VERSION ""

NS_ :

BS_:

BU_: APIM_CISM APIM ESPM DSP FCIMB RACM_RCIM HUD_ADV WCM TRM_ITRM ACM GWM _delete IPC GENERIC TSTR

BO_ 412 LBClient2_Request_Signals: 8 APIM
 SG_ LBC2_StartItemInd : 55|16@0+ (1,0) [0|65535] "unitless"  ACM
 SG_ LBC2_SetListServ : 47|8@0+ (1,0) [0|255] "unitless"  ACM
 SG_ LBC2_Opcode : 39|2@0+ (1,0) [0|3] "SED"  ACM
 SG_ LBC2_NbrOfItems : 37|6@0+ (1,0) [0|63] "unitless"  ACM
 SG_ LBC2_ItemIndex : 23|16@0+ (1,0) [0|65535] "unitless"  ACM
 SG_ LBC2_ActiveListID : 7|16@0+ (1,0) [0|65535] "unitless"  ACM

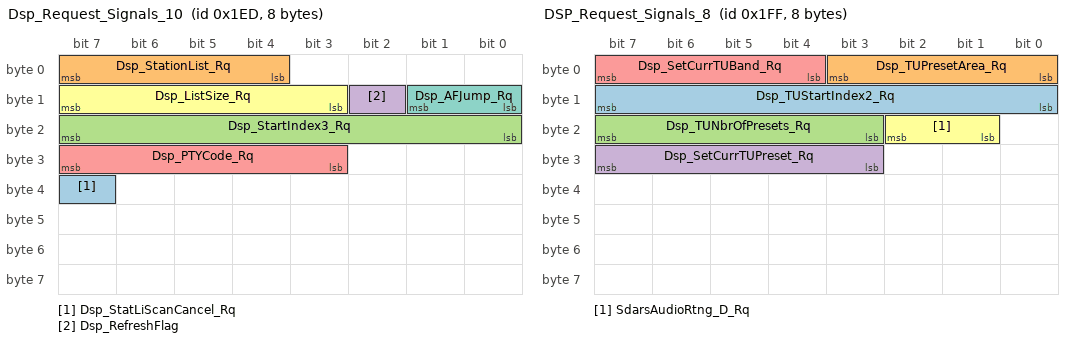
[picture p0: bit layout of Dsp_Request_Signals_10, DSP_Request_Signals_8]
BO_ 493 Dsp_Request_Signals_10: 8 APIM
 SG_ Dsp_StatLiScanCancel_Rq : 39|1@0+ (1,0) [0|1] "SED"  ACM
 SG_ Dsp_StationList_Rq : 7|4@0+ (1,0) [0|15] "SED"  ACM
 SG_ Dsp_StartIndex3_Rq : 23|8@0+ (1,0) [0|255] "unitless"  ACM
 SG_ Dsp_RefreshFlag : 10|1@0+ (1,0) [0|1] "SED"  ACM
 SG_ Dsp_PTYCode_Rq : 31|5@0+ (1,0) [0|31] "SED"  ACM
 SG_ Dsp_ListSize_Rq : 15|5@0+ (1,0) [0|31] "SED"  ACM
 SG_ Dsp_AFJump_Rq : 9|2@0+ (1,0) [0|3] "SED"  ACM

BO_ 511 DSP_Request_Signals_8: 8 APIM
 SG_ Dsp_TUStartIndex2_Rq : 15|8@0+ (1,0) [0|255] "unitless"  ACM
 SG_ Dsp_TUPresetArea_Rq : 3|4@0+ (1,0) [0|15] "SED"  ACM
 SG_ Dsp_TUNbrOfPresets_Rq : 23|5@0+ (1,0) [0|30] "SED"  ACM
 SG_ Dsp_SetCurrTUPreset_Rq : 31|5@0+ (1,0) [0|31] "SED"  APIM,ACM
 SG_ Dsp_SetCurrTUBand_Rq : 7|4@0+ (1,0) [0|15] "SED"  ACM
 SG_ SdarsAudioRtng_D_Rq : 18|2@0+ (1,0) [0|3] "SED"  ACM

BO_ 257 MFD_Request_Signals1: 8 APIM
 SG_ MFD_SetTagMode : 39|2@0+ (1,0) [0|3] "SED"  ACM
 SG_ MFD_SetRBDSMode : 47|2@0+ (1,0) [0|3] "SED"  ACM
 SG_ MFD_SetHDModeRq : 31|2@0+ (1,0) [0|3] "SED"  ACM
 SG_ MFD_GetTagInfo : 7|4@0+ (1,0) [0|15] "day"  ACM

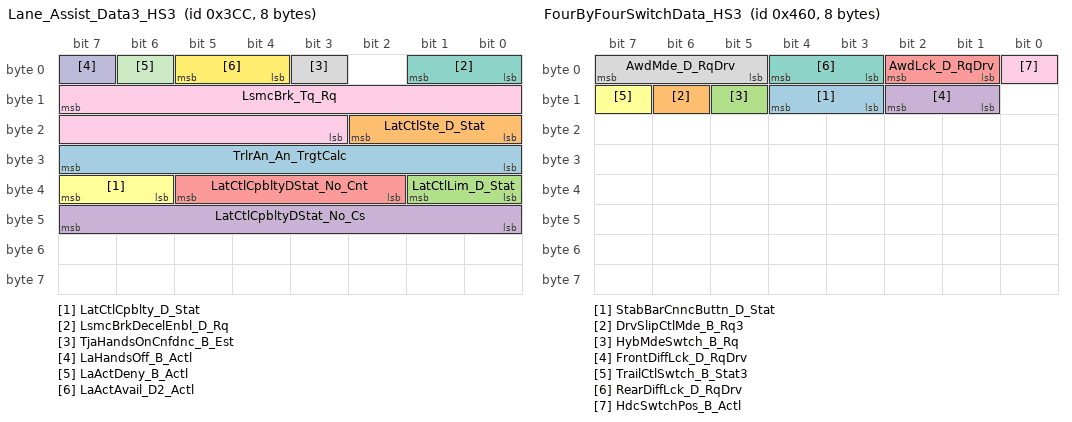
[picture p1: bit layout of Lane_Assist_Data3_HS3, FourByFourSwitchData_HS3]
BO_ 972 Lane_Assist_Data3_HS3: 8 GWM
 SG_ TrlrAn_An_TrgtCalc : 31|8@0+ (1,-128) [-128|127] "degrees" Vector__XXX
 SG_ LatCtlSte_D_Stat : 18|3@0+ (1,0) [0|7] "SED" Vector__XXX
 SG_ LatCtlLim_D_Stat : 33|2@0+ (1,0) [0|3] "SED" Vector__XXX
 SG_ LatCtlCpbltyDStat_No_Cs : 47|8@0+ (1,0) [0|255] "unitless" Vector__XXX
 SG_ LatCtlCpbltyDStat_No_Cnt : 37|4@0+ (1,0) [0|15] "unitless" Vector__XXX
 SG_ LatCtlCpblty_D_Stat : 39|2@0+ (1,0) [0|3] "SED" Vector__XXX
 SG_ LsmcBrkDecelEnbl_D_Rq : 1|2@0+ (1,0) [0|3] "SED" Vector__XXX
 SG_ TjaHandsOnCnfdnc_B_Est : 3|1@0+ (1,0) [0|1] "SED" Vector__XXX
 SG_ LsmcBrk_Tq_Rq : 15|13@0+ (4,0) [0|32764] "Nm" Vector__XXX
 SG_ LaHandsOff_B_Actl : 7|1@0+ (1,0) [0|1] "SED"  IPC
 SG_ LaActDeny_B_Actl : 6|1@0+ (1,0) [0|1] "SED"  IPC
 SG_ LaActAvail_D2_Actl : 5|2@0+ (1,0) [0|3] "SED" Vector__XXX

BO_ 1120 FourByFourSwitchData_HS3: 8 GWM
 SG_ StabBarCnncButtn_D_Stat : 12|2@0+ (1,0) [0|3] "SED" Vector__XXX
 SG_ DrvSlipCtlMde_B_Rq3 : 14|1@0+ (1,0) [0|1] "SED" Vector__XXX
 SG_ HybMdeSwtch_B_Rq : 13|1@0+ (1,0) [0|1] "SED" Vector__XXX
 SG_ FrontDiffLck_D_RqDrv : 10|2@0+ (1,0) [0|3] "SED" Vector__XXX
 SG_ AwdLck_D_RqDrv : 2|2@0+ (1,0) [0|3] "SED" Vector__XXX
 SG_ TrailCtlSwtch_B_Stat3 : 15|1@0+ (1,0) [0|1] "SED" Vector__XXX
 SG_ RearDiffLck_D_RqDrv : 4|2@0+ (1,0) [0|3] "SED"  IPC
 SG_ AwdMde_D_RqDrv : 7|3@0+ (1,0) [0|7] "SED"  IPC
 SG_ HdcSwtchPos_B_Actl : 0|1@0+ (1,0) [0|1] "SED" Vector__XXX

BO_ 1087 Powertrain_Data_5_HS3: 8 GWM
 SG_ DcacFaltMsgTxt_D2_Rq : 39|6@0+ (1,0) [0|63] "SED"  APIM,IPC,APIM_CISM
 SG_ StopStrtCstm_D_Stat : 26|2@0+ (1,0) [0|3] "SED" Vector__XXX
 SG_ SelDrvMdeCstmPt_D_Stat : 31|5@0+ (1,0) [0|31] "SED" Vector__XXX
 SG_ RepaLcGrdInhbt_B_Stat : 17|1@0+ (1,0) [0|1] "SED" Vector__XXX
 SG_ ClimtCool_D_RqPt : 19|2@0+ (1,0) [0|3] "SED" Vector__XXX
 SG_ StrtInGearMsgTxt_D_Rq : 23|4@0+ (1,0) [0|15] "SED"  IPC
 SG_ IgnOffInhbt_B_Stat : 9|1@0+ (1,0) [0|1] "SED" Vector__XXX
 SG_ BtsiShifInhbt_B_RqPt : 8|1@0+ (1,0) [0|1] "SED" Vector__XXX
 SG_ FapLcInhbt_B_Rq : 1|1@0+ (1,0) [0|1] "SED" Vector__XXX
 SG_ FapLcStopHold_B_Rq : 2|1@0+ (1,0) [0|1] "SED" Vector__XXX
 SG_ FapLcPrchgBrk_B_Rq : 3|1@0+ (1,0) [0|1] "SED" Vector__XXX
 SG_ FapLcObstcl_B_Stat : 4|1@0+ (1,0) [0|1] "SED" Vector__XXX
 SG_ FapLcMaxGrdInhbt_B_Stat : 5|1@0+ (1,0) [0|1] "SED" Vector__XXX
 SG_ FapLcMaxGrdAbrt_B_Stat : 6|1@0+ (1,0) [0|1] "SED" Vector__XXX
 SG_ FapLcActv_B_Stat : 7|1@0+ (1,0) [0|1] "SED" Vector__XXX
 SG_ BattRgenLoDChrg_D_RqEng : 13|2@0+ (1,0) [0|3] "SED" Vector__XXX
 SG_ BattRgenLoChrg_D_RqEng : 15|2@0+ (1,0) [0|3] "SED" Vector__XXX
 SG_ AdasLcObtclAbrt_B_Stat : 0|1@0+ (1,0) [0|1] "SED" Vector__XXX
 SG_ AirDamPos_D_Stat : 11|2@0+ (1,0) [0|3] "SED" Vector__XXX

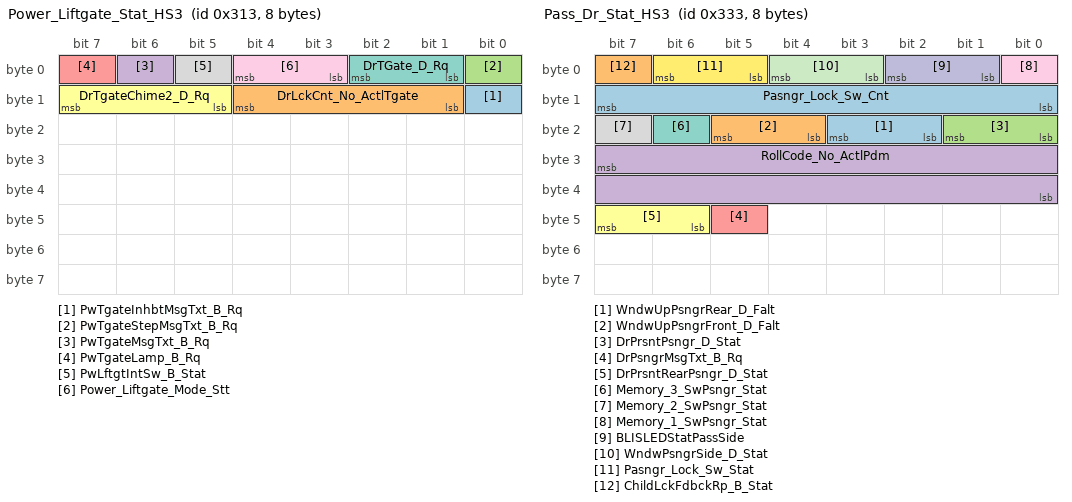
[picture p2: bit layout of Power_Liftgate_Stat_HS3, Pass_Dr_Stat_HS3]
BO_ 787 Power_Liftgate_Stat_HS3: 8 GWM
 SG_ PwTgateInhbtMsgTxt_B_Rq : 8|1@0+ (1,0) [0|1] "SED"  IPC
 SG_ DrLckCnt_No_ActlTgate : 12|4@0+ (1,0) [0|15] "unitless" Vector__XXX
 SG_ PwTgateStepMsgTxt_B_Rq : 0|1@0+ (1,0) [0|1] "SED"  APIM,APIM_CISM,IPC
 SG_ PwTgateMsgTxt_B_Rq : 6|1@0+ (1,0) [0|1] "SED"  APIM,APIM_CISM,IPC
 SG_ PwTgateLamp_B_Rq : 7|1@0+ (1,0) [0|1] "SED"  APIM,APIM_CISM,IPC
 SG_ DrTgateChime2_D_Rq : 15|3@0+ (1,0) [0|7] "SED"  APIM,APIM_CISM,IPC
 SG_ DrTGate_D_Rq : 2|2@0+ (1,0) [0|3] "SED" Vector__XXX
 SG_ PwLftgtIntSw_B_Stat : 5|1@0+ (1,0) [0|1] "SED"  APIM,APIM_CISM
 SG_ Power_Liftgate_Mode_Stt : 4|2@0+ (1,0) [0|3] "SED"  APIM,APIM_CISM,IPC

BO_ 819 Pass_Dr_Stat_HS3: 8 GWM
 SG_ WndwUpPsngrRear_D_Falt : 19|2@0+ (1,0) [0|3] "SED" Vector__XXX
 SG_ WndwUpPsngrFront_D_Falt : 21|2@0+ (1,0) [0|3] "SED" Vector__XXX
 SG_ DrPrsntPsngr_D_Stat : 17|2@0+ (1,0) [0|3] "SED"  APIM,APIM_CISM,IPC
 SG_ RollCode_No_ActlPdm : 31|16@0+ (1,0) [0|65535] "unitless" Vector__XXX
 SG_ DrPsngrMsgTxt_B_Rq : 45|1@0+ (1,0) [0|1] "SED"  IPC
 SG_ DrPrsntRearPsngr_D_Stat : 47|2@0+ (1,0) [0|3] "SED"  APIM,APIM_CISM,IPC
 SG_ Memory_3_SwPsngr_Stat : 22|1@0+ (1,0) [0|1] "SED" Vector__XXX
 SG_ Memory_2_SwPsngr_Stat : 23|1@0+ (1,0) [0|1] "SED" Vector__XXX
 SG_ Memory_1_SwPsngr_Stat : 0|1@0+ (1,0) [0|1] "SED" Vector__XXX
 SG_ BLISLEDStatPassSide : 2|2@0+ (1,0) [0|3] "SED" Vector__XXX
 SG_ WndwPsngrSide_D_Stat : 4|2@0+ (1,0) [0|3] "SED" Vector__XXX
 SG_ Pasngr_Lock_Sw_Stat : 6|2@0+ (1,0) [0|3] "SED" Vector__XXX
 SG_ Pasngr_Lock_Sw_Cnt : 15|8@0+ (1,0) [0|255] "Cnt" Vector__XXX
 SG_ ChildLckFdbckRp_B_Stat : 7|1@0+ (1,0) [0|1] "SED" Vector__XXX

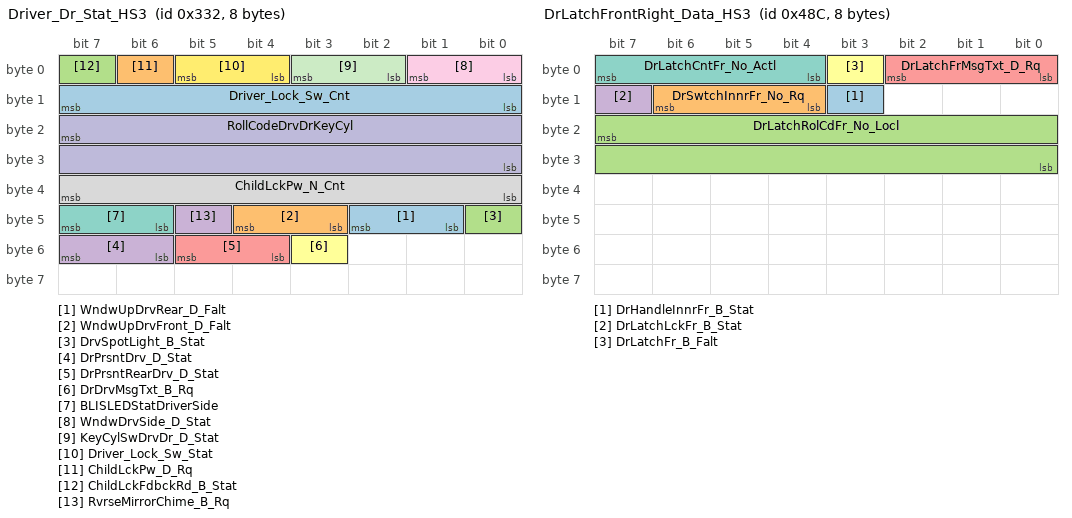
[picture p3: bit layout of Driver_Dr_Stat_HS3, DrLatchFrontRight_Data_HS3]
BO_ 818 Driver_Dr_Stat_HS3: 8 GWM
 SG_ WndwUpDrvRear_D_Falt : 42|2@0+ (1,0) [0|3] "SED" Vector__XXX
 SG_ WndwUpDrvFront_D_Falt : 44|2@0+ (1,0) [0|3] "SED" Vector__XXX
 SG_ DrvSpotLight_B_Stat : 40|1@0+ (1,0) [0|1] "SED" Vector__XXX
 SG_ DrPrsntDrv_D_Stat : 55|2@0+ (1,0) [0|3] "SED"  APIM,APIM_CISM,IPC
 SG_ DrPrsntRearDrv_D_Stat : 53|2@0+ (1,0) [0|3] "SED"  APIM,APIM_CISM,IPC
 SG_ DrDrvMsgTxt_B_Rq : 51|1@0+ (1,0) [0|1] "SED"  IPC
 SG_ BLISLEDStatDriverSide : 47|2@0+ (1,0) [0|3] "SED" Vector__XXX
 SG_ ChildLckPw_N_Cnt : 39|8@0+ (1,0) [0|255] "unitless" Vector__XXX
 SG_ WndwDrvSide_D_Stat : 1|2@0+ (1,0) [0|3] "SED" Vector__XXX
 SG_ RollCodeDrvDrKeyCyl : 23|16@0+ (1,0) [0|65535] "unitless" Vector__XXX
 SG_ KeyCylSwDrvDr_D_Stat : 3|2@0+ (1,0) [0|3] "SED" Vector__XXX
 SG_ Driver_Lock_Sw_Stat : 5|2@0+ (1,0) [0|3] "SED" Vector__XXX
 SG_ Driver_Lock_Sw_Cnt : 15|8@0+ (1,0) [0|255] "Cnt" Vector__XXX
 SG_ ChildLckPw_D_Rq : 6|1@0+ (1,0) [0|1] "SED" Vector__XXX
 SG_ ChildLckFdbckRd_B_Stat : 7|1@0+ (1,0) [0|1] "SED" Vector__XXX
 SG_ RvrseMirrorChime_B_Rq : 45|1@0+ (1,0) [0|1] "SED"  IPC

BO_ 1164 DrLatchFrontRight_Data_HS3: 8 GWM
 SG_ DrHandleInnrFr_B_Stat : 11|1@0+ (1,0) [0|1] "SED" Vector__XXX
 SG_ DrSwtchInnrFr_No_Rq : 14|3@0+ (1,0) [0|7] "unitless" Vector__XXX
 SG_ DrLatchRolCdFr_No_Locl : 23|16@0+ (1,0) [0|65535] "unitless" Vector__XXX
 SG_ DrLatchLckFr_B_Stat : 15|1@0+ (1,0) [0|1] "SED"  APIM,APIM_CISM
 SG_ DrLatchFrMsgTxt_D_Rq : 2|3@0+ (1,0) [0|7] "SED"  IPC
 SG_ DrLatchFr_B_Falt : 3|1@0+ (1,0) [0|1] "SED" Vector__XXX
 SG_ DrLatchCntFr_No_Actl : 7|4@0+ (1,0) [0|15] "unitless" Vector__XXX

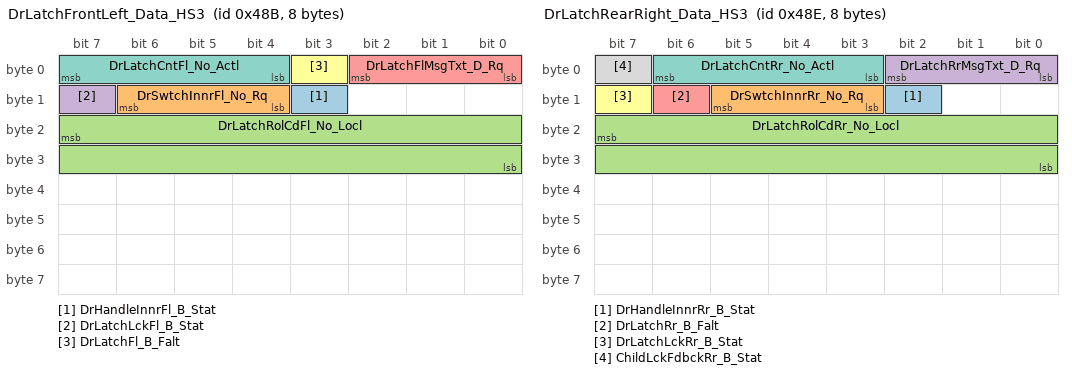
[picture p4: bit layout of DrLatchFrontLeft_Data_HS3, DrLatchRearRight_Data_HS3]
BO_ 1163 DrLatchFrontLeft_Data_HS3: 8 GWM
 SG_ DrHandleInnrFl_B_Stat : 11|1@0+ (1,0) [0|1] "SED" Vector__XXX
 SG_ DrSwtchInnrFl_No_Rq : 14|3@0+ (1,0) [0|7] "unitless" Vector__XXX
 SG_ DrLatchRolCdFl_No_Locl : 23|16@0+ (1,0) [0|65535] "unitless" Vector__XXX
 SG_ DrLatchLckFl_B_Stat : 15|1@0+ (1,0) [0|1] "SED"  APIM,APIM_CISM
 SG_ DrLatchFlMsgTxt_D_Rq : 2|3@0+ (1,0) [0|7] "SED"  IPC
 SG_ DrLatchFl_B_Falt : 3|1@0+ (1,0) [0|1] "SED" Vector__XXX
 SG_ DrLatchCntFl_No_Actl : 7|4@0+ (1,0) [0|15] "unitless" Vector__XXX

BO_ 1166 DrLatchRearRight_Data_HS3: 8 GWM
 SG_ DrHandleInnrRr_B_Stat : 10|1@0+ (1,0) [0|1] "SED" Vector__XXX
 SG_ DrSwtchInnrRr_No_Rq : 13|3@0+ (1,0) [0|7] "unitless" Vector__XXX
 SG_ DrLatchRolCdRr_No_Locl : 23|16@0+ (1,0) [0|65535] "unitless" Vector__XXX
 SG_ DrLatchRrMsgTxt_D_Rq : 2|3@0+ (1,0) [0|7] "SED"  IPC
 SG_ DrLatchRr_B_Falt : 14|1@0+ (1,0) [0|1] "SED" Vector__XXX
 SG_ DrLatchLckRr_B_Stat : 15|1@0+ (1,0) [0|1] "SED"  APIM,APIM_CISM
 SG_ DrLatchCntRr_No_Actl : 6|4@0+ (1,0) [0|15] "unitless" Vector__XXX
 SG_ ChildLckFdbckRr_B_Stat : 7|1@0+ (1,0) [0|1] "SED" Vector__XXX

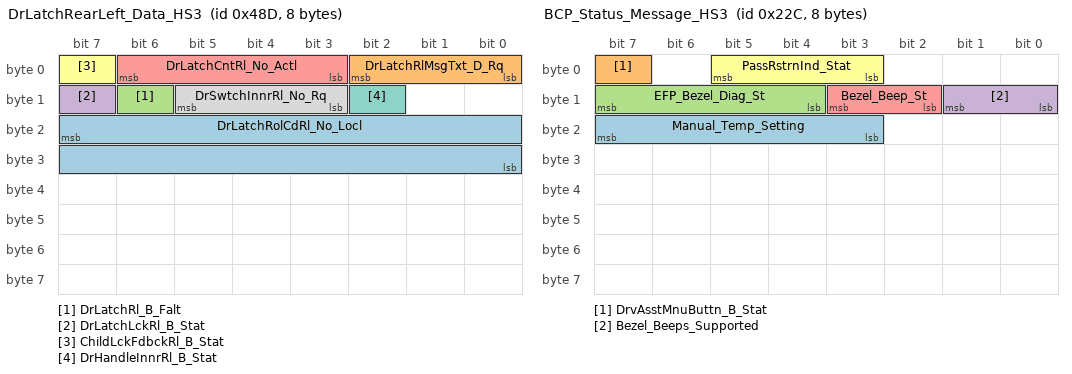
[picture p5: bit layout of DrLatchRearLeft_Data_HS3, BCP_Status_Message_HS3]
BO_ 1165 DrLatchRearLeft_Data_HS3: 8 GWM
 SG_ DrLatchRolCdRl_No_Locl : 23|16@0+ (1,0) [0|65535] "unitless" Vector__XXX
 SG_ DrLatchRlMsgTxt_D_Rq : 2|3@0+ (1,0) [0|7] "SED"  IPC
 SG_ DrLatchRl_B_Falt : 14|1@0+ (1,0) [0|1] "SED" Vector__XXX
 SG_ DrLatchLckRl_B_Stat : 15|1@0+ (1,0) [0|1] "SED"  APIM,APIM_CISM
 SG_ DrLatchCntRl_No_Actl : 6|4@0+ (1,0) [0|15] "unitless" Vector__XXX
 SG_ ChildLckFdbckRl_B_Stat : 7|1@0+ (1,0) [0|1] "SED" Vector__XXX
 SG_ DrHandleInnrRl_B_Stat : 10|1@0+ (1,0) [0|1] "SED" Vector__XXX
 SG_ DrSwtchInnrRl_No_Rq : 13|3@0+ (1,0) [0|7] "unitless" Vector__XXX

BO_ 556 BCP_Status_Message_HS3: 8 GWM
 SG_ Manual_Temp_Setting : 23|5@0+ (1,0) [0|31] "SED"  APIM,ACM,APIM_CISM
 SG_ DrvAsstMnuButtn_B_Stat : 7|1@0+ (1,0) [0|1] "SED"  APIM,APIM_CISM
 SG_ EFP_Bezel_Diag_St : 15|4@0+ (1,0) [0|15] "SED"  APIM,APIM_CISM
 SG_ Bezel_Beeps_Supported : 9|2@0+ (1,0) [0|3] "SED"  APIM,APIM_CISM
 SG_ Bezel_Beep_St : 11|2@0+ (1,0) [0|3] "SED"  APIM,APIM_CISM
 SG_ PassRstrnInd_Stat : 5|3@0+ (1,0) [0|7] "SED"  GENERIC

BO_ 1101 LockControlData_HS3: 8 GWM
 SG_ AwdLckLamp_D_Rq : 13|2@0+ (1,0) [0|3] "SED"  IPC
 SG_ Ptu_Te_Actl : 7|8@0+ (1,-50) [-50|204] "degC" Vector__XXX
 SG_ PtLatchActv_B_RqAwd : 14|1@0+ (1,0) [0|1] "SED" Vector__XXX
 SG_ PtuFanOn_B_Rq : 15|1@0+ (1,0) [0|1] "SED" Vector__XXX
 SG_ RearDiffLckLamp_D_Rq3 : 11|2@0+ (1,0) [0|3] "SED"  IPC

BO_ 130 EPAS_INFO_HS3: 8 GWM
 SG_ TrlrHitchLamp_D_Rqst : 24|1@0+ (1,0) [0|1] "SED" Vector__XXX
 SG_ VehVTrlrAid_B_Rq : 25|1@0+ (1,0) [0|1] "SED" Vector__XXX
 SG_ SteEffort_D_Stat : 52|3@0+ (1,0) [0|7] "SED"  IPC
 SG_ Veh_V_RqMxTrlrAid : 63|8@0+ (0.1,0) [0|25.5] "km/h" Vector__XXX
 SG_ DrvSteActv_B_Stat : 10|1@0+ (1,0) [0|1] "SED" Vector__XXX
 SG_ DrvSte_Tq_Actl : 47|8@0+ (0.0625,-8) [-8|7.8125] "Nm" Vector__XXX
 SG_ SteMdule_D_Stat : 55|3@0+ (1,0) [0|7] "SED" Vector__XXX
 SG_ SteMdule_U_Meas : 39|8@0+ (0.05,6) [6|18.7] "Volts" Vector__XXX
 SG_ SteMdule_I_Est : 21|12@0+ (0.05,-64) [-64|140.7] "Amps" Vector__XXX
 SG_ EPAS_Failure : 9|2@0+ (1,0) [0|3] "SED"  IPC
 SG_ SteeringColumnTorque : 7|8@0+ (0.0625,-8) [-8|7.8125] "Nm" Vector__XXX
 SG_ SAPPAngleControlStat6 : 15|1@0+ (1,0) [0|1] "SED" Vector__XXX
 SG_ SAPPAngleControlStat5 : 14|1@0+ (1,0) [0|1] "SED" Vector__XXX
 SG_ SAPPAngleControlStat4 : 13|1@0+ (1,0) [0|1] "SED" Vector__XXX
 SG_ SAPPAngleControlStat3 : 12|1@0+ (1,0) [0|1] "SED" Vector__XXX
 SG_ SAPPAngleControlStat2 : 11|1@0+ (1,0) [0|1] "SED" Vector__XXX
 SG_ SAPPAngleControlStat1 : 23|2@0+ (1,0) [0|3] "SED" Vector__XXX

BO_ 713 SDARS_RDISP_WORD_Rx: 8 APIM
 SG_ SDARS_RDISP_WORD_Rx : 7|64@0+ (1,0) [0|1.84467440737096E+019] "unitless"  ACM

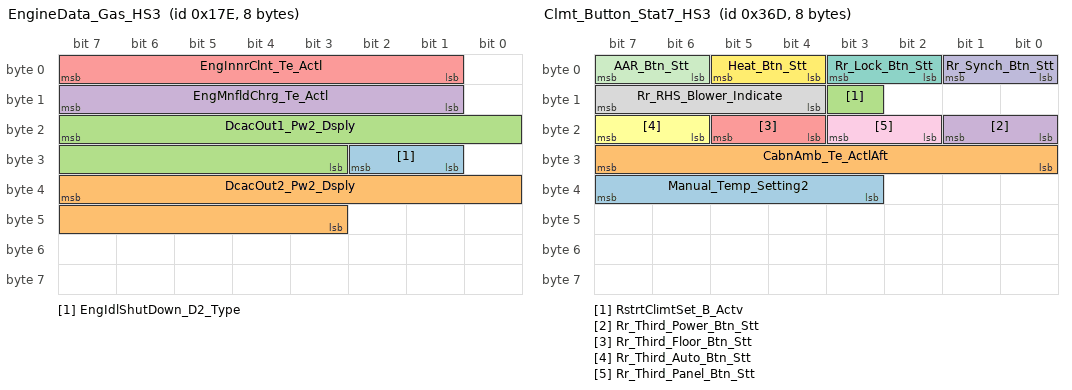
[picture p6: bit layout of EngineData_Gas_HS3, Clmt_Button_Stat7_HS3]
BO_ 382 EngineData_Gas_HS3: 8 GWM
 SG_ EngIdlShutDown_D2_Type : 26|2@0+ (1,0) [0|3] "SED"  APIM,APIM_CISM,IPC
 SG_ DcacOut2_Pw2_Dsply : 39|13@0+ (1,0) [0|8189] "watts"  APIM,APIM_CISM
 SG_ DcacOut1_Pw2_Dsply : 23|13@0+ (1,0) [0|8189] "watts"  APIM,APIM_CISM
 SG_ EngMnfldChrg_Te_Actl : 15|7@0+ (1,-20) [-20|105] "degC"  IPC
 SG_ EngInnrClnt_Te_Actl : 7|7@0+ (1,50) [50|175] "degC"  IPC

BO_ 877 Clmt_Button_Stat7_HS3: 8 GWM
 SG_ Manual_Temp_Setting2 : 39|5@0+ (1,0) [0|31] "SED"  APIM,APIM_CISM
 SG_ CabnAmb_Te_ActlAft : 31|8@0+ (0.5,-57) [-57|70] "degC" Vector__XXX
 SG_ RstrtClimtSet_B_Actv : 11|1@0+ (1,0) [0|1] "SED" Vector__XXX
 SG_ Rr_Third_Power_Btn_Stt : 17|2@0+ (1,0) [0|3] "SED"  APIM,APIM_CISM,RACM_RCIM
 SG_ Rr_Third_Floor_Btn_Stt : 21|2@0+ (1,0) [0|3] "SED"  APIM,APIM_CISM,RACM_RCIM
 SG_ Rr_Third_Auto_Btn_Stt : 23|2@0+ (1,0) [0|3] "SED"  APIM,APIM_CISM,RACM_RCIM
 SG_ Rr_Lock_Btn_Stt : 3|2@0+ (1,0) [0|3] "SED"  APIM,APIM_CISM,RACM_RCIM
 SG_ Rr_RHS_Blower_Indicate : 15|4@0+ (1,0) [0|15] "SED"  APIM,APIM_CISM,RACM_RCIM
 SG_ Rr_Third_Panel_Btn_Stt : 19|2@0+ (1,0) [0|3] "SED"  APIM,APIM_CISM,RACM_RCIM
 SG_ Rr_Synch_Btn_Stt : 1|2@0+ (1,0) [0|3] "SED"  APIM,APIM_CISM
 SG_ AAR_Btn_Stt : 7|2@0+ (1,0) [0|3] "SED"  APIM,APIM_CISM,FCIMB
 SG_ Heat_Btn_Stt : 5|2@0+ (1,0) [0|3] "SED"  APIM,APIM_CISM,FCIMB

BO_ 600 APIM_RFA_BLEM_Tx: 8 APIM
 SG_ APIM_RFA_BLEM_Tx : 7|64@0+ (1,0) [0|1.84467440737096E+019] "unitless"  GWM

BO_ 708 TMCSrvr_TMCClnt_WORD_Tx: 8 ACM
 SG_ TMCSrvr_TMCClnt_WORD_Tx : 7|64@0+ (1,0) [0|1.84467440737096E+019] "unitless"  APIM

BO_ 414 LBS2_Indication_Signals: 8 ACM
 SG_ LBS2_ListStatus : 57|2@0+ (1,0) [0|3] "SED"  APIM,RACM_RCIM,IPC
 SG_ LBS2_ParentID : 31|16@0+ (1,0) [0|65535] "unitless"  APIM,RACM_RCIM,IPC
 SG_ LBS2_ListServer : 7|8@0+ (1,0) [0|255] "unitless"  APIM,RACM_RCIM,IPC
 SG_ LBS2_ListID : 15|16@0+ (1,0) [0|65535] "unitless"  APIM,RACM_RCIM,IPC
 SG_ LBS2_EntryIndex : 47|16@0+ (1,0) [0|65535] "unitless"  APIM,RACM_RCIM,IPC

BO_ 619 PaakCtlData2_HS3: 8 GWM
 SG_ KeyPadCodeProg_D_Rq : 50|3@0+ (1,0) [0|7] "SED" Vector__XXX
 SG_ PaakCnnct_D_Stat : 52|2@0+ (1,0) [0|3] "SED"  APIM,APIM_CISM
 SG_ PaakCtlActv_No_Actl : 42|6@0+ (1,0) [0|63] "unitless" Vector__XXX
 SG_ PaakCtlActv_D_Rq : 47|5@0+ (1,0) [0|31] "SED" Vector__XXX
 SG_ PaakCtlActvData_No_Actl : 7|40@0+ (1,0) [0|1099511627775] "unitless" Vector__XXX

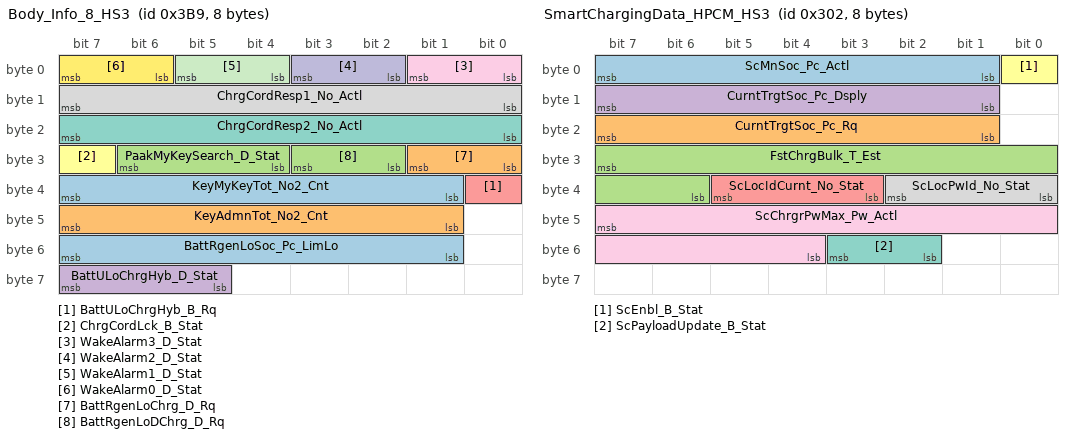
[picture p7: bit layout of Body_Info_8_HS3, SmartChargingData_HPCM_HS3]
BO_ 953 Body_Info_8_HS3: 8 GWM
 SG_ KeyMyKeyTot_No2_Cnt : 39|7@0+ (1,0) [0|127] "unitless"  APIM,APIM_CISM
 SG_ KeyAdmnTot_No2_Cnt : 47|7@0+ (1,0) [0|127] "unitless"  APIM,APIM_CISM
 SG_ PaakMyKeySearch_D_Stat : 30|3@0+ (1,0) [0|7] "SED"  APIM,APIM_CISM
 SG_ BattULoChrgHyb_D_Stat : 63|3@0+ (1,0) [0|7] "SED" Vector__XXX
 SG_ BattULoChrgHyb_B_Rq : 32|1@0+ (1,0) [0|1] "SED" Vector__XXX
 SG_ ChrgCordLck_B_Stat : 31|1@0+ (1,0) [0|1] "SED" Vector__XXX
 SG_ ChrgCordResp2_No_Actl : 23|8@0+ (1,0) [0|255] "unitless" Vector__XXX
 SG_ ChrgCordResp1_No_Actl : 15|8@0+ (1,0) [0|255] "unitless" Vector__XXX
 SG_ WakeAlarm3_D_Stat : 1|2@0+ (1,0) [0|3] "SED" Vector__XXX
 SG_ WakeAlarm2_D_Stat : 3|2@0+ (1,0) [0|3] "SED"  TRM_ITRM
 SG_ WakeAlarm1_D_Stat : 5|2@0+ (1,0) [0|3] "SED" Vector__XXX
 SG_ WakeAlarm0_D_Stat : 7|2@0+ (1,0) [0|3] "SED" Vector__XXX
 SG_ BattRgenLoSoc_Pc_LimLo : 55|7@0+ (1,0) [0|100] "percent" Vector__XXX
 SG_ BattRgenLoChrg_D_Rq : 25|2@0+ (1,0) [0|3] "SED" Vector__XXX
 SG_ BattRgenLoDChrg_D_Rq : 27|2@0+ (1,0) [0|3] "SED" Vector__XXX

BO_ 985 IPMA_Data2_HS3: 8 GWM
 SG_ LongCtrlEnblDRq_No_Cs : 63|8@0+ (1,0) [0|255] "Unitless" Vector__XXX
 SG_ LongCtrlEnblDRq_No_Cnt : 29|4@0+ (1,0) [0|15] "Unitless" Vector__XXX
 SG_ ClrExitAsst_D_Stat : 39|2@0+ (1,0) [0|3] "SED"  APIM,APIM_CISM,IPC
 SG_ ClrExitAsstMsgTxt_D_Rq : 52|4@0+ (1,0) [0|15] "SED"  IPC
 SG_ ClrExitAsstChime_D_Rq : 55|3@0+ (1,0) [0|7] "SED"  IPC
 SG_ AdbDrvSide_B_Stat : 35|1@0+ (1,0) [0|1] "SED" Vector__XXX
 SG_ LcwaMsgTxt_D_Stat : 37|2@0+ (1,0) [0|3] "SED"  IPC
 SG_ AdbDividedRoad_B_Stat : 30|1@0+ (1,0) [0|1] "SED" Vector__XXX
 SG_ IsaVLimUnit_D_Rq : 15|2@0+ (1,0) [0|3] "SED" Vector__XXX
 SG_ SblmYieldScnr_B_Stat : 31|1@0+ (1,0) [0|1] "SED" Vector__XXX
 SG_ SblmStopScnr_B_Stat : 8|1@0+ (1,0) [0|1] "SED" Vector__XXX
 SG_ IsaVLim_D_Rq : 7|8@0+ (1,0) [0|255] "SED" Vector__XXX
 SG_ IaccVLimUnit_D_Rq : 11|2@0+ (1,0) [0|3] "SED" Vector__XXX
 SG_ IaccVLim_D_Rq : 23|8@0+ (1,0) [0|255] "SED" Vector__XXX
 SG_ DasAlrtInfo_D_Dsply : 13|2@0+ (1,0) [0|3] "SED"  APIM,APIM_CISM
 SG_ SblmRndAbtScnr_B_Stat : 9|1@0+ (1,0) [0|1] "SED" Vector__XXX
 SG_ LongCtrlEnbl_D_Rq : 42|3@0+ (1,0) [0|7] "SED" Vector__XXX
 SG_ SblmPedCrossScnr_B_Stat : 33|1@0+ (1,0) [0|1] "SED" Vector__XXX
 SG_ TsrRegionTxt_D_Stat : 47|5@0+ (1,0) [0|31] "SED"  HUD_ADV,IPC
 SG_ LdwChime_B_Rq : 34|1@0+ (1,0) [0|1] "SED"  IPC
 SG_ PwSustnAdas_B_Rq : 48|1@0+ (1,0) [0|1] "SED" Vector__XXX
 SG_ LongCtrlBrk_D_Rq : 25|2@0+ (1,0) [0|3] "SED" Vector__XXX

BO_ 770 SmartChargingData_HPCM_HS3: 8 GWM
 SG_ ScMnSoc_Pc_Actl : 7|7@0+ (1,0) [0|127] "percent"  APIM,APIM_CISM
 SG_ CurntTrgtSoc_Pc_Rq : 23|7@0+ (1,0) [0|127] "percent"  GENERIC
 SG_ FstChrgBulk_T_Est : 31|10@0+ (1,0) [0|1023] "minute"  APIM,APIM_CISM,IPC
 SG_ CurntTrgtSoc_Pc_Dsply : 15|7@0+ (1,0) [0|127] "percent"  APIM,APIM_CISM,IPC
 SG_ ScLocIdCurnt_No_Stat : 37|3@0+ (1,0) [0|7] "unitless"  APIM,APIM_CISM
 SG_ ScEnbl_B_Stat : 0|1@0+ (1,0) [0|1] "SED"  APIM,APIM_CISM
 SG_ ScPayloadUpdate_B_Stat : 51|2@0+ (1,0) [0|3] "SED"  GENERIC
 SG_ ScLocPwId_No_Stat : 34|3@0+ (1,0) [0|7] "unitless"  GENERIC
 SG_ ScChrgrPwMax_Pw_Actl : 47|12@0+ (50,0) [0|204700] "watts"  GENERIC

BO_ 716 TMCSrvr_TMCClient_WORD_Rx: 8 APIM
 SG_ TMCSrvr_TMCClnt_WORD_Rx : 7|64@0+ (1,0) [0|1.84467440737096E+019] "unitless"  ACM

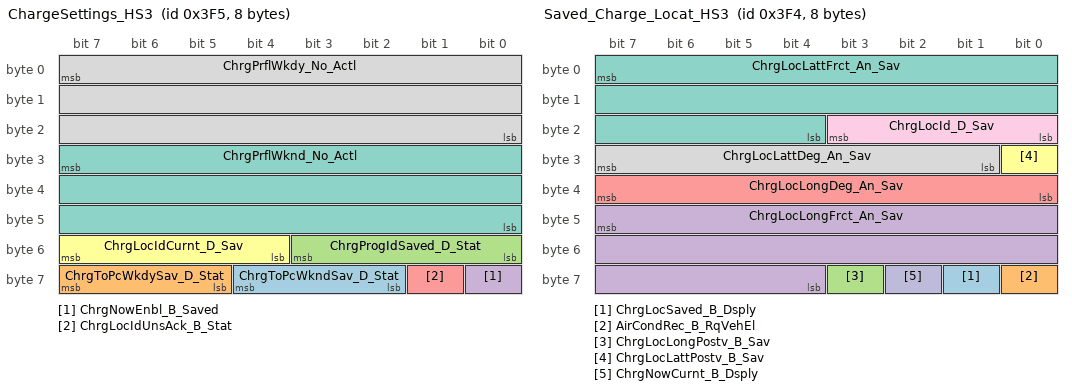
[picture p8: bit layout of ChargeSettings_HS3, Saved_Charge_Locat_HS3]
BO_ 1013 ChargeSettings_HS3: 8 GWM
 SG_ ChrgToPcWkndSav_D_Stat : 60|3@0+ (1,0) [0|7] "SED"  APIM,APIM_CISM
 SG_ ChrgToPcWkdySav_D_Stat : 63|3@0+ (1,0) [0|7] "SED"  APIM,APIM_CISM
 SG_ ChrgProgIdSaved_D_Stat : 51|4@0+ (1,0) [0|15] "unitless"  APIM,APIM_CISM
 SG_ ChrgNowEnbl_B_Saved : 56|1@0+ (1,0) [0|1] "SED"  APIM,APIM_CISM
 SG_ ChrgLocIdUnsAck_B_Stat : 57|1@0+ (1,0) [0|1] "SED"  APIM,APIM_CISM
 SG_ ChrgLocIdCurnt_D_Sav : 55|4@0+ (1,0) [0|15] "unitless"  APIM,APIM_CISM,IPC
 SG_ ChrgPrflWknd_No_Actl : 31|24@0+ (1,0) [0|16777215] "unitless"  APIM,APIM_CISM
 SG_ ChrgPrflWkdy_No_Actl : 7|24@0+ (1,0) [0|16777215] "unitless"  APIM,APIM_CISM

BO_ 1012 Saved_Charge_Locat_HS3: 8 GWM
 SG_ ChrgLocSaved_B_Dsply : 57|1@0+ (1,0) [0|1] "SED"  APIM,APIM_CISM
 SG_ AirCondRec_B_RqVehEl : 56|1@0+ (1,0) [0|1] "SED" Vector__XXX
 SG_ ChrgLocLongPostv_B_Sav : 59|1@0+ (1,0) [0|1] "SED"  APIM,APIM_CISM
 SG_ ChrgLocLongFrct_An_Sav : 47|20@0+ (1E-006,0) [0|1.048575] "degrees"  APIM,APIM_CISM
 SG_ ChrgLocLongDeg_An_Sav : 39|8@0+ (1,0) [0|255] "degrees"  APIM,APIM_CISM
 SG_ ChrgLocLattPostv_B_Sav : 24|1@0+ (1,0) [0|1] "SED"  APIM,APIM_CISM
 SG_ ChrgLocLattFrct_An_Sav : 7|20@0+ (1E-006,0) [0|1.048575] "degrees"  APIM,APIM_CISM
 SG_ ChrgLocLattDeg_An_Sav : 31|7@0+ (1,0) [0|127] "unitless"  APIM,APIM_CISM
 SG_ ChrgLocId_D_Sav : 19|4@0+ (1,0) [0|15] "unitless"  APIM,APIM_CISM
 SG_ ChrgNowCurnt_B_Dsply : 58|1@0+ (1,0) [0|1] "SED"  APIM,APIM_CISM,IPC

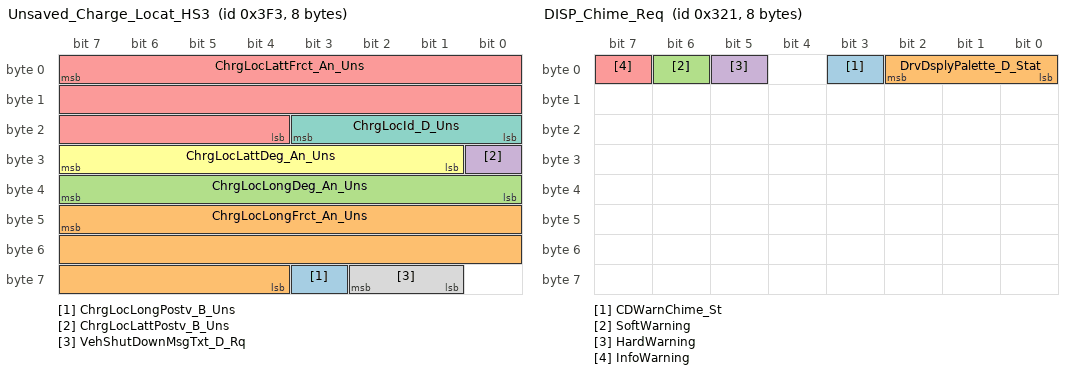
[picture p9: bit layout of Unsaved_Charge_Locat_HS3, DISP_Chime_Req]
BO_ 1011 Unsaved_Charge_Locat_HS3: 8 GWM
 SG_ ChrgLocLongPostv_B_Uns : 59|1@0+ (1,0) [0|1] "SED"  APIM,APIM_CISM
 SG_ ChrgLocLongFrct_An_Uns : 47|20@0+ (1E-006,0) [0|1.048575] "degrees"  APIM,APIM_CISM
 SG_ ChrgLocLongDeg_An_Uns : 39|8@0+ (1,0) [0|255] "degrees"  APIM,APIM_CISM
 SG_ ChrgLocLattPostv_B_Uns : 24|1@0+ (1,0) [0|1] "SED"  APIM,APIM_CISM
 SG_ ChrgLocLattFrct_An_Uns : 7|20@0+ (1E-006,0) [0|1.048575] "degrees"  APIM,APIM_CISM
 SG_ ChrgLocLattDeg_An_Uns : 31|7@0+ (1,0) [0|127] "unitless"  APIM,APIM_CISM
 SG_ ChrgLocId_D_Uns : 19|4@0+ (1,0) [0|15] "unitless"  APIM,APIM_CISM
 SG_ VehShutDownMsgTxt_D_Rq : 58|2@0+ (1,0) [0|3] "SED"  IPC

BO_ 533 APIM_Send_Signals_2: 8 APIM
 SG_ ClrExitAsstEnbl_D_RqMnu : 60|2@0+ (1,0) [0|3] "SED"  GWM
 SG_ AutoEpbZoomView_B_Stat : 32|1@0+ (1,0) [0|1] "SED"  GWM
 SG_ PaakMyKey_D_Rq : 7|2@0+ (1,0) [0|3] "SED"  GWM
 SG_ DcacPw_D_Rq : 62|2@0+ (1,0) [0|3] "SED"  GWM
 SG_ DcacPwReset_B_Rq : 63|1@0+ (1,0) [0|1] "SED"  GWM
 SG_ AutoEpbButtn_B_Stat : 19|1@0+ (1,0) [0|1] "SED"  GWM
 SG_ TrlrAidMde_D_Rq : 5|2@0+ (1,0) [0|3] "SED"  GWM
 SG_ TCU_Init_Actvtn_St : 1|2@0+ (1,0) [0|3] "SED"  GWM
 SG_ TCU_Final_Actvtn_St : 3|2@0+ (1,0) [0|3] "SED"  GWM
 SG_ LghtAmbDrvMde_D_Rq : 49|2@0+ (1,0) [0|3] "SED"  GWM
 SG_ OtaTrg_D_Stat : 41|2@0+ (1,0) [0|3] "SED"  GWM
 SG_ DcacPwLoButtn_B_Stat : 13|1@0+ (1,0) [0|1] "SED"  GWM
 SG_ DcacPwOffButtn_B_Stat : 12|1@0+ (1,0) [0|1] "SED"  GWM
 SG_ DcacPwHiButtn_B_Stat : 14|1@0+ (1,0) [0|1] "SED"  GWM
 SG_ DcacPwResetButtn_B_Stat : 11|1@0+ (1,0) [0|1] "SED"  GWM
 SG_ DcacPwButtn_B_Falt : 15|1@0+ (1,0) [0|1] "SED"  GWM
 SG_ DcacMdeButtn_B_Stat : 8|1@0+ (1,0) [0|1] "SED"  GWM
 SG_ OnbChrgGoTTouch_D_Rq : 43|2@0+ (1,0) [0|3] "SED"  GWM
 SG_ OnbChrgGoTPrcond_D_Rq : 34|2@0+ (1,0) [0|3] "SED"  GWM
 SG_ OnbChrgGoTOn_D_Rq : 25|2@0+ (1,0) [0|3] "SED"  GWM
 SG_ OnbChrgGoTMnte_D_Rq : 47|4@0+ (1,0) [0|15] "minute"  GWM
 SG_ OnbChrgGoTHr_T_Rq : 39|5@0+ (1,0) [0|29] "hour"  GWM
 SG_ OnbChrgGoTExtHtr_D_Rq : 27|2@0+ (1,0) [0|3] "SED"  GWM
 SG_ OnbChrgGoTElement_D_Rq : 31|4@0+ (1,0) [0|15] "unitless"  GWM
 SG_ OnbChrgGoTDelete_B_Rq : 17|1@0+ (1,0) [0|1] "SED"  GWM
 SG_ OnbChrgClearAll_B_Rq : 18|1@0+ (1,0) [0|1] "SED"  GWM
 SG_ DcacGfciTestBttn_B_Stat : 9|1@0+ (1,0) [0|1] "SED"  GWM
 SG_ OnbChrgGoTUpdate_B_Rq : 16|1@0+ (1,0) [0|1] "SED"  GWM
 SG_ TrlrAlarmButtn_B_Stat : 50|1@0+ (1,0) [0|1] "SED"  TRM_ITRM,GWM
 SG_ DcacPwButtn_B_Stat : 10|1@0+ (1,0) [0|1] "SED"  GWM
 SG_ TrlrBrkGain_No_Rq : 55|5@0+ (0.5,0) [0|15.5] "unitless"  TRM_ITRM,GWM
 SG_ TrlrHitch_D_RqMnu : 23|4@0+ (1,0) [0|15] "SED"  GWM

BO_ 1184 APIM_TCU_Word_Rx_HS3: 8 GWM
 SG_ APIM_TCU_Word_Rx : 7|64@0+ (1,0) [0|1.84467440737096E+019] "unitless"  APIM,APIM_CISM

BO_ 801 DISP_Chime_Req: 8 ACM
 SG_ CDWarnChime_St : 3|1@0+ (1,0) [0|1] "SED"  GWM,IPC
 SG_ DrvDsplyPalette_D_Stat : 2|3@0+ (1,0) [0|7] "SED"  IPC
 SG_ SoftWarning : 6|1@0+ (1,0) [0|1] "SED"  GWM,IPC
 SG_ HardWarning : 5|1@0+ (1,0) [0|1] "SED"  GWM,IPC
 SG_ InfoWarning : 7|1@0+ (1,0) [0|1] "SED"  GWM,IPC

BO_ 878 Rear_Climate_Data2: 8 RACM_RCIM
 SG_ ClimtSyncRear2_B_Stat : 58|1@0+ (1,0) [0|1] "SED"  GWM
 SG_ ClimtStHeatRr2_B_Stat : 54|1@0+ (1,0) [0|1] "SED"  GWM
 SG_ ClimtStHeatRl2_B_Stat : 55|1@0+ (1,0) [0|1] "SED"  GWM
 SG_ ClimtStCoolRr2_B_Stat : 52|1@0+ (1,0) [0|1] "SED"  GWM
 SG_ ClimtStCoolRl2_B_Stat : 53|1@0+ (1,0) [0|1] "SED"  GWM
 SG_ ClimtSeatRr2_D_Rq : 39|8@0+ (1,0) [0|64] "SED"  GWM
 SG_ ClimtSeatRl2_D_Rq : 47|8@0+ (1,0) [0|64] "SED"  GWM
 SG_ ClimtRrTe3rd2_D_Stat : 51|2@0+ (1,0) [0|3] "SED"  GWM
 SG_ ClimtRrPw3rd2_B_Stat : 59|1@0+ (1,0) [0|1] "SED"  GWM
 SG_ ClimtRrPnl3rd2_B_Stat : 62|1@0+ (1,0) [0|1] "SED"  GWM
 SG_ ClimtRrPf3rd2_B_Stat : 63|1@0+ (1,0) [0|1] "SED"  GWM
 SG_ ClimtRrFlr3rd2_B_Stat : 61|1@0+ (1,0) [0|1] "SED"  GWM
 SG_ ClimtRrBlwr3rd2_D_Stat : 49|2@0+ (1,0) [0|3] "SED"  GWM
 SG_ ClimtRrAuto3rd2_B_Stat : 60|1@0+ (1,0) [0|1] "SED"  GWM
 SG_ ClimtRearView2_D_Stat : 57|2@0+ (1,0) [0|3] "SED"  GWM
 SG_ ClimtRearTe2_D_Stat : 11|2@0+ (1,0) [0|3] "SED"  GWM
 SG_ ClimtRearTe2_An_Actl : 7|9@0+ (1,0) [0|510] "degrees"  GWM
 SG_ ClimtRearPw2_B_Stat : 29|1@0+ (1,0) [0|1] "SED"  GWM
 SG_ ClimtRearPnlFlr2_B_Stat : 13|1@0+ (1,0) [0|1] "SED"  GWM
 SG_ ClimtRearPnl2_B_Stat : 14|1@0+ (1,0) [0|1] "SED"  GWM
 SG_ ClimtRearFlr2_B_Stat : 12|1@0+ (1,0) [0|1] "SED"  GWM
 SG_ ClimtRearBlwr2_D_Stat : 9|2@0+ (1,0) [0|3] "SED"  GWM
 SG_ ClimtRearBlwr2_An_Actl : 23|9@0+ (1,0) [0|510] "degrees"  GWM
 SG_ ClimtRearAuto2_B_Stat : 30|1@0+ (1,0) [0|1] "SED"  GWM

BO_ 1192 APIM_TCU_Word_Tx: 8 APIM
 SG_ APIM_TCU_Word_Tx : 7|64@0+ (1,0) [0|1.84467440737096E+019] "unitless"  GWM

BO_ 259 MFD_Request_Signals2: 8 APIM
 SG_ SDARS_CurrCATlstSize_Rq : 15|8@0+ (1,0) [0|255] "unitless"  ACM
 SG_ SDARS_CurrCATlistInd_Rq : 7|8@0+ (1,0) [0|255] "unitless"  ACM
 SG_ SDARS_ChipControl_Rq : 21|3@0+ (1,0) [0|7] "SED"  ACM
 SG_ SDARS_AlertStatus_Rq : 23|2@0+ (1,0) [0|3] "SED"  ACM

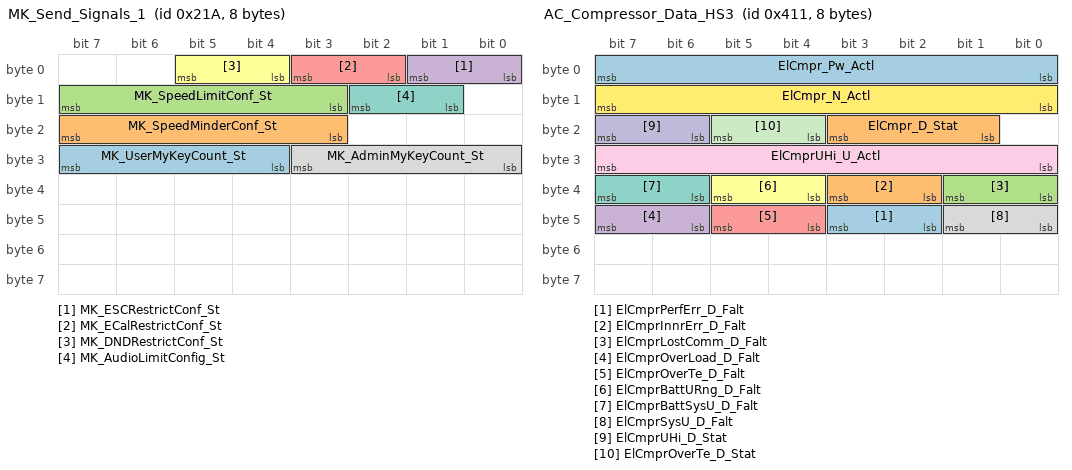
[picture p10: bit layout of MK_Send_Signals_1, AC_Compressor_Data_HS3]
BO_ 538 MK_Send_Signals_1: 8 IPC
 SG_ MK_UserMyKeyCount_St : 31|4@0+ (1,0) [0|13] "SED"  APIM,APIM_CISM,GWM
 SG_ MK_SpeedMinderConf_St : 23|5@0+ (1,0) [0|31] "SED"  APIM,APIM_CISM,GWM
 SG_ MK_SpeedLimitConf_St : 15|5@0+ (1,0) [0|31] "SED"  APIM,APIM_CISM,GWM
 SG_ MK_ESCRestrictConf_St : 1|2@0+ (1,0) [0|3] "SED"  APIM,APIM_CISM,GWM
 SG_ MK_ECalRestrictConf_St : 3|2@0+ (1,0) [0|3] "SED"  APIM,APIM_CISM,GWM
 SG_ MK_DNDRestrictConf_St : 5|2@0+ (1,0) [0|3] "SED"  APIM,APIM_CISM,GWM
 SG_ MK_AudioLimitConfig_St : 10|2@0+ (1,0) [0|3] "SED"  APIM,APIM_CISM,GWM
 SG_ MK_AdminMyKeyCount_St : 27|4@0+ (1,0) [0|13] "SED"  APIM,APIM_CISM,GWM

BO_ 422 MK_Response_Signals_1: 8 IPC
 SG_ MK_UserMyKeyCount_Rsp : 4|4@0+ (1,0) [0|15] "SED"  APIM,APIM_CISM,GWM
 SG_ MK_MyKeyDrivenKm_Rsp : 43|20@0+ (1,0) [0|1048575] "km"  APIM,APIM_CISM,GWM
 SG_ MK_CreateMyKey_Rsp : 7|3@0+ (1,0) [0|7] "SED"  APIM,APIM_CISM,GWM
 SG_ MK_AdminMyKeyCount_Rsp : 15|4@0+ (1,0) [0|15] "SED"  APIM,APIM_CISM,GWM

BO_ 1041 AC_Compressor_Data_HS3: 8 GWM
 SG_ ElCmprPerfErr_D_Falt : 43|2@0+ (1,0) [0|3] "SED" Vector__XXX
 SG_ ElCmprInnrErr_D_Falt : 35|2@0+ (1,0) [0|3] "SED" Vector__XXX
 SG_ ElCmprLostComm_D_Falt : 33|2@0+ (1,0) [0|3] "SED" Vector__XXX
 SG_ ElCmprOverLoad_D_Falt : 47|2@0+ (1,0) [0|3] "SED" Vector__XXX
 SG_ ElCmprOverTe_D_Falt : 45|2@0+ (1,0) [0|3] "SED" Vector__XXX
 SG_ ElCmprBattURng_D_Falt : 37|2@0+ (1,0) [0|3] "SED" Vector__XXX
 SG_ ElCmprBattSysU_D_Falt : 39|2@0+ (1,0) [0|3] "SED" Vector__XXX
 SG_ ElCmprSysU_D_Falt : 41|2@0+ (1,0) [0|3] "SED" Vector__XXX
 SG_ ElCmprUHi_U_Actl : 31|8@0+ (2,0) [0|510] "volt" Vector__XXX
 SG_ ElCmprUHi_D_Stat : 23|2@0+ (1,0) [0|3] "SED" Vector__XXX
 SG_ ElCmprOverTe_D_Stat : 21|2@0+ (1,0) [0|3] "SED" Vector__XXX
 SG_ ElCmpr_N_Actl : 15|8@0+ (50,0) [0|12700] "RPM"  WCM
 SG_ ElCmpr_Pw_Actl : 7|8@0+ (40,0) [0|10160] "watts" Vector__XXX
 SG_ ElCmpr_D_Stat : 19|3@0+ (1,0) [0|7] "SED" Vector__XXX

BO_ 890 Active_Noise: 8 ACM
 SG_ ActvNseMute_D_Rq : 4|2@0+ (1,0) [0|3] "SED"  DSP
 SG_ ActvNseAudio_D_Stat : 7|2@0+ (1,0) [0|3] "SED"  DSP
 SG_ ActvNse_B_Actv : 5|1@0+ (1,0) [0|1] "SED"  DSP

BO_ 2008 TesterPhysicalResAPIM: 8 APIM
 SG_ TesterPhysicalResAPIM : 7|64@0+ (1,0) [0|1.84467E+019] "unitless"  TSTR

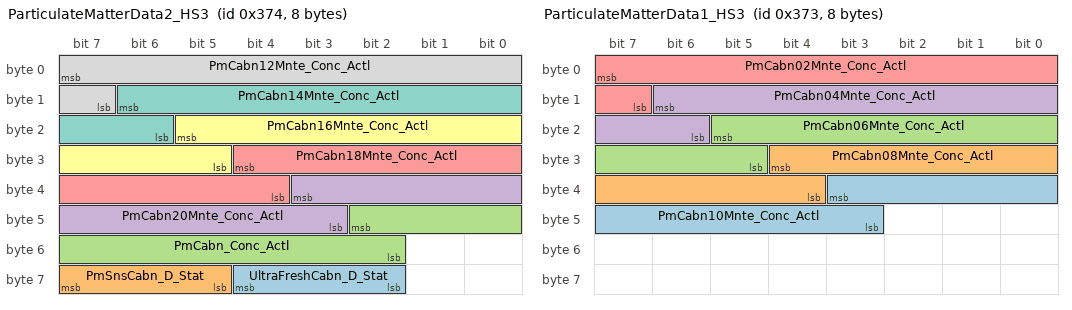
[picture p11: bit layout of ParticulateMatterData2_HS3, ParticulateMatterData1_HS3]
BO_ 884 ParticulateMatterData2_HS3: 8 GWM
 SG_ UltraFreshCabn_D_Stat : 60|3@0+ (1,0) [0|7] "SED"  APIM_CISM
 SG_ PmSnsCabn_D_Stat : 63|3@0+ (1,0) [0|7] "SED"  APIM,APIM_CISM
 SG_ PmCabn_Conc_Actl : 42|9@0+ (1,0) [0|509] "parts/million"  APIM,APIM_CISM
 SG_ PmCabn20Mnte_Conc_Actl : 35|9@0+ (1,0) [0|509] "parts/million"  APIM,APIM_CISM,RACM_RCIM
 SG_ PmCabn18Mnte_Conc_Actl : 28|9@0+ (1,0) [0|509] "parts/million"  APIM,APIM_CISM,RACM_RCIM
 SG_ PmCabn16Mnte_Conc_Actl : 21|9@0+ (1,0) [0|509] "parts/million"  APIM,APIM_CISM,RACM_RCIM
 SG_ PmCabn14Mnte_Conc_Actl : 14|9@0+ (1,0) [0|509] "parts/million"  APIM,APIM_CISM,RACM_RCIM
 SG_ PmCabn12Mnte_Conc_Actl : 7|9@0+ (1,0) [0|509] "parts/million"  APIM,APIM_CISM,RACM_RCIM

BO_ 883 ParticulateMatterData1_HS3: 8 GWM
 SG_ PmCabn10Mnte_Conc_Actl : 35|9@0+ (1,0) [0|509] "parts/million"  APIM,APIM_CISM,RACM_RCIM
 SG_ PmCabn08Mnte_Conc_Actl : 28|9@0+ (1,0) [0|509] "parts/million"  APIM,APIM_CISM,RACM_RCIM
 SG_ PmCabn06Mnte_Conc_Actl : 21|9@0+ (1,0) [0|509] "parts/million"  APIM,APIM_CISM,RACM_RCIM
 SG_ PmCabn04Mnte_Conc_Actl : 14|9@0+ (1,0) [0|509] "parts/million"  APIM,APIM_CISM,RACM_RCIM
 SG_ PmCabn02Mnte_Conc_Actl : 7|9@0+ (1,0) [0|509] "parts/million"  APIM,APIM_CISM,RACM_RCIM

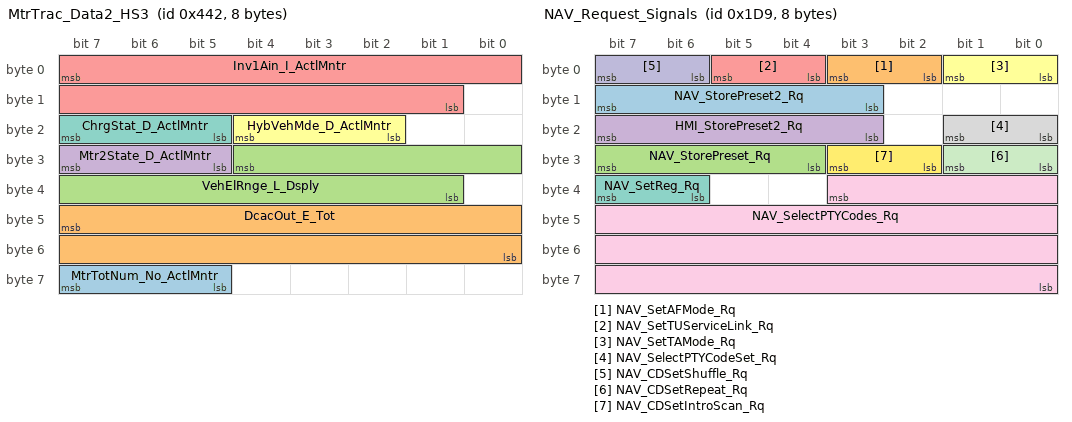
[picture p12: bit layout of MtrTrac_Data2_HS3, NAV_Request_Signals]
BO_ 1090 MtrTrac_Data2_HS3: 8 GWM
 SG_ MtrTotNum_No_ActlMntr : 63|3@0+ (1,0) [0|7] "unitless" Vector__XXX
 SG_ DcacOut_E_Tot : 47|16@0+ (20,0) [0|1310700] "watt*hour"  APIM,APIM_CISM
 SG_ VehElRnge_L_Dsply : 28|12@0+ (0.1,0) [0|409.3] "kilometer"  APIM,APIM_CISM,HUD_ADV,IPC
 SG_ Mtr2State_D_ActlMntr : 31|3@0+ (1,0) [0|7] "SED" Vector__XXX
 SG_ Inv1Ain_I_ActlMntr : 7|15@0+ (0.1,-1000) [-1000|2276.5] "ampere" Vector__XXX
 SG_ HybVehMde_D_ActlMntr : 20|3@0+ (1,0) [0|7] "SED" Vector__XXX
 SG_ ChrgStat_D_ActlMntr : 23|3@0+ (1,0) [0|7] "SED" Vector__XXX

BO_ 592 RFA_BLEM_APIM_Tx_HS3: 8 GWM
 SG_ RFA_BLEM_APIM_Tx : 7|64@0+ (1,0) [0|1.84467440737096E+019] "unitless"  APIM,APIM_CISM

BO_ 715 SSPClnt_SSPSrv_WORD_Rx: 8 APIM
 SG_ RDISP_SSP_WORD_Rx : 7|64@0+ (1,0) [0|1.84467440737096E+019] "unitless"  ACM

BO_ 473 NAV_Request_Signals: 8 APIM
 SG_ NAV_StorePreset2_Rq : 15|5@0+ (1,0) [0|31] "SED"  ACM
 SG_ NAV_SetAFMode_Rq : 3|2@0+ (1,0) [0|3] "SED"  ACM,GENERIC
 SG_ NAV_StorePreset_Rq : 31|4@0+ (1,0) [0|15] "SED"  ACM,GENERIC
 SG_ HMI_StorePreset2_Rq : 23|5@0+ (1,0) [0|31] "SED"  ACM
 SG_ NAV_SetTUServiceLink_Rq : 5|2@0+ (1,0) [0|3] "SED"  ACM
 SG_ NAV_SetTAMode_Rq : 1|2@0+ (1,0) [0|3] "SED"  ACM
 SG_ NAV_SetReg_Rq : 39|2@0+ (1,0) [0|3] "SED"  ACM
 SG_ NAV_SelectPTYCodeSet_Rq : 17|2@0+ (1,0) [0|3] "SED"  ACM
 SG_ NAV_SelectPTYCodes_Rq : 35|28@0+ (1,0) [0|268435455] "unitless"  ACM
 SG_ NAV_CDSetShuffle_Rq : 7|2@0+ (1,0) [0|3] "SED"  ACM
 SG_ NAV_CDSetRepeat_Rq : 25|2@0+ (1,0) [0|3] "SED"  ACM
 SG_ NAV_CDSetIntroScan_Rq : 27|2@0+ (1,0) [0|3] "SED"  ACM

BO_ 2000 TesterPhysicalReqAPIM: 8 TSTR
 SG_ TesterPhysicalReqAPIM : 7|64@0+ (1,0) [0|1.84467E+019] "unitless"  APIM,APIM_CISM

BO_ 90 Gear_Shift_by_Wire_HS3: 8 GWM
 SG_ TrnGsmNtmState_D_Actl : 55|2@0+ (1,0) [0|3] "SED" Vector__XXX
 SG_ DrQltyDrv_D_StatGsm : 42|3@0+ (1,0) [0|7] "SED" Vector__XXX
 SG_ TrnBtsiOvrrd_B_Stat : 43|1@0+ (1,0) [0|1] "SED" Vector__XXX
 SG_ GsmGearMsgTxt_D_Rq : 63|2@0+ (1,0) [0|3] "SED"  IPC
 SG_ TrnRng_D_RqGsm : 51|4@0+ (1,0) [0|15] "SED" Vector__XXX
 SG_ PrkBrkActv_D_RqGsmGear : 53|2@0+ (1,0) [0|3] "SED" Vector__XXX
 SG_ TrnValidGearRq_D_Stat : 25|2@0+ (1,0) [0|3] "SED" Vector__XXX
 SG_ TrnGearRqCnt_B_Actl : 26|1@0+ (1,0) [0|1] "unitless" Vector__XXX
 SG_ TrnGearButtn_U_Actl : 23|8@0+ (0.05,0) [0|12.7] "VOLT" Vector__XXX
 SG_ TrnGearButtn_B_ActlR2 : 8|1@0+ (1,0) [0|1] "SED" Vector__XXX
 SG_ TrnGearButtn_B_ActlR1 : 9|1@0+ (1,0) [0|1] "SED" Vector__XXX
 SG_ TrnGearButtn_B_ActlR0 : 10|1@0+ (1,0) [0|1] "SED" Vector__XXX
 SG_ TrnGearButtn_B_ActlP2 : 11|1@0+ (1,0) [0|1] "SED" Vector__XXX
 SG_ TrnGearButtn_B_ActlP1 : 12|1@0+ (1,0) [0|1] "SED" Vector__XXX
 SG_ TrnGearButtn_B_ActlP0 : 13|1@0+ (1,0) [0|1] "SED" Vector__XXX
 SG_ TrnGearButtn_B_ActlN2 : 14|1@0+ (1,0) [0|1] "SED" Vector__XXX
 SG_ TrnGearButtn_B_ActlN1 : 15|1@0+ (1,0) [0|1] "SED" Vector__XXX
 SG_ TrnGearButtn_B_ActlN0 : 0|1@0+ (1,0) [0|1] "SED" Vector__XXX
 SG_ TrnGearButtn_B_ActlM2 : 1|1@0+ (1,0) [0|1] "SED" Vector__XXX
 SG_ TrnGearButtn_B_ActlM1 : 2|1@0+ (1,0) [0|1] "SED" Vector__XXX
 SG_ TrnGearButtn_B_ActlM0 : 3|1@0+ (1,0) [0|1] "SED" Vector__XXX
 SG_ TrnGearButtn_B_ActlD2 : 4|1@0+ (1,0) [0|1] "SED" Vector__XXX
 SG_ TrnGearButtn_B_ActlD1 : 5|1@0+ (1,0) [0|1] "SED" Vector__XXX
 SG_ TrnGearButtn_B_ActlD0 : 6|1@0+ (1,0) [0|1] "SED" Vector__XXX
 SG_ TrnGear_No_Cs : 39|8@0+ (1,0) [0|255] "unitless" Vector__XXX
 SG_ TrnGear_No_Cnt : 47|4@0+ (1,0) [0|15] "unitless" Vector__XXX
 SG_ TrnGear_D_RqDrv : 31|5@0+ (1,0) [0|31] "SED" Vector__XXX
 SG_ BrkSwtchPos_B_ActlGsm : 7|1@0+ (1,0) [0|1] "SED" Vector__XXX

BO_ 1021 TTPMS_InnerRghtTrlTire_HS3: 8 GWM
 SG_ TrlrTireSensIRR_D_Stat : 63|4@0+ (1,0) [0|15] "SED"  APIM,APIM_CISM,IPC
 SG_ TrlrTireSensIRM_D_Stat : 51|4@0+ (1,0) [0|15] "SED"  APIM,APIM_CISM,IPC
 SG_ TrlrTireSensIRF_D_Stat : 55|4@0+ (1,0) [0|15] "SED"  APIM,APIM_CISM
 SG_ TrlrTireIRR_P_Actl : 39|16@0+ (1,0) [0|65533] "kilopascal"  APIM,APIM_CISM,IPC
 SG_ TrlrTireIRM_P_Actl : 23|16@0+ (1,0) [0|65533] "kilopascal"  APIM,APIM_CISM,IPC
 SG_ TrlrTireIRF_P_Actl : 7|16@0+ (1,0) [0|65533] "kilopascal"  APIM,APIM_CISM,IPC

BO_ 2611166424 PARSEDPhysGWM_ECGtoESPM: 8 GWM
 SG_ PARSEDPhysGWM_ECGtoESPM : 7|29@0+ (1,0) [0|536870911] "unitless"  ESPM

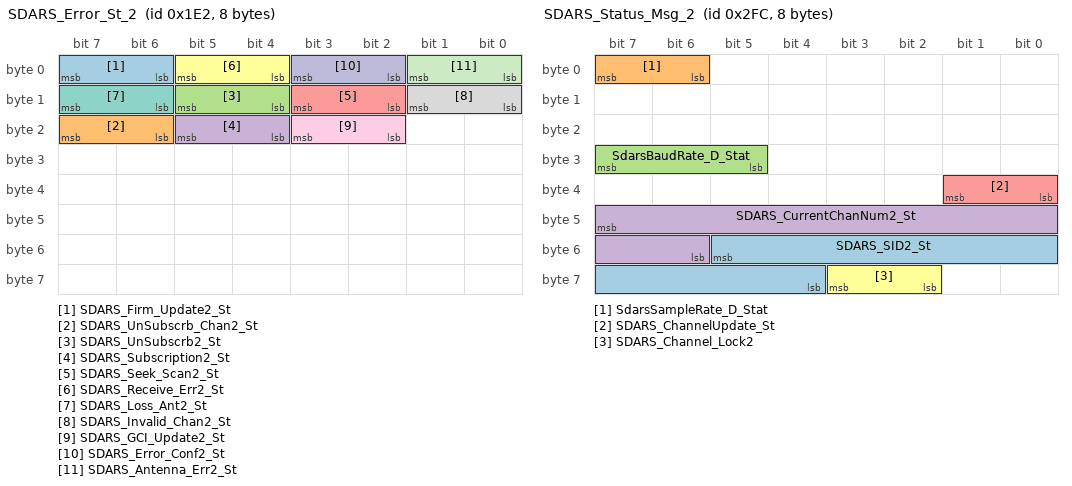
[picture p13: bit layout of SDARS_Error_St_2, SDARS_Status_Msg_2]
BO_ 482 SDARS_Error_St_2: 8 APIM
 SG_ SDARS_Firm_Update2_St : 7|2@0+ (1,0) [0|3] "SED"  RACM_RCIM,IPC
 SG_ SDARS_UnSubscrb_Chan2_St : 23|2@0+ (1,0) [0|3] "SED"  RACM_RCIM,IPC
 SG_ SDARS_UnSubscrb2_St : 13|2@0+ (1,0) [0|3] "SED"  RACM_RCIM,IPC
 SG_ SDARS_Subscription2_St : 21|2@0+ (1,0) [0|3] "SED"  RACM_RCIM,IPC
 SG_ SDARS_Seek_Scan2_St : 11|2@0+ (1,0) [0|3] "SED"  RACM_RCIM,IPC
 SG_ SDARS_Receive_Err2_St : 5|2@0+ (1,0) [0|3] "SED"  RACM_RCIM,IPC
 SG_ SDARS_Loss_Ant2_St : 15|2@0+ (1,0) [0|3] "SED"  RACM_RCIM,IPC
 SG_ SDARS_Invalid_Chan2_St : 9|2@0+ (1,0) [0|3] "SED"  RACM_RCIM,IPC
 SG_ SDARS_GCI_Update2_St : 19|2@0+ (1,0) [0|3] "SED"  RACM_RCIM,IPC
 SG_ SDARS_Error_Conf2_St : 3|2@0+ (1,0) [0|3] "SED"  RACM_RCIM,IPC
 SG_ SDARS_Antenna_Err2_St : 1|2@0+ (1,0) [0|3] "SED"  RACM_RCIM,IPC

BO_ 764 SDARS_Status_Msg_2: 8 APIM
 SG_ SDARS_SID2_St : 53|10@0+ (1,0) [0|1023] "unitless"  ACM
 SG_ SdarsSampleRate_D_Stat : 7|2@0+ (1,0) [0|3] "SED"  ACM
 SG_ SdarsBaudRate_D_Stat : 31|3@0+ (1,0) [0|7] "SED"  ACM
 SG_ SDARS_CurrentChanNum2_St : 47|10@0+ (1,0) [0|1023] "unitless"  ACM,IPC
 SG_ SDARS_ChannelUpdate_St : 33|2@0+ (1,0) [0|3] "SED"  ACM
 SG_ SDARS_Channel_Lock2 : 59|2@0+ (1,0) [0|3] "SED"  IPC,ACM

BO_ 1188 OPTIN_MC_WORD_Rx: 8 IPC
 SG_ OPTIN_MC_WORD_Rx : 7|64@0+ (1,0) [0|1.84467440737096E+019] "unitless"  GWM

BO_ 139 CruiseCtrl_Strg_Data_HS3: 8 GWM
 SG_ AccButtnGpTogglePress2 : 25|1@0+ (1,0) [0|1] "SED" Vector__XXX
 SG_ TjaButtnOnOffPress2 : 26|1@0+ (1,0) [0|1] "SED" Vector__XXX
 SG_ ActvFrontSteMsgTxt_D_Rq : 31|3@0+ (1,0) [0|7] "SED"  IPC
 SG_ ActvFrontSteLck_D_Stat : 17|2@0+ (1,0) [0|3] "SED" Vector__XXX
 SG_ SelDrvMdeAdptSte_D_Stat : 28|2@0+ (1,0) [0|3] "SED" Vector__XXX
 SG_ AslButtnOnOffPress2 : 4|1@0+ (1,0) [0|1] "SED" Vector__XXX
 SG_ AslButtnOnOffCnclPres2 : 5|1@0+ (1,0) [0|1] "SED" Vector__XXX
 SG_ CcButtnOnPress2 : 18|1@0+ (1,0) [0|1] "SED" Vector__XXX
 SG_ CcButtnOnOffPress2 : 19|1@0+ (1,0) [0|1] "SED" Vector__XXX
 SG_ CcButtnOnOffCnclPress2 : 20|1@0+ (1,0) [0|1] "SED" Vector__XXX
 SG_ CcButtnOffPress2 : 21|1@0+ (1,0) [0|1] "SED" Vector__XXX
 SG_ CcAsllButtnResPress2 : 22|1@0+ (1,0) [0|1] "SED" Vector__XXX
 SG_ CcAslButtnSetPress2 : 23|1@0+ (1,0) [0|1] "SED" Vector__XXX
 SG_ CcAslButtnSetIncPress2 : 8|1@0+ (1,0) [0|1] "SED" Vector__XXX
 SG_ CcAslButtnSetDecPress2 : 9|1@0+ (1,0) [0|1] "SED" Vector__XXX
 SG_ CcAslButtnResIncPress2 : 10|1@0+ (1,0) [0|1] "SED" Vector__XXX
 SG_ CcAslButtnResDecPress2 : 11|1@0+ (1,0) [0|1] "SED" Vector__XXX
 SG_ CcAslButtnOnPress2 : 12|1@0+ (1,0) [0|1] "SED" Vector__XXX
 SG_ CcAslButtnOnOffCncl2 : 13|1@0+ (1,0) [0|1] "SED" Vector__XXX
 SG_ CcAslButtnOffCnclPres2 : 14|1@0+ (1,0) [0|1] "SED" Vector__XXX
 SG_ CcAslButtnIndxIncPres2 : 15|1@0+ (1,0) [0|1] "SED" Vector__XXX
 SG_ CcAslButtnIndxDecPres2 : 0|1@0+ (1,0) [0|1] "SED" Vector__XXX
 SG_ CcAslButtnDeny_B_Actl2 : 1|1@0+ (1,0) [0|1] "SED" Vector__XXX
 SG_ CcAslButtnCnclResPres2 : 2|1@0+ (1,0) [0|1] "SED" Vector__XXX
 SG_ CcAslButtnCnclPress2 : 3|1@0+ (1,0) [0|1] "SED" Vector__XXX
 SG_ AccButtnGapIncPress2 : 6|1@0+ (1,0) [0|1] "SED" Vector__XXX
 SG_ AccButtnGapDecPress2 : 7|1@0+ (1,0) [0|1] "SED" Vector__XXX
 SG_ AfsPw_B_Rq : 24|1@0+ (1,0) [0|1] "SED" Vector__XXX

BO_ 837 VeyDynamics_Data_HS3: 8 GWM
 SG_ VehCurb_M_Actl : 43|10@0+ (5,0) [0|5105] "kilogram"  APIM,APIM_CISM
 SG_ VehGvwr_M_Actl : 49|10@0+ (10,0) [0|10210] "kilogram"  APIM,APIM_CISM
 SG_ SuspVLimBRq_No_Cnt : 47|4@0+ (1,0) [0|15] "Unitless" Vector__XXX
 SG_ SuspVLimBRq_No_Cs : 39|8@0+ (1,0) [0|255] "Unitless" Vector__XXX
 SG_ VdmSustnActv_B_Rq : 12|1@0+ (1,0) [0|1] "SED" Vector__XXX
 SG_ Ccd_B_Falt : 24|1@0+ (1,0) [0|1] "SED"  IPC
 SG_ SuspVLim_B_Rq : 18|1@0+ (1,0) [0|1] "SED" Vector__XXX
 SG_ SelDrvMdeSusp_D_Stat : 20|2@0+ (1,0) [0|3] "SED" Vector__XXX
 SG_ AdptDrvMdePt_D_Rq : 23|3@0+ (1,0) [0|7] "SED" Vector__XXX
 SG_ AdptDrvMdeChassis_D_Rq : 10|3@0+ (1,0) [0|7] "SED" Vector__XXX
 SG_ AirSprngRateRr_D_Rq : 27|2@0+ (1,0) [0|3] "SED" Vector__XXX
 SG_ AirSprngRateRl_D_Rq : 29|2@0+ (1,0) [0|3] "SED" Vector__XXX
 SG_ SuspType_B_Stat : 25|1@0+ (1,0) [0|1] "SED" Vector__XXX
 SG_ AirSprngRateFr_D_Rq : 31|2@0+ (1,0) [0|3] "SED" Vector__XXX
 SG_ AirSprngRateFl_D_Rq : 17|2@0+ (1,0) [0|3] "SED" Vector__XXX
 SG_ AirSusp_D_Stat : 1|2@0+ (1,0) [0|3] "SED"  IPC
 SG_ AirSuspMsgTxt_D_Rq : 3|2@0+ (1,0) [0|3] "SED"  IPC
 SG_ SuspDrvMde_D_Stat : 15|3@0+ (1,0) [0|7] "SED"  IPC
 SG_ CcdMsgTxt_D_RqDsply : 7|4@0+ (1,0) [0|15] "SED"  APIM_CISM,IPC,ACM

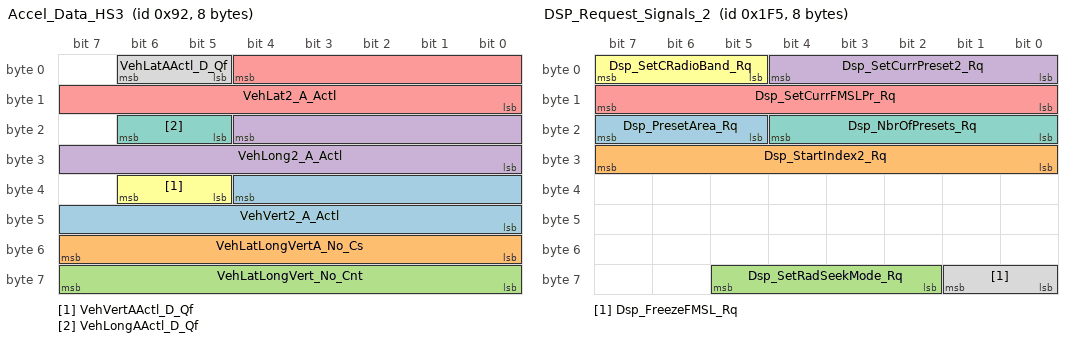
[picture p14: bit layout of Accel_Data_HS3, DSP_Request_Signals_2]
BO_ 146 Accel_Data_HS3: 8 GWM
 SG_ VehVert2_A_Actl : 36|13@0+ (0.01,-40) [-40|41.89] "m/s^2" Vector__XXX
 SG_ VehLatLongVertA_No_Cs : 55|8@0+ (1,0) [0|255] "unitless" Vector__XXX
 SG_ VehLatLongVert_No_Cnt : 63|8@0+ (1,0) [0|255] "unitless" Vector__XXX
 SG_ VehLong2_A_Actl : 20|13@0+ (0.01,-40) [-40|41.89] "m/s^2"  APIM_CISM,ACM
 SG_ VehLat2_A_Actl : 4|13@0+ (0.01,-40) [-40|41.89] "m/s^2" Vector__XXX
 SG_ VehVertAActl_D_Qf : 38|2@0+ (1,0) [0|3] "SED" Vector__XXX
 SG_ VehLongAActl_D_Qf : 22|2@0+ (1,0) [0|3] "SED" Vector__XXX
 SG_ VehLatAActl_D_Qf : 6|2@0+ (1,0) [0|3] "SED" Vector__XXX

BO_ 925 TripInfoData3_HS3: 8 GWM
 SG_ VehElEffTrip_No_Dsply : 47|7@0+ (10,-100) [-100|1150] "wattHr/km"  APIM,APIM_CISM,IPC
 SG_ TripSumDrvE_Pc_Dsply : 25|10@0+ (0.1,0) [0|102.1] "percent"  APIM,APIM_CISM,IPC
 SG_ TripExtFctrE_Pc_Dsply : 19|10@0+ (0.1,0) [0|102.1] "percent"  APIM,APIM_CISM,IPC
 SG_ TripClimE_Pc_Dsply : 13|10@0+ (0.1,0) [0|102.1] "percent"  APIM,APIM_CISM,IPC
 SG_ TripBattULoE_Pc_Dsply : 7|10@0+ (0.1,0) [0|102.1] "percent"  APIM,APIM_CISM,IPC

BO_ 581 TRAFFIC_RDISP_WORD_Tx_HS3: 8 GWM
 SG_ TRAFFIC_RDISP_WORD_Tx : 7|64@0+ (1,0) [0|1.84467440737096E+019] "unitless"  APIM,APIM_CISM

BO_ 501 DSP_Request_Signals_2: 8 APIM
 SG_ Dsp_PresetArea_Rq : 23|3@0+ (1,0) [0|7] "SED"  ACM
 SG_ Dsp_StartIndex2_Rq : 31|8@0+ (1,0) [0|255] "unitless"  ACM
 SG_ Dsp_SetRadSeekMode_Rq : 61|4@0+ (1,0) [0|15] "SED"  ACM
 SG_ Dsp_SetCurrPreset2_Rq : 4|5@0+ (1,0) [0|30] "SED"  ACM
 SG_ Dsp_SetCurrFMSLPr_Rq : 15|8@0+ (1,0) [0|254] "unitless"  ACM
 SG_ Dsp_SetCRadioBand_Rq : 7|3@0+ (1,0) [0|7] "SED"  ACM
 SG_ Dsp_NbrOfPresets_Rq : 20|5@0+ (1,0) [0|30] "unitless"  ACM
 SG_ Dsp_FreezeFMSL_Rq : 57|2@0+ (1,0) [0|3] "SED"  ACM

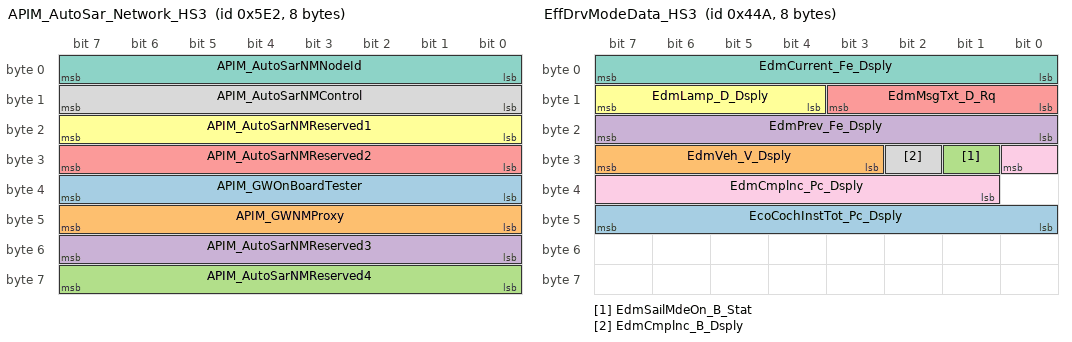
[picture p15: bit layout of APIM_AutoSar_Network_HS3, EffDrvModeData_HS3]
BO_ 1506 APIM_AutoSar_Network_HS3: 8 APIM
 SG_ APIM_GWOnBoardTester : 39|8@0+ (1,0) [0|255] "unitless"  IPC,ACM,HUD_ADV,GENERIC
 SG_ APIM_GWNMProxy : 47|8@0+ (1,0) [0|255] "unitless"  IPC,ACM,HUD_ADV,GENERIC
 SG_ APIM_AutoSarNMReserved4 : 63|8@0+ (1,0) [0|255] "unitless"  IPC,ACM,HUD_ADV,GENERIC
 SG_ APIM_AutoSarNMReserved3 : 55|8@0+ (1,0) [0|255] "unitless"  IPC,ACM,HUD_ADV,GENERIC
 SG_ APIM_AutoSarNMReserved2 : 31|8@0+ (1,0) [0|255] "unitless"  IPC,ACM,HUD_ADV,GENERIC
 SG_ APIM_AutoSarNMReserved1 : 23|8@0+ (1,0) [0|255] "unitless"  IPC,ACM,HUD_ADV,GENERIC
 SG_ APIM_AutoSarNMNodeId : 7|8@0+ (1,0) [0|255] "unitless"  IPC,ACM,HUD_ADV,GENERIC
 SG_ APIM_AutoSarNMControl : 15|8@0+ (1,0) [0|255] "unitless"  IPC,ACM,HUD_ADV,GENERIC

BO_ 651 TCU_Send_Signals_HS3: 8 GWM
 SG_ TelematicsSrvc_D_St : 47|3@0+ (1,0) [0|7] "SED"  APIM,APIM_CISM,ACM
 SG_ EmgcyCallMute_D_Stat : 39|3@0+ (1,0) [0|7] "SED"  APIM,APIM_CISM,DSP,ACM

BO_ 1098 EffDrvModeData_HS3: 8 GWM
 SG_ EcoCochInstTot_Pc_Dsply : 47|8@0+ (0.392157,0) [0|100.000035] "percent"  IPC
 SG_ EdmVeh_V_Dsply : 31|5@0+ (5,0) [0|155] "km/h"  IPC
 SG_ EdmSailMdeOn_B_Stat : 25|1@0+ (1,0) [0|1] "SED"  IPC
 SG_ EdmPrev_Fe_Dsply : 23|8@0+ (0.1,0) [0|25.5] "litre/100km"  IPC
 SG_ EdmMsgTxt_D_Rq : 11|4@0+ (1,0) [0|15] "SED"  IPC
 SG_ EdmLamp_D_Dsply : 15|4@0+ (1,0) [0|15] "SED"  HUD_ADV,IPC
 SG_ EdmCurrent_Fe_Dsply : 7|8@0+ (0.1,0) [0|25.5] "litre/100km"  IPC
 SG_ EdmCmplnc_B_Dsply : 26|1@0+ (1,0) [0|1] "SED"  HUD_ADV,IPC
 SG_ EdmCmplnc_Pc_Dsply : 24|8@0+ (0.392157,0) [0|100.000035] "percent"  IPC

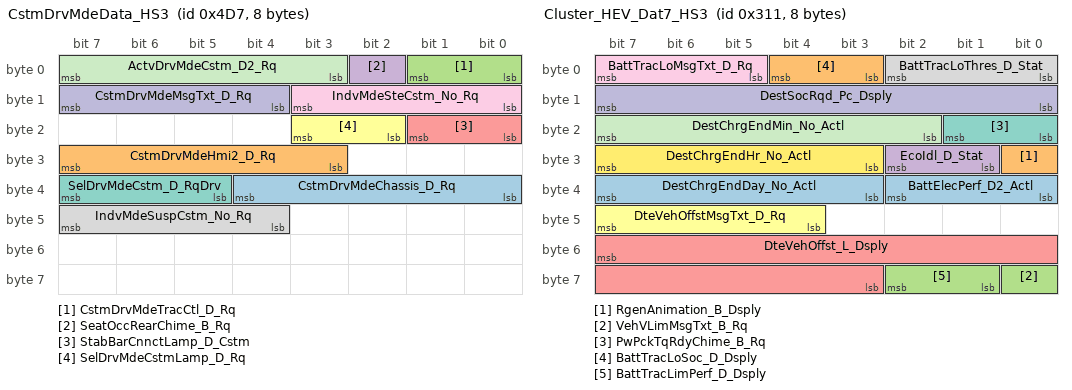
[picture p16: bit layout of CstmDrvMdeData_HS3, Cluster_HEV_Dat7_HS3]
BO_ 1239 CstmDrvMdeData_HS3: 8 GWM
 SG_ CstmDrvMdeChassis_D_Rq : 36|5@0+ (1,0) [0|31] "SED" Vector__XXX
 SG_ CstmDrvMdeHmi2_D_Rq : 31|5@0+ (1,0) [0|31] "SED" Vector__XXX
 SG_ CstmDrvMdeTracCtl_D_Rq : 1|2@0+ (1,0) [0|3] "SED" Vector__XXX
 SG_ SeatOccRearChime_B_Rq : 2|1@0+ (1,0) [0|1] "SED"  IPC
 SG_ StabBarCnnctLamp_D_Cstm : 17|2@0+ (1,0) [0|3] "SED"  IPC
 SG_ SelDrvMdeCstmLamp_D_Rq : 19|2@0+ (1,0) [0|3] "SED"  IPC
 SG_ SelDrvMdeCstm_D_RqDrv : 39|3@0+ (1,0) [0|7] "SED"  IPC
 SG_ IndvMdeSuspCstm_No_Rq : 47|4@0+ (1,0) [0|15] "unitless"  IPC
 SG_ IndvMdeSteCstm_No_Rq : 11|4@0+ (1,0) [0|15] "unitless"  IPC
 SG_ CstmDrvMdeMsgTxt_D_Rq : 15|4@0+ (1,0) [0|15] "SED"  IPC
 SG_ ActvDrvMdeCstm_D2_Rq : 7|5@0+ (1,0) [0|31] "SED"  IPC

BO_ 785 Cluster_HEV_Dat7_HS3: 8 GWM
 SG_ BattElecPerf_D2_Actl : 34|3@0+ (1,0) [0|7] "SED"  IPC
 SG_ RgenAnimation_B_Dsply : 24|1@0+ (1,0) [0|1] "SED"  IPC
 SG_ VehVLimMsgTxt_B_Rq : 56|1@0+ (1,0) [0|1] "SED"  IPC
 SG_ EcoIdl_D_Stat : 26|2@0+ (1,0) [0|3] "SED"  APIM,APIM_CISM
 SG_ DteVehOffst_L_Dsply : 55|13@0+ (0.1,-400) [-400|418.9] "kilometer"  APIM,APIM_CISM,IPC
 SG_ DteVehOffstMsgTxt_D_Rq : 47|4@0+ (1,0) [0|15] "SED"  APIM,APIM_CISM,IPC
 SG_ PwPckTqRdyChime_B_Rq : 17|2@0+ (1,0) [0|3] "SED"  APIM_CISM,IPC
 SG_ BattTracLoThres_D_Stat : 2|3@0+ (1,0) [0|7] "SED"  APIM,APIM_CISM,IPC
 SG_ BattTracLoMsgTxt_D_Rq : 7|3@0+ (1,0) [0|7] "SED"  APIM_CISM,IPC
 SG_ DestSocRqd_Pc_Dsply : 15|8@0+ (0.5,0) [0|127.5] "percent"  APIM,APIM_CISM,IPC
 SG_ DestChrgEndMin_No_Actl : 23|6@0+ (1,0) [0|63] "minute"  APIM,APIM_CISM,IPC
 SG_ DestChrgEndHr_No_Actl : 31|5@0+ (1,0) [0|31] "Hours"  APIM,APIM_CISM,IPC
 SG_ DestChrgEndDay_No_Actl : 39|5@0+ (1,0) [1|31] "day"  APIM,APIM_CISM,IPC
 SG_ BattTracLoSoc_D_Dsply : 4|2@0+ (1,0) [0|3] "SED"  APIM,APIM_CISM,IPC
 SG_ BattTracLimPerf_D_Dsply : 58|2@0+ (1,0) [0|3] "SED"  IPC

BO_ 1210 SDARS_VR_WORD_Tx: 8 ACM
 SG_ SDARS_VR_WORD_Tx : 7|64@0+ (1,0) [0|1.84467440737096E+019] "unitless"  APIM

BO_ 1202 SDARS_VR_WORD_Rx: 8 APIM
 SG_ SDARS_VR_WORD_Rx : 7|64@0+ (1,0) [0|1.84467440737096E+019] "unitless"  ACM

BO_ 415 LBClient3_Request_Signals: 8 RACM_RCIM
 SG_ LBC3_StartItemInd : 55|16@0+ (1,0) [0|65535] "unitless"  APIM,APIM_CISM,ACM
 SG_ LBC3_SetListServ : 47|8@0+ (1,0) [0|255] "unitless"  APIM,APIM_CISM,ACM
 SG_ LBC3_Opcode : 39|2@0+ (1,0) [0|3] "SED"  APIM,APIM_CISM,ACM
 SG_ LBC3_NbrOfItems : 37|6@0+ (1,0) [0|63] "unitless"  APIM,APIM_CISM,ACM
 SG_ LBC3_ItemIndex : 23|16@0+ (1,0) [0|65535] "unitless"  APIM,APIM_CISM,ACM
 SG_ LBC3_ActiveListID : 7|16@0+ (1,0) [0|65535] "unitless"  APIM,APIM_CISM,ACM

BO_ 695 CONMP_MC_WORD_Tx: 8 APIM
 SG_ CONMP_MC_WORD_Tx : 7|64@0+ (1,0) [0|1.84467440737096E+019] "unitless"  IPC

BO_ 703 CONMP_MC_WORD_Rx: 8 IPC
 SG_ CONMP_MC_WORD_Rx : 7|64@0+ (1,0) [0|1.84467440737096E+019] "unitless"  APIM,APIM_CISM

BO_ 1829 TesterPhysicalReqWCM: 8 TSTR
 SG_ TesterPhysicalReqWCM : 7|64@0+ (1,0) [0|1.84467E+019] "unitless"  WCM

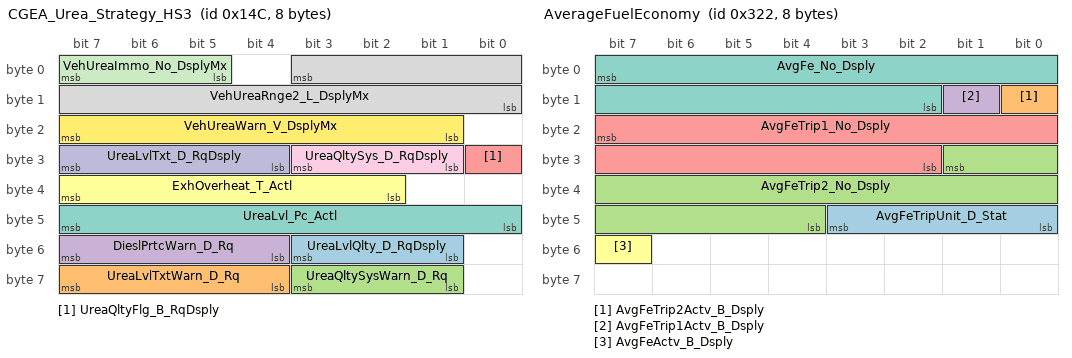
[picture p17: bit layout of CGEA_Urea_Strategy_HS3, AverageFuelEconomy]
BO_ 332 CGEA_Urea_Strategy_HS3: 8 GWM
 SG_ UreaLvlQlty_D_RqDsply : 51|3@0+ (1,0) [0|7] "SED"  APIM_CISM,IPC
 SG_ UreaLvlTxtWarn_D_Rq : 63|4@0+ (1,0) [0|15] "SED"  APIM_CISM,IPC
 SG_ UreaQltySysWarn_D_Rq : 59|3@0+ (1,0) [0|7] "SED"  APIM_CISM,IPC
 SG_ DieslPrtcWarn_D_Rq : 55|4@0+ (1,0) [0|15] "SED"  IPC
 SG_ UreaQltyFlg_B_RqDsply : 24|1@0+ (1,0) [0|1] "SED"  APIM_CISM,IPC
 SG_ ExhOverheat_T_Actl : 39|6@0+ (1,0) [0|63] "minute"  IPC
 SG_ UreaLvl_Pc_Actl : 47|8@0+ (0.4,0) [0|102] "percent"  APIM_CISM,IPC
 SG_ VehUreaRnge2_L_DsplyMx : 3|12@0+ (1,0) [0|4095] "kilometer"  APIM_CISM,IPC
 SG_ UreaQltySys_D_RqDsply : 27|3@0+ (1,0) [0|7] "SED"  APIM_CISM,IPC
 SG_ UreaLvlTxt_D_RqDsply : 31|4@0+ (1,0) [0|15] "SED"  APIM_CISM,IPC
 SG_ VehUreaImmo_No_DsplyMx : 7|3@0+ (1,0) [0|7] "Counts"  IPC
 SG_ VehUreaWarn_V_DsplyMx : 23|7@0+ (1,0) [0|127] "km/h"  APIM_CISM,IPC

BO_ 2612224096 PARSEDPushIPCtoGWM_ECG: 8 IPC
 SG_ PARSEDPushIPCtoGWM_ECG : 7|29@0+ (1,0) [0|536870911] "unitless"  GWM

BO_ 2612101336 PARSEDPushFcGWM_ECGtoIPC: 8 GWM
 SG_ PARSEDPushFcGWM_ECGtoIPC : 7|29@0+ (1,0) [0|536870911] "unitless"  IPC

BO_ 636 TCU_Send_Signals_3_HS3: 8 GWM
 SG_ WifiHtsptFqBand_D_Stat : 60|2@0+ (1,0) [0|3] "SED"  APIM,APIM_CISM,ACM
 SG_ WifiHtspt_D_Falt : 51|4@0+ (1,0) [0|15] "SED"  APIM,APIM_CISM,ACM
 SG_ WifiNoDevcCnnct_No_Actl : 47|8@0+ (1,0) [0|255] "unitless"  APIM,APIM_CISM
 SG_ WifiHtsptCnnct_D_Stat : 26|2@0+ (1,0) [0|3] "SED"  APIM,APIM_CISM
 SG_ Telematics_D_Falt : 39|3@0+ (1,0) [0|7] "SED"  APIM,APIM_CISM
 SG_ WifiEnbl_D_Stat : 4|2@0+ (1,0) [0|3] "SED"  APIM,APIM_CISM
 SG_ WifiHtsptVisbl_D_Stat : 13|2@0+ (1,0) [0|3] "SED"  APIM,APIM_CISM
 SG_ WifiHtsptScrty_D_Stat : 15|2@0+ (1,0) [0|3] "SED"  APIM,APIM_CISM
 SG_ WifiHtsptEnbl_D_Stat : 2|2@0+ (1,0) [0|3] "SED"  APIM,APIM_CISM
 SG_ WifiDevcListNew_B_Stat : 5|1@0+ (1,0) [0|1] "SED"  APIM,APIM_CISM
 SG_ WifiDataUsage_Pc_Actl : 20|4@0+ (5,50) [50|125] "percent"  APIM,APIM_CISM
 SG_ WifiDataUsage_D_Stat : 7|2@0+ (1,0) [0|3] "SED"  APIM,APIM_CISM
 SG_ ModemSigStren_D_Stat : 11|3@0+ (1,0) [0|7] "SED"  APIM,APIM_CISM,ACM
 SG_ ModemTechnology_D2_Stat : 31|3@0+ (1,0) [0|7] "SED"  APIM,APIM_CISM,HUD_ADV
 SG_ WifiHtsptCrdntl_B_Stat : 0|1@0+ (1,0) [0|1] "SED"  APIM,APIM_CISM
 SG_ WifiHtsptFq_D_Avail : 63|3@0+ (1,0) [0|7] "SED"  APIM,APIM_CISM,ACM
 SG_ WifiDataUsageOn_D_Stat : 28|2@0+ (1,0) [0|3] "SED"  APIM,APIM_CISM

BO_ 805 InstFuelEconomy_2: 8 IPC
 SG_ FuelRange_L2_Dsply : 31|15@0+ (0.1,0) [0|3276.7] "kilometer"  APIM,GWM,APIM_CISM
 SG_ InstFeTripUnit_D_Stat : 23|4@0+ (1,0) [0|15] "SED"  APIM,APIM_CISM
 SG_ InstFe_No_Dsply : 7|14@0+ (0.1,0) [0|1638.3] "unitless"  APIM,APIM_CISM

BO_ 804 InstFuelEconomy_1: 8 IPC
 SG_ InstFeMax_No_Dsply : 7|8@0+ (1,0) [0|255] "unitless"  APIM,APIM_CISM
 SG_ ConsInstActv_B_Dsply : 51|1@0+ (1,0) [0|1] "SED"  APIM,APIM_CISM
 SG_ ConsInst_No_Dsply : 15|10@0+ (0.1,0) [0|102.3] "percent"  APIM,APIM_CISM
 SG_ ConsInstUnit_D_Stat : 21|2@0+ (1,0) [0|3] "SED"  APIM,APIM_CISM

BO_ 803 DistantTripDisplay: 8 IPC
 SG_ DistTripUnit_D_Stat : 37|2@0+ (1,0) [0|3] "SED"  APIM,APIM_CISM
 SG_ DistTrip2_No_Dsply : 22|17@0+ (0.1,0) [0|13107.1] "unitless"  APIM,APIM_CISM
 SG_ DistTrip1_No_Dsply : 7|17@0+ (0.1,0) [0|13107.1] "unitless"  APIM,APIM_CISM

BO_ 802 AverageFuelEconomy: 8 IPC
 SG_ AvgFeTripUnit_D_Stat : 43|4@0+ (1,0) [0|15] "SED"  APIM,APIM_CISM
 SG_ AvgFeTrip2Actv_B_Dsply : 8|1@0+ (1,0) [0|1] "SED"  APIM,APIM_CISM
 SG_ AvgFeTrip2_No_Dsply : 25|14@0+ (0.1,0) [0|1638.3] "unitless"  APIM,APIM_CISM
 SG_ AvgFeTrip1Actv_B_Dsply : 9|1@0+ (1,0) [0|1] "SED"  APIM,APIM_CISM
 SG_ AvgFeTrip1_No_Dsply : 23|14@0+ (0.1,0) [0|1638.3] "unitless"  APIM,APIM_CISM
 SG_ AvgFeActv_B_Dsply : 55|1@0+ (1,0) [0|1] "SED"  APIM,APIM_CISM
 SG_ AvgFe_No_Dsply : 7|14@0+ (0.1,0) [0|1638.3] "unitless"  APIM,APIM_CISM

BO_ 812 TimerDisplay_Data: 8 IPC
 SG_ TimerTrip2_T_Dsply : 29|26@0+ (1,0) [0|67108863] "second"  APIM,APIM_CISM
 SG_ TimerTrip1_T_Dsply : 7|26@0+ (1,0) [0|67108863] "second"  APIM,APIM_CISM

BO_ 885 ECG_Data3_HS3: 8 GWM
 SG_ VehStrtInhbt_T_Dsply : 39|16@0+ (1,0) [0|65535] "second"  IPC
 SG_ VehStrtInhbt_D_Dsply : 27|4@0+ (1,0) [0|15] "SED"  IPC
 SG_ OtaActv_D_Stat : 31|4@0+ (1,0) [0|15] "SED"  IPC

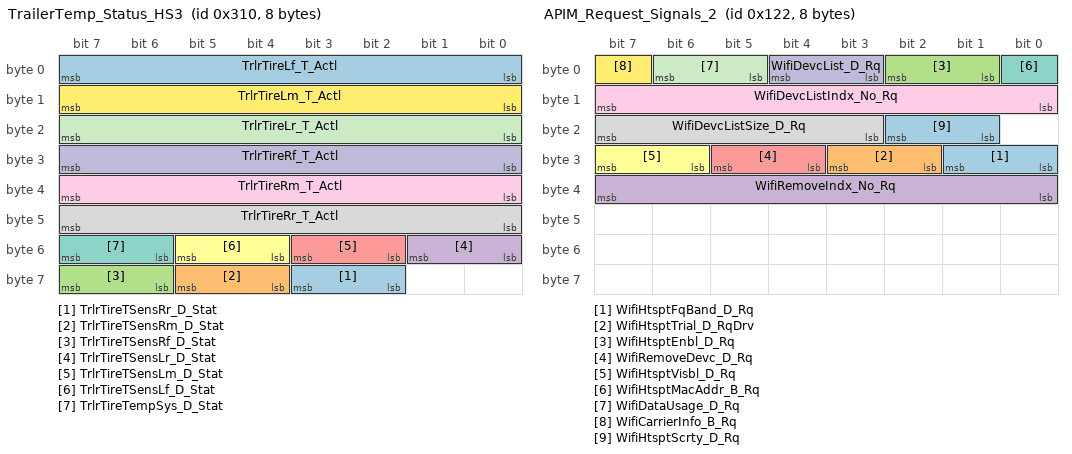
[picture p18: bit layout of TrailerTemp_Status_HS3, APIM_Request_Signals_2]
BO_ 784 TrailerTemp_Status_HS3: 8 GWM
 SG_ TrlrTireTSensRr_D_Stat : 59|2@0+ (1,0) [0|3] "SED"  IPC
 SG_ TrlrTireTSensRm_D_Stat : 61|2@0+ (1,0) [0|3] "SED"  IPC
 SG_ TrlrTireTSensRf_D_Stat : 63|2@0+ (1,0) [0|3] "SED"  IPC
 SG_ TrlrTireTSensLr_D_Stat : 49|2@0+ (1,0) [0|3] "SED"  IPC
 SG_ TrlrTireTSensLm_D_Stat : 51|2@0+ (1,0) [0|3] "SED"  IPC
 SG_ TrlrTireTSensLf_D_Stat : 53|2@0+ (1,0) [0|3] "SED"  IPC
 SG_ TrlrTireTempSys_D_Stat : 55|2@0+ (1,0) [0|3] "SED"  IPC
 SG_ TrlrTireRr_T_Actl : 47|8@0+ (1,-60) [-60|193] "degC"  IPC
 SG_ TrlrTireRm_T_Actl : 39|8@0+ (1,-60) [-60|193] "degC"  IPC
 SG_ TrlrTireRf_T_Actl : 31|8@0+ (1,-60) [-60|193] "degC"  IPC
 SG_ TrlrTireLr_T_Actl : 23|8@0+ (1,-60) [-60|193] "degC"  IPC
 SG_ TrlrTireLm_T_Actl : 15|8@0+ (1,-60) [-60|193] "degC"  IPC
 SG_ TrlrTireLf_T_Actl : 7|8@0+ (1,-60) [-60|193] "degC"  IPC

BO_ 1119 LocationServices_Data2: 8 APIM
 SG_ LocationServices_2 : 7|64@0+ (1,0) [0|1.84467440737096E+019] "unitless"  GWM,IPC

BO_ 1118 LocationServices_Data1: 8 APIM
 SG_ LocationServices_1 : 7|64@0+ (1,0) [0|1.84467440737096E+019] "unitless"  IPC,GWM

BO_ 290 APIM_Request_Signals_2: 8 APIM
 SG_ WifiHtsptFqBand_D_Rq : 25|2@0+ (1,0) [0|3] "SED"  GWM
 SG_ WifiHtsptTrial_D_RqDrv : 27|2@0+ (1,0) [0|3] "SED"  GWM
 SG_ WifiHtsptEnbl_D_Rq : 2|2@0+ (1,0) [0|3] "SED"  GWM
 SG_ WifiRemoveIndx_No_Rq : 39|8@0+ (1,0) [0|255] "unitless"  GWM
 SG_ WifiRemoveDevc_D_Rq : 29|2@0+ (1,0) [0|3] "SED"  GWM
 SG_ WifiHtsptVisbl_D_Rq : 31|2@0+ (1,0) [0|3] "SED"  GWM
 SG_ WifiHtsptMacAddr_B_Rq : 0|1@0+ (1,0) [0|1] "SED"  GWM
 SG_ WifiDevcListSize_D_Rq : 23|5@0+ (1,0) [0|31] "unitless"  GWM
 SG_ WifiDevcListIndx_No_Rq : 15|8@0+ (1,0) [0|255] "unitless"  GWM
 SG_ WifiDevcList_D_Rq : 4|2@0+ (1,0) [0|3] "SED"  GWM
 SG_ WifiDataUsage_D_Rq : 6|2@0+ (1,0) [0|3] "SED"  GWM
 SG_ WifiCarrierInfo_B_Rq : 7|1@0+ (1,0) [0|1] "SED"  GWM
 SG_ WifiHtsptScrty_D_Rq : 18|2@0+ (1,0) [0|3] "SED"  GWM

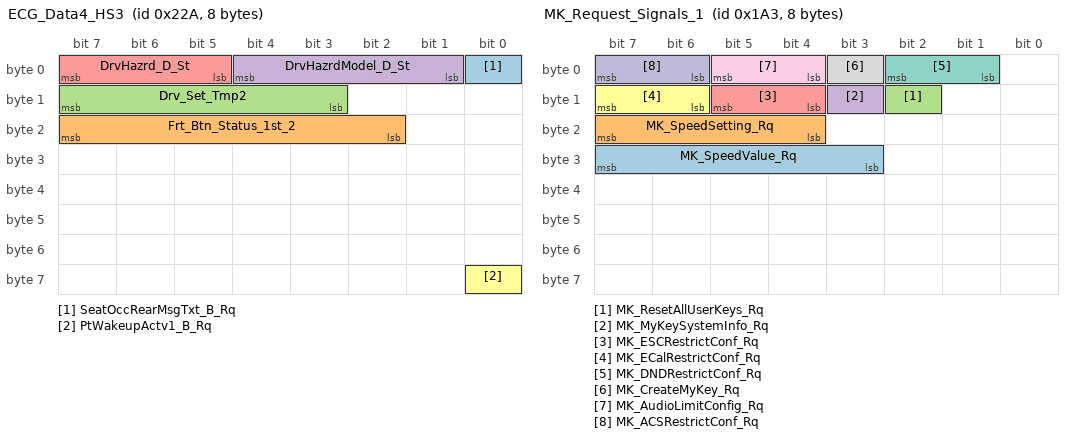
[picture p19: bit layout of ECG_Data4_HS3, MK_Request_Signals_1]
BO_ 554 ECG_Data4_HS3: 8 GWM
 SG_ SeatOccRearMsgTxt_B_Rq : 0|1@0+ (1,0) [0|1] "SED"  APIM,APIM_CISM
 SG_ Frt_Btn_Status_1st_2 : 23|6@0+ (1,0) [0|63] "SED"  RACM_RCIM
 SG_ Drv_Set_Tmp2 : 15|5@0+ (1,0) [0|31] "SED"  RACM_RCIM
 SG_ DrvHazrdModel_D_St : 4|4@0+ (1,0) [0|15] "SED"  APIM,APIM_CISM,IPC
 SG_ DrvHazrd_D_St : 7|3@0+ (1,0) [0|7] "SED"  APIM,APIM_CISM,IPC
 SG_ PtWakeupActv1_B_Rq : 56|1@0+ (1,0) [0|1] "SED"  APIM,APIM_CISM

BO_ 419 MK_Request_Signals_1: 8 APIM
 SG_ MK_SpeedValue_Rq : 31|5@0+ (1,0) [0|31] "SED"  IPC
 SG_ MK_SpeedSetting_Rq : 23|4@0+ (1,0) [0|15] "SED"  IPC
 SG_ MK_ResetAllUserKeys_Rq : 10|1@0+ (1,0) [0|1] "SED"  IPC
 SG_ MK_MyKeySystemInfo_Rq : 11|1@0+ (1,0) [0|1] "SED"  IPC
 SG_ MK_ESCRestrictConf_Rq : 13|2@0+ (1,0) [0|3] "SED"  IPC
 SG_ MK_ECalRestrictConf_Rq : 15|2@0+ (1,0) [0|3] "SED"  IPC
 SG_ MK_DNDRestrictConf_Rq : 2|2@0+ (1,0) [0|3] "SED"  IPC
 SG_ MK_CreateMyKey_Rq : 3|1@0+ (1,0) [0|1] "SED"  IPC
 SG_ MK_AudioLimitConfig_Rq : 5|2@0+ (1,0) [0|3] "SED"  IPC
 SG_ MK_ACSRestrictConf_Rq : 7|2@0+ (1,0) [0|3] "SED"  IPC

BO_ 542 LocationServices_3_HS3: 8 GWM
 SG_ LocationServices_3 : 7|64@0+ (1,0) [0|1.84467440737096E+019] "unitless"  APIM,APIM_CISM,IPC,ACM

BO_TX_BU_ 257 : APIM_CISM,APIM;
BO_TX_BU_ 556 : FCIMB,GWM;
BO_TX_BU_ 600 : APIM_CISM,APIM;
BO_TX_BU_ 414 : APIM,APIM_CISM,ACM;
BO_TX_BU_ 533 : APIM_CISM,APIM;
BO_TX_BU_ 801 : APIM_CISM,APIM,ACM;
BO_TX_BU_ 1192 : APIM_CISM,APIM;
BO_TX_BU_ 259 : APIM_CISM,APIM;
BO_TX_BU_ 890 : APIM_CISM,APIM,ACM;
BO_TX_BU_ 2008 : APIM_CISM,APIM;
BO_TX_BU_ 473 : APIM_CISM,APIM;
BO_TX_BU_ 482 : APIM_CISM,APIM;
BO_TX_BU_ 764 : APIM_CISM,APIM;
BO_TX_BU_ 1506 : APIM_CISM,APIM;
BO_TX_BU_ 1202 : APIM_CISM,APIM;
BO_TX_BU_ 695 : APIM_CISM,APIM;
BO_TX_BU_ 1119 : APIM_CISM,APIM;
BO_TX_BU_ 1118 : APIM_CISM,APIM;
BO_TX_BU_ 290 : APIM_CISM,APIM;
BO_TX_BU_ 419 : APIM_CISM,APIM;
CM_ SG_ 412 LBC2_StartItemInd "Object. ListBrowser.ItemInf.Rq.StartItemInd
0x0000:Inactive
0x0001:1
0xFFFE:65634
0xFFFF:Reserved";
CM_ SG_ 412 LBC2_SetListServ "Object. ListBrowser.ItemInf.Rq.SetListServ
0x00:Inactive
0x01:ServerID_1
0xFF:ALL";
CM_ SG_ 412 LBC2_Opcode "Object. ListBrowser.ItemInf.Rq.Opcode";
CM_ SG_ 412 LBC2_NbrOfItems "Object. ListBrowser.ItemInf.Rq.NbrOfItems
0x00:Inactive
0x01:1Item
0x3F:63Items";
CM_ SG_ 412 LBC2_ItemIndex "Object. ListBrowser.ItemInf.Rq.ItemIndex
0x0000:BrowseActiveListID
0x0001:EntryIndex_1
0xFFFF:ParentOfActiveListID";
CM_ SG_ 412 LBC2_ActiveListID "Object. ListBrowser.ItemInf.Rq.ActiveListID
0x0000:Root
0xFFFF:Reserved";
CM_ SG_ 493 Dsp_StatLiScanCancel_Rq "Object Tuner.StationListScan";
CM_ SG_ 493 Dsp_StationList_Rq "Object Tuner.GetStationList(StationList)
(Parameter1)";
CM_ SG_ 493 Dsp_StartIndex3_Rq "Object TunerGetStationList(StartingIndex)
(Parameter3)";
CM_ SG_ 493 Dsp_RefreshFlag "Object Tuner.GetStationList(StationList)
(Parameter5)";
CM_ SG_ 493 Dsp_PTYCode_Rq "Object Tuner.GetStationList(PTYCode)
(Parramater4)

$0: Invalid
$1: PTY 1 (News)
..
$1F: PTY 31 (Alarm)";
CM_ SG_ 493 Dsp_ListSize_Rq "Object Tuner.GetStationList(ListSize)
(Parameter2)";
CM_ SG_ 493 Dsp_AFJump_Rq "Object Tuner.AFJump.Rq";
CM_ SG_ 511 Dsp_TUStartIndex2_Rq "Object Tuner.GetTUPresetInfo.StartIndex2
Object DAB.GetTUPresetInfo.StartIndex2
Object SDARS.GetTUPresetInfo.StartIndex2

$1-$FF: Preset 1 to 255";
CM_ SG_ 511 Dsp_TUPresetArea_Rq "Object Tuner.GetTUPresetInfo.PresetArea
Object DAB.GetTUPresetInfo.PresetArea
Object SDARS.GetTUPresetInfo.PresetArea";
CM_ SG_ 511 Dsp_TUNbrOfPresets_Rq "Object Tuner.GetTUPresetInfo.NumberOfPresets
Object DAB.GetTUPresetInfo.NumberOfPresets
Object SDARS.GetTUPresetInfo.NumberOfPresets

$1-$1E: Preset 1 to 30";
CM_ SG_ 511 Dsp_SetCurrTUPreset_Rq "Object Tuner.GetTUPresetInfo.SetCurrentTUPreset
Object DAB.GetTUPresetInfo.SetCurrentTUPreset
Object SDARS.GetTUPresetInfo.SetCurrentTUPreset

$1-$1E: Preset 1 to 30";
CM_ SG_ 511 Dsp_SetCurrTUBand_Rq "Object Tuner.SetCurrTUBand
Object DAB.SetCurrTUBand
Object SDARS.SetCurrTUBand
";
CM_ SG_ 257 MFD_SetTagMode "Used by MFD to distribute actual Master Clock data to the Slave";
CM_ SG_ 257 MFD_SetRBDSMode "Used by MFD to distribute actual Master Clock data to the Slave";
CM_ SG_ 257 MFD_SetHDModeRq "Used by MFD to distribute actual Master Clock data to the Slave";
CM_ SG_ 257 MFD_GetTagInfo "Used by MFD to distribute actual Master Clock data to the Slave";
CM_ SG_ 1164 DrLatchCntFr_No_Actl "Rolling counts indicate fresh data (DrLatchCntxx) are updated each time new data is sent from a latch to BCM thru the GW. UBs not required.";
CM_ SG_ 1163 DrLatchCntFl_No_Actl "Rolling counts indicate fresh data (DrLatchCntxx) are updated each time new data is sent from a latch to BCM thru the GW. UBs not required.";
CM_ SG_ 1166 DrLatchCntRr_No_Actl "Rolling counts indicate fresh data (DrLatchCntxx) are updated each time new data is sent from a latch to BCM thru the GW. UBs not required.";
CM_ SG_ 1165 DrLatchCntRl_No_Actl "Rolling counts indicate fresh data (DrLatchCntxx) are updated each time new data is sent from a latch to BCM thru the GW. UBs not required.";
CM_ SG_ 556 EFP_Bezel_Diag_St "Object:BezelDiagnostics.EFP_Bezel_Diag.St";
CM_ SG_ 556 Bezel_Beeps_Supported "Object: Vehicle Settings. Bezel_Beeps_Supported.St";
CM_ SG_ 556 Bezel_Beep_St "Object:VehicleSettings.Bezel_Beeps.St.Status";
CM_ BO_ 130 "drecker 10/23/09 Need SAPP in sync w/Strg Torque for proper PAM interpretation, else fault msg's displayed FP@20ms IPC needs EPAS_Failure for msg to driver.  Not map w/Lane Assist FP@30s FP), save bandwidth if feature not on vehicle ";
CM_ SG_ 130 VehVTrlrAid_B_Rq "VR session start- req. limit blower speed no more than X volts.  CC restriction on time msg. will be honored.Double Event msg1st event to request limit, 2nd event to release limit, No msg. CC Grammar v7.xls";
CM_ SG_ 130 SteMdule_U_Meas "DCR 1745  to update Tx from GWM to EP100ms. SteMdule_I_Est & SteMdule_U_Meas are used by BMS system & filtered. The filter uses standard periodic rate & changing to EP would adversely affect the filter.(jweinfur)";
CM_ SG_ 130 SteMdule_I_Est "DCR 1745  to update Tx from GWM to EP100ms. SteMdule_I_Est & SteMdule_U_Meas are used by BMS system & filtered. The filter uses standard periodic rate & changing to EP would adversely affect the filter.(jweinfur)";
CM_ BO_ 382 "ECM, PCM Gas Only msg";
CM_ BO_ 600 "Tx by HS3 APIM";
CM_ SG_ 600 APIM_RFA_BLEM_Tx "Tx by HS3 APIM";
CM_ SG_ 708 TMCSrvr_TMCClnt_WORD_Tx "MM ISO 15765-2 Message Catalogue RDISP2 - AUDIO";
CM_ SG_ 414 LBS2_ParentID "Object. ListBrowser.ItemInf.Rq.ActiveListID
0x0000:Root
0xFFFF:Reserved";
CM_ SG_ 414 LBS2_ListID "Object. ListBrowser.ItemInf.Rq.ItemIndex
0x0000:BrowseActiveListID
0x0001:EntryIndex_1
0xFFFF:ParentOfActiveListID";
CM_ SG_ 414 LBS2_EntryIndex "Object. ListBrowser.ItemInf.Rq.ActiveListID
0x0000:Root
0xFFFF:Reserved";
CM_ SG_ 619 PaakCtlActvData_No_Actl "Not transmitted on all vehicle variants";
CM_ SG_ 985 LongCtrlEnblDRq_No_Cs "Signal not transmitted on gas and diesel variants.";
CM_ SG_ 985 LongCtrlEnblDRq_No_Cnt "Signal not transmitted on gas and diesel variants.";
CM_ BO_ 1184 "TP message";
CM_ SG_ 1192 APIM_TCU_Word_Tx "Tx by HS3 APIM";
CM_ SG_ 259 SDARS_CurrCATlstSize_Rq "Object:SDARSClient.CurrentCatList.Rq.NumberOfItems 

0x00: Invalid
0x01: List Size 1
0x02: List Size 2
....
0x1E: List Size 30
0xFF: No Entry
";
CM_ SG_ 259 SDARS_CurrCATlistInd_Rq "ObjectTuner.SDARSTuner.CurrentCATList
$0: Inactive
$FF:No_Entry";
CM_ SG_ 259 SDARS_AlertStatus_Rq "Object.SDARSClient.AlertStatus.Rq.Status";
CM_ SG_ 538 MK_UserMyKeyCount_St "Object MyKey.SystemKeyCount_St
[Parameter1]";
CM_ SG_ 538 MK_SpeedMinderConf_St "Object MyKey.SpeedMinderConfig_St";
CM_ SG_ 538 MK_SpeedLimitConf_St "Object MyKey.SpeedLimitConfig_St";
CM_ SG_ 538 MK_ECalRestrictConf_St "Object MyKey.ECallRestrictionConfig_St";
CM_ SG_ 538 MK_DNDRestrictConf_St "Object MyKey.DNDRestrictionConfig_St";
CM_ SG_ 538 MK_AudioLimitConfig_St "Object MyKey.AudioLimitConfig_St";
CM_ SG_ 538 MK_AdminMyKeyCount_St "Object MyKey.SystemKeyCount_St
[Parameter2]";
CM_ SG_ 473 NAV_SetAFMode_Rq "Object Tuner.SetAFMode";
CM_ SG_ 473 NAV_StorePreset_Rq "Object Tuner.StorePreset

NOTE: If used on CANalyzer/CANoe for the older DENSO HighNav System, wrong values will be shown!";
CM_ SG_ 473 NAV_SetTUServiceLink_Rq "Object Tuner.NAV_SetTUServiceLink_Rq";
CM_ SG_ 473 NAV_SetTAMode_Rq "Object Tuner.SetTAMode";
CM_ SG_ 473 NAV_SetReg_Rq "Object Tuner.SetREG";
CM_ SG_ 473 NAV_SelectPTYCodeSet_Rq "Object Tuner.SelectPTYCodes

Set PTY code with the follow bit encoding";
CM_ SG_ 473 NAV_SelectPTYCodes_Rq "Object Tuner.SelectPTYCodes

28 bit bitfield where each PTY code can be set separately:
Bit 0:  0:  PTY Code 2 not selected; 1:  PTY Code 2 selected
...
Bit 27: PTY Code 29 not selected; 1:  PTY Code 29 selected";
CM_ SG_ 473 NAV_CDSetShuffle_Rq "Object Single CD.SetShuffle";
CM_ SG_ 473 NAV_CDSetRepeat_Rq "Object Single CD.SetRepeat";
CM_ SG_ 473 NAV_CDSetIntroScan_Rq "Object Single CD.SetIntroScan";
CM_ SG_ 90 TrnGsmNtmState_D_Actl "Signal not transmitted on vehicles that do not have shift by wire.";
CM_ SG_ 90 DrQltyDrv_D_StatGsm "Signal not transmitted on vehicles that do not have shift by wire.";
CM_ SG_ 90 TrnBtsiOvrrd_B_Stat "Signal not transmitted on vehicles that do not have shift by wire.";
CM_ SG_ 90 TrnValidGearRq_D_Stat "Signal not transmitted on vehicles that do not have shift by wire.";
CM_ SG_ 90 TrnGearRqCnt_B_Actl "Signal not transmitted on vehicles that do not have shift by wire.";
CM_ SG_ 90 TrnGearButtn_U_Actl "Signal not transmitted on vehicles that do not have shift by wire.";
CM_ SG_ 90 TrnGearButtn_B_ActlR2 "Signal not transmitted on vehicles that do not have shift by wire.";
CM_ SG_ 90 TrnGearButtn_B_ActlR1 "Signal not transmitted on vehicles that do not have shift by wire.";
CM_ SG_ 90 TrnGearButtn_B_ActlR0 "Signal not transmitted on vehicles that do not have shift by wire.";
CM_ SG_ 90 TrnGearButtn_B_ActlP2 "Signal not transmitted on vehicles that do not have shift by wire.";
CM_ SG_ 90 TrnGearButtn_B_ActlP1 "Signal not transmitted on vehicles that do not have shift by wire.";
CM_ SG_ 90 TrnGearButtn_B_ActlP0 "Signal not transmitted on vehicles that do not have shift by wire.";
CM_ SG_ 90 TrnGearButtn_B_ActlN2 "Signal not transmitted on vehicles that do not have shift by wire.";
CM_ SG_ 90 TrnGearButtn_B_ActlN1 "Signal not transmitted on vehicles that do not have shift by wire.";
CM_ SG_ 90 TrnGearButtn_B_ActlN0 "Signal not transmitted on vehicles that do not have shift by wire.";
CM_ SG_ 90 TrnGearButtn_B_ActlM2 "Signal not transmitted on vehicles that do not have shift by wire.";
CM_ SG_ 90 TrnGearButtn_B_ActlM1 "Signal not transmitted on vehicles that do not have shift by wire.";
CM_ SG_ 90 TrnGearButtn_B_ActlM0 "Signal not transmitted on vehicles that do not have shift by wire.";
CM_ SG_ 90 TrnGearButtn_B_ActlD2 "Signal not transmitted on vehicles that do not have shift by wire.";
CM_ SG_ 90 TrnGearButtn_B_ActlD1 "Signal not transmitted on vehicles that do not have shift by wire.";
CM_ SG_ 90 TrnGearButtn_B_ActlD0 "Signal not transmitted on vehicles that do not have shift by wire.";
CM_ SG_ 90 TrnGear_No_Cs "Signal not transmitted on vehicles that do not have shift by wire.";
CM_ SG_ 90 TrnGear_No_Cnt "Signal not transmitted on vehicles that do not have shift by wire.";
CM_ SG_ 90 TrnGear_D_RqDrv "Signal not transmitted on vehicles that do not have shift by wire.";
CM_ SG_ 90 BrkSwtchPos_B_ActlGsm "Signal not transmitted on vehicles that do not have shift by wire.";
CM_ SG_ 482 SDARS_Firm_Update2_St "Object Tuner.SDARS Tuner.FirmwareUpdate";
CM_ SG_ 482 SDARS_UnSubscrb_Chan2_St "Object Tuner.SDARS Tuner.Unsubscribed Channel ";
CM_ SG_ 482 SDARS_UnSubscrb2_St "Object Tuner.SDARS Tuner.Unsubscribed Receiver ";
CM_ SG_ 482 SDARS_Subscription2_St "Object Tuner.SDARS Tuner.Subscription Update ";
CM_ SG_ 482 SDARS_Seek_Scan2_St "Method SDARS_Error_Msg
Int Seek/Scan No Channels Available

0x1: No Channel Available
Object Tuner.SDARS Tuner.";
CM_ SG_ 482 SDARS_Receive_Err2_St "Object Tuner.SDARS Tuner.Receiver Error";
CM_ SG_ 482 SDARS_Loss_Ant2_St "Object Tuner.SDARS Tuner.Loss of Antenna Signal ";
CM_ SG_ 482 SDARS_Invalid_Chan2_St "Object Tuner.SDARS Tuner.";
CM_ SG_ 482 SDARS_GCI_Update2_St "Object Tuner.SDARS Tuner.GCI Update ";
CM_ SG_ 482 SDARS_Error_Conf2_St "Object Tuner.SDARS Tuner.Configuration Status";
CM_ SG_ 482 SDARS_Antenna_Err2_St "Object Tuner.SDARS Tuner.Antenna Error";
CM_ SG_ 764 SDARS_SID2_St "Object Tuner.SDARS.ServiceID
$0: SID_0
$1: SID_1
$2: SID_2
$FE: SID_254
$FF: SID_255

";
CM_ SG_ 764 SDARS_CurrentChanNum2_St "Object Tuner.SDARS Tuner.CurrentChanNum.ChanNum 
$0: Channel_0
$1: Channel_1
$2: Channel_2
$FE: Channel_254
$FF: Inactive";
CM_ SG_ 764 SDARS_Channel_Lock2 "Method SDARS_Channel_Lock";
CM_ BO_ 581 "TP message";
CM_ SG_ 501 Dsp_PresetArea_Rq "Object Tuner.GetPresetInfo2.PresetArea

$5: Get AMAST (MW) Preset Data
$6: Get AM (LW) Preset Data";
CM_ SG_ 501 Dsp_StartIndex2_Rq "Object Tuner.GetPresetInfo2.StartingIndex

$1-$FF: Preset 1 to 255";
CM_ SG_ 501 Dsp_SetRadSeekMode_Rq "Object Tuner.SetRadioSeekMode";
CM_ SG_ 501 Dsp_SetCurrPreset2_Rq "Object Tuner.SetCurrentPreset2

$1-$1E: Preset 1 to 30
$0: Inactive
";
CM_ SG_ 501 Dsp_SetCurrFMSLPr_Rq "Object.AMFMSlave.SetCurrentSLStation.Rq.Index
0x01 : Index 1
0x02 : Index 2
0x03 : Index 3
...
...
0xFE : Index 254";
CM_ SG_ 501 Dsp_SetCRadioBand_Rq "Object Tuner.SetCurrRadioBand
$5: AM (LLN, HLN: MW)
$6: AM AST (LLN, HLN: LW)";
CM_ BO_ 651 "TCU CPPM Tx";
CM_ SG_ 415 LBC3_StartItemInd "Object. ListBrowser.ItemInf.Rq.StartItemInd
0x0000:Inactive
0x0001:1
0xFFFE:65634
0xFFFF:Reserved";
CM_ SG_ 415 LBC3_SetListServ "Object. ListBrowser.ItemInf.Rq.SetListServ
0x00:Inactive
0x01:ServerID_1
0xFF:ALL";
CM_ SG_ 415 LBC3_Opcode "Object. ListBrowser.ItemInf.Rq.Opcode";
CM_ SG_ 415 LBC3_NbrOfItems "Object. ListBrowser.ItemInf.Rq.NbrOfItems
0x00:Inactive
0x01:1Item
0x3F:63Items";
CM_ SG_ 415 LBC3_ItemIndex "Object. ListBrowser.ItemInf.Rq.ItemIndex
0x0000:BrowseActiveListID
0x0001:EntryIndex_1
0xFFFF:ParentOfActiveListID";
CM_ SG_ 415 LBC3_ActiveListID "Object. ListBrowser.ItemInf.Rq.ActiveListID
0x0000:Root
0xFFFF:Reserved";
CM_ SG_ 695 CONMP_MC_WORD_Tx "MM ISO 15765-2 Message Catalogue
Section CONMP - MC
Section MediaPlayerServer - MediaPlayerClient";
CM_ SG_ 703 CONMP_MC_WORD_Rx "MM ISO 15765-2 Message Catalogue
Section CONMP - MC
Section MediaPlayerServer - MediaPlayerClient";
CM_ BO_ 885 "NOTE: START BITS 8-11 MUST BE OPEN SPEC REQUIREMENT";
CM_ SG_ 1119 LocationServices_2 "Tx by HS3 APIM";
CM_ SG_ 1118 LocationServices_1 "Tx by HS3 APIM";
CM_ BO_ 554 "TCU_CPPM Tx";
CM_ SG_ 419 MK_SpeedValue_Rq "Object MyKey.1 SpeedSettingConfig_Rq.SpeedValue (Parameter2)";
CM_ SG_ 419 MK_SpeedSetting_Rq "Object MyKey.1 SpeedSettingConfig_Rq.SpeedSetting (Parameter1)";
CM_ SG_ 419 MK_ResetAllUserKeys_Rq "Object MyKey.ResetAllKeys_Rq";
CM_ SG_ 419 MK_MyKeySystemInfo_Rq "Object MyKey.MyKeySystemInfo_Rq";
CM_ SG_ 419 MK_ESCRestrictConf_Rq "Object MyKey.ESCRestrictionConfig_Rq";
CM_ SG_ 419 MK_ECalRestrictConf_Rq "Object MyKey.ECallRestrictionConfig_Rq";
CM_ SG_ 419 MK_DNDRestrictConf_Rq "Object MyKey.DNDRestrictionConfig_Rq";
CM_ SG_ 419 MK_CreateMyKey_Rq "Object MyKey.CreateMyKey_Rq";
CM_ SG_ 419 MK_AudioLimitConfig_Rq "Object MyKey.AudioLimitConfig_Rq";
CM_ SG_ 419 MK_ACSRestrictConf_Rq "Object MyKey.ACSRestrictionConfig_Rq";
CM_ SG_ 542 LocationServices_3 "Tx by HS3 APIM";
BA_DEF_ BO_  "FrameRouting" STRING ;
BA_DEF_ BO_  "NetworkInitialization" ENUM  "No","Yes";
BA_DEF_ BO_  "GenMsgStartDelayTime" INT 0 10000;
BA_DEF_ BO_  "GenMsgNrOfRepetition" INT 0 100;
BA_DEF_ BO_  "GenMsgDelayTime" INT 0 1000;
BA_DEF_ BO_  "GenMsgCycleTime" INT 0 100000;
BA_DEF_ BO_  "GenMsgSendType" ENUM  "FixedPeriodic","Event","EnabledPeriodic","NotUsed","NotUsed","EventPeriodic","NotUsed","NotUsed","NoMsgSendType";
BA_DEF_ SG_  "U_V710_MY2023_Tx" ENUM  "No","Yes";
BA_DEF_ SG_  "U_P708_MY2023_Tx" ENUM  "No","Yes";
BA_DEF_ SG_  "U_V713AV_MY2022_Tx" ENUM  "No","Yes";
BA_DEF_ SG_  "U_V713N_MY2022_Tx" ENUM  "No","Yes";
BA_DEF_ SG_  "ECGUsedTxSignal" ENUM  "No","Yes";
BA_DEF_ SG_  "U_V710_MY2023_Rx" ENUM  "No","Yes";
BA_DEF_ SG_  "U_P708_MY2023_Rx" ENUM  "No","Yes";
BA_DEF_ SG_  "U_V713AV_MY2022_Rx" ENUM  "No","Yes";
BA_DEF_ SG_  "U_V713N_MY2022_Rx" ENUM  "No","Yes";
BA_DEF_ SG_  "ECGUsedRxSignal" ENUM  "No","Yes";
BA_DEF_ SG_  "UsedOnPgmDBC" ENUM  "No","Yes";
BA_DEF_ SG_  "ContentDependant" ENUM  "No","Yes";
BA_DEF_ SG_  "GenSigStartValue" HEX 0 268435455;
BA_DEF_ SG_  "MetaData" ENUM  "No","Yes";
BA_DEF_ SG_  "WakeupSignal" ENUM  "No","Yes";
BA_DEF_ SG_  "GenSigInactiveValue" INT 0 100000;
BA_DEF_ SG_  "GenSigSendType" ENUM  "Cyclic","OnWrite","vector_leerstring","OnChange","vector_leerstring","IfActive","vector_leerstring","NoSigSendType";
BA_DEF_ BO_  "TpTxIndex" INT 0 536870911;
BA_DEF_ BO_  "OvtpPushApplication" ENUM  "FALSE","TRUE";
BA_DEF_ BO_  "SCP_FreshnessValueLength" INT 0 512;
BA_DEF_ BO_  "SCP_DataId" INT 0 17663;
BA_DEF_ BO_  "SCP_FreshnessValueTxLength" INT 0 512;
BA_DEF_ BO_  "SCP_AuthInfoTxLength" INT 0 512;
BA_DEF_ BO_  "SC_Message" ENUM  "No","Yes";
BA_DEF_ BO_  "GenMsgRoutingTimeoutTime" INT 0 5000;
BA_DEF_ BO_  "MessageGateway" ENUM  "No","Yes";
BA_DEF_ BO_  "NmAsrMessage" ENUM  "No","Yes";
BA_DEF_ BO_  "DiagState" ENUM  "No","Yes";
BA_DEF_ BO_  "DiagRequest" ENUM  "No","Yes";
BA_DEF_ BO_  "DiagResponse" ENUM  "No","Yes";
BA_DEF_ BO_  "GenMsgILSupport" ENUM  "No","Yes";
BA_DEF_DEF_  "FrameRouting" "";
BA_DEF_DEF_  "NetworkInitialization" "Yes";
BA_DEF_DEF_  "GenMsgStartDelayTime" 0;
BA_DEF_DEF_  "GenMsgNrOfRepetition" 1;
BA_DEF_DEF_  "GenMsgDelayTime" 20;
BA_DEF_DEF_  "GenMsgCycleTime" 0;
BA_DEF_DEF_  "GenMsgSendType" "NoMsgSendType";
BA_DEF_DEF_  "U_V710_MY2023_Tx" "No";
BA_DEF_DEF_  "U_P708_MY2023_Tx" "No";
BA_DEF_DEF_  "U_V713AV_MY2022_Tx" "No";
BA_DEF_DEF_  "U_V713N_MY2022_Tx" "No";
BA_DEF_DEF_  "ECGUsedTxSignal" "No";
BA_DEF_DEF_  "U_V710_MY2023_Rx" "No";
BA_DEF_DEF_  "U_P708_MY2023_Rx" "No";
BA_DEF_DEF_  "U_V713AV_MY2022_Rx" "No";
BA_DEF_DEF_  "U_V713N_MY2022_Rx" "No";
BA_DEF_DEF_  "ECGUsedRxSignal" "No";
BA_DEF_DEF_  "UsedOnPgmDBC" "Yes";
BA_DEF_DEF_  "ContentDependant" "No";
BA_DEF_DEF_  "GenSigStartValue" 0;
BA_DEF_DEF_  "MetaData" "No";
BA_DEF_DEF_  "WakeupSignal" "No";
BA_DEF_DEF_  "GenSigInactiveValue" 0;
BA_DEF_DEF_  "GenSigSendType" "NoSigSendType";
BA_DEF_DEF_  "TpTxIndex" 0;
BA_DEF_DEF_  "OvtpPushApplication" "FALSE";
BA_DEF_DEF_  "SCP_FreshnessValueLength" 64;
BA_DEF_DEF_  "SCP_DataId" 0;
BA_DEF_DEF_  "SCP_FreshnessValueTxLength" 11;
BA_DEF_DEF_  "SCP_AuthInfoTxLength" 53;
BA_DEF_DEF_  "SC_Message" "No";
BA_DEF_DEF_  "GenMsgRoutingTimeoutTime" 0;
BA_DEF_DEF_  "MessageGateway" "No";
BA_DEF_DEF_  "NmAsrMessage" "No";
BA_DEF_DEF_  "DiagState" "No";
BA_DEF_DEF_  "DiagRequest" "No";
BA_DEF_DEF_  "DiagResponse" "No";
BA_DEF_DEF_  "GenMsgILSupport" "Yes";
BA_ "GenMsgSendType" BO_ 412 1;
BA_ "GenMsgSendType" BO_ 493 1;
BA_ "GenMsgSendType" BO_ 511 1;
BA_ "GenMsgSendType" BO_ 257 1;
BA_ "FrameRouting" BO_ 972 "HS2_CAN,0x3CC;FD1_CAN,0x3CC;FD3_CAN,0x3CC";
BA_ "FrameRouting" BO_ 1120 "HS2_CAN,0x460;";
BA_ "FrameRouting" BO_ 1087 "FD1_CAN,0x43F;";
BA_ "FrameRouting" BO_ 787 "MS1_CAN,0x313;";
BA_ "FrameRouting" BO_ 819 "FD3_CAN,0x333;";
BA_ "FrameRouting" BO_ 818 "FD3_CAN,0x332;";
BA_ "FrameRouting" BO_ 1164 "MS1_CAN,0x48C;";
BA_ "FrameRouting" BO_ 1163 "MS1_CAN,0x48B;";
BA_ "FrameRouting" BO_ 1166 "MS1_CAN,0x48E;";
BA_ "FrameRouting" BO_ 1165 "MS1_CAN,0x48D;";
BA_ "FrameRouting" BO_ 556 "MS1_CAN,0x22C;";
BA_ "GenMsgCycleTime" BO_ 556 1000;
BA_ "GenMsgSendType" BO_ 556 5;
BA_ "FrameRouting" BO_ 1101 "FD1_CAN,0x44D;";
BA_ "FrameRouting" BO_ 130 "FD1_CAN,0x82;FD3_CAN,0x82";
BA_ "TpTxIndex" BO_ 713 27;
BA_ "FrameRouting" BO_ 382 "FD1_CAN,0x17E;";
BA_ "FrameRouting" BO_ 877 "MS1_CAN,0x36D;";
BA_ "TpTxIndex" BO_ 600 50;
BA_ "TpTxIndex" BO_ 708 33;
BA_ "GenMsgSendType" BO_ 414 1;
BA_ "FrameRouting" BO_ 619 "FD2_CAN,0x26B;";
BA_ "FrameRouting" BO_ 953 "FD1_CAN,0x3B9;";
BA_ "FrameRouting" BO_ 985 "FD1_CAN,0x3D9;FD3_CAN,0x3D9";
BA_ "FrameRouting" BO_ 770 "FD1_CAN,0x302;";
BA_ "TpTxIndex" BO_ 716 33;
BA_ "FrameRouting" BO_ 1013 "FD1_CAN,0x3F5;";
BA_ "FrameRouting" BO_ 1012 "FD1_CAN,0x3F4;";
BA_ "FrameRouting" BO_ 1011 "FD1_CAN,0x3F3;";
BA_ "GenMsgCycleTime" BO_ 533 1000;
BA_ "GenMsgSendType" BO_ 533 5;
BA_ "FrameRouting" BO_ 1184 "FD2_CAN,0x4A0;";
BA_ "TpTxIndex" BO_ 1184 20;
BA_ "GenMsgCycleTime" BO_ 801 1000;
BA_ "GenMsgSendType" BO_ 801 5;
BA_ "GenMsgCycleTime" BO_ 878 1000;
BA_ "GenMsgSendType" BO_ 878 5;
BA_ "TpTxIndex" BO_ 1192 20;
BA_ "GenMsgSendType" BO_ 259 1;
BA_ "GenMsgCycleTime" BO_ 538 1000;
BA_ "GenMsgSendType" BO_ 538 5;
BA_ "NetworkInitialization" BO_ 422 0;
BA_ "GenMsgSendType" BO_ 422 1;
BA_ "FrameRouting" BO_ 1041 "HS2_CAN,0x411;";
BA_ "GenMsgCycleTime" BO_ 890 1000;
BA_ "GenMsgSendType" BO_ 890 5;
BA_ "NetworkInitialization" BO_ 2008 0;
BA_ "GenMsgSendType" BO_ 2008 1;
BA_ "DiagResponse" BO_ 2008 1;
BA_ "GenMsgILSupport" BO_ 2008 0;
BA_ "FrameRouting" BO_ 884 "MS1_CAN,0x374;";
BA_ "FrameRouting" BO_ 883 "MS1_CAN,0x373;";
BA_ "FrameRouting" BO_ 1090 "FD1_CAN,0x442;";
BA_ "FrameRouting" BO_ 592 "FD2_CAN,0x250;";
BA_ "TpTxIndex" BO_ 592 50;
BA_ "TpTxIndex" BO_ 715 23;
BA_ "GenMsgSendType" BO_ 473 1;
BA_ "NetworkInitialization" BO_ 2000 0;
BA_ "GenMsgDelayTime" BO_ 2000 0;
BA_ "GenMsgSendType" BO_ 2000 1;
BA_ "DiagRequest" BO_ 2000 1;
BA_ "GenMsgILSupport" BO_ 2000 0;
BA_ "FrameRouting" BO_ 90 "FD3_CAN,0x5A;";
BA_ "FrameRouting" BO_ 1021 "MS2_CAN,0x3FD;";
BA_ "NetworkInitialization" BO_ 2611166424 0;
BA_ "GenMsgDelayTime" BO_ 2611166424 0;
BA_ "GenMsgSendType" BO_ 2611166424 1;
BA_ "TpTxIndex" BO_ 2611166424 463682776;
BA_ "GenMsgCycleTime" BO_ 482 1000;
BA_ "GenMsgSendType" BO_ 482 5;
BA_ "GenMsgCycleTime" BO_ 764 1000;
BA_ "GenMsgSendType" BO_ 764 5;
BA_ "NetworkInitialization" BO_ 1188 0;
BA_ "TpTxIndex" BO_ 1188 55;
BA_ "FrameRouting" BO_ 139 "HS2_CAN,0x8B;";
BA_ "FrameRouting" BO_ 837 "FD1_CAN,0x345;HS2_CAN,0x345";
BA_ "FrameRouting" BO_ 146 "HS2_CAN,0x92;";
BA_ "FrameRouting" BO_ 925 "FD1_CAN,0x39D;";
BA_ "FrameRouting" BO_ 581 "FD2_CAN,0x245;";
BA_ "TpTxIndex" BO_ 581 30;
BA_ "GenMsgSendType" BO_ 501 1;
BA_ "NetworkInitialization" BO_ 1506 0;
BA_ "GenMsgCycleTime" BO_ 1506 1000;
BA_ "GenMsgSendType" BO_ 1506 0;
BA_ "NmAsrMessage" BO_ 1506 1;
BA_ "GenMsgILSupport" BO_ 1506 0;
BA_ "FrameRouting" BO_ 651 "FD2_CAN,0x28B;";
BA_ "FrameRouting" BO_ 1098 "FD1_CAN,0x44A;";
BA_ "GenMsgCycleTime" BO_ 1239 1000;
BA_ "GenMsgSendType" BO_ 1239 5;
BA_ "FrameRouting" BO_ 785 "FD1_CAN,0x311;";
BA_ "TpTxIndex" BO_ 1210 40;
BA_ "TpTxIndex" BO_ 1202 40;
BA_ "GenMsgSendType" BO_ 415 1;
BA_ "TpTxIndex" BO_ 695 18;
BA_ "NetworkInitialization" BO_ 703 0;
BA_ "TpTxIndex" BO_ 703 18;
BA_ "NetworkInitialization" BO_ 1829 0;
BA_ "GenMsgDelayTime" BO_ 1829 0;
BA_ "GenMsgSendType" BO_ 1829 1;
BA_ "DiagRequest" BO_ 1829 1;
BA_ "GenMsgILSupport" BO_ 1829 0;
BA_ "FrameRouting" BO_ 332 "FD1_CAN,0x14C;";
BA_ "GenMsgDelayTime" BO_ 2612224096 0;
BA_ "GenMsgSendType" BO_ 2612224096 1;
BA_ "TpTxIndex" BO_ 2612224096 464617688;
BA_ "OvtpPushApplication" BO_ 2612224096 1;
BA_ "NetworkInitialization" BO_ 2612101336 0;
BA_ "GenMsgDelayTime" BO_ 2612101336 0;
BA_ "GenMsgSendType" BO_ 2612101336 1;
BA_ "TpTxIndex" BO_ 2612101336 464617688;
BA_ "OvtpPushApplication" BO_ 2612101336 1;
BA_ "FrameRouting" BO_ 636 "FD2_CAN,0x27C;";
BA_ "GenMsgCycleTime" BO_ 805 100;
BA_ "GenMsgSendType" BO_ 805 0;
BA_ "GenMsgCycleTime" BO_ 804 1000;
BA_ "GenMsgSendType" BO_ 804 5;
BA_ "GenMsgCycleTime" BO_ 803 1000;
BA_ "GenMsgSendType" BO_ 803 5;
BA_ "GenMsgCycleTime" BO_ 802 1000;
BA_ "GenMsgSendType" BO_ 802 5;
BA_ "GenMsgCycleTime" BO_ 812 1000;
BA_ "GenMsgSendType" BO_ 812 5;
BA_ "GenMsgCycleTime" BO_ 885 200;
BA_ "GenMsgSendType" BO_ 885 0;
BA_ "FrameRouting" BO_ 784 "MS2_CAN,0x310;";
BA_ "GenMsgSendType" BO_ 1119 1;
BA_ "GenMsgSendType" BO_ 1118 1;
BA_ "GenMsgSendType" BO_ 290 1;
BA_ "GenMsgCycleTime" BO_ 554 1000;
BA_ "GenMsgSendType" BO_ 554 5;
BA_ "GenMsgSendType" BO_ 419 1;
BA_ "FrameRouting" BO_ 542 "FD2_CAN,0x21E;";
BA_ "U_V710_MY2023_Rx" SG_ 412 LBC2_StartItemInd 1;
BA_ "U_P708_MY2023_Rx" SG_ 412 LBC2_StartItemInd 1;
BA_ "U_V713AV_MY2022_Rx" SG_ 412 LBC2_StartItemInd 1;
BA_ "U_V713N_MY2022_Rx" SG_ 412 LBC2_StartItemInd 1;
BA_ "U_V710_MY2023_Rx" SG_ 412 LBC2_SetListServ 1;
BA_ "U_P708_MY2023_Rx" SG_ 412 LBC2_SetListServ 1;
BA_ "U_V713AV_MY2022_Rx" SG_ 412 LBC2_SetListServ 1;
BA_ "U_V713N_MY2022_Rx" SG_ 412 LBC2_SetListServ 1;
BA_ "U_V710_MY2023_Rx" SG_ 412 LBC2_Opcode 1;
BA_ "U_P708_MY2023_Rx" SG_ 412 LBC2_Opcode 1;
BA_ "U_V713AV_MY2022_Rx" SG_ 412 LBC2_Opcode 1;
BA_ "U_V713N_MY2022_Rx" SG_ 412 LBC2_Opcode 1;
BA_ "GenSigSendType" SG_ 412 LBC2_Opcode 3;
BA_ "U_V710_MY2023_Rx" SG_ 412 LBC2_NbrOfItems 1;
BA_ "U_P708_MY2023_Rx" SG_ 412 LBC2_NbrOfItems 1;
BA_ "U_V713AV_MY2022_Rx" SG_ 412 LBC2_NbrOfItems 1;
BA_ "U_V713N_MY2022_Rx" SG_ 412 LBC2_NbrOfItems 1;
BA_ "U_V710_MY2023_Rx" SG_ 412 LBC2_ItemIndex 1;
BA_ "U_P708_MY2023_Rx" SG_ 412 LBC2_ItemIndex 1;
BA_ "U_V713AV_MY2022_Rx" SG_ 412 LBC2_ItemIndex 1;
BA_ "U_V713N_MY2022_Rx" SG_ 412 LBC2_ItemIndex 1;
BA_ "U_V710_MY2023_Rx" SG_ 412 LBC2_ActiveListID 1;
BA_ "U_P708_MY2023_Rx" SG_ 412 LBC2_ActiveListID 1;
BA_ "U_V713AV_MY2022_Rx" SG_ 412 LBC2_ActiveListID 1;
BA_ "U_V713N_MY2022_Rx" SG_ 412 LBC2_ActiveListID 1;
BA_ "U_V710_MY2023_Rx" SG_ 493 Dsp_StatLiScanCancel_Rq 1;
BA_ "U_P708_MY2023_Rx" SG_ 493 Dsp_StatLiScanCancel_Rq 1;
BA_ "U_V713AV_MY2022_Rx" SG_ 493 Dsp_StatLiScanCancel_Rq 1;
BA_ "U_V713N_MY2022_Rx" SG_ 493 Dsp_StatLiScanCancel_Rq 1;
BA_ "GenSigSendType" SG_ 493 Dsp_StatLiScanCancel_Rq 3;
BA_ "U_V710_MY2023_Rx" SG_ 493 Dsp_StationList_Rq 1;
BA_ "U_P708_MY2023_Rx" SG_ 493 Dsp_StationList_Rq 1;
BA_ "U_V713AV_MY2022_Rx" SG_ 493 Dsp_StationList_Rq 1;
BA_ "U_V713N_MY2022_Rx" SG_ 493 Dsp_StationList_Rq 1;
BA_ "GenSigSendType" SG_ 493 Dsp_StationList_Rq 3;
BA_ "U_V710_MY2023_Rx" SG_ 493 Dsp_StartIndex3_Rq 1;
BA_ "U_P708_MY2023_Rx" SG_ 493 Dsp_StartIndex3_Rq 1;
BA_ "U_V713AV_MY2022_Rx" SG_ 493 Dsp_StartIndex3_Rq 1;
BA_ "U_V713N_MY2022_Rx" SG_ 493 Dsp_StartIndex3_Rq 1;
BA_ "U_V710_MY2023_Rx" SG_ 493 Dsp_RefreshFlag 1;
BA_ "U_P708_MY2023_Rx" SG_ 493 Dsp_RefreshFlag 1;
BA_ "U_V713AV_MY2022_Rx" SG_ 493 Dsp_RefreshFlag 1;
BA_ "U_V713N_MY2022_Rx" SG_ 493 Dsp_RefreshFlag 1;
BA_ "U_V710_MY2023_Rx" SG_ 493 Dsp_PTYCode_Rq 1;
BA_ "U_P708_MY2023_Rx" SG_ 493 Dsp_PTYCode_Rq 1;
BA_ "U_V713AV_MY2022_Rx" SG_ 493 Dsp_PTYCode_Rq 1;
BA_ "U_V713N_MY2022_Rx" SG_ 493 Dsp_PTYCode_Rq 1;
BA_ "U_V710_MY2023_Rx" SG_ 493 Dsp_ListSize_Rq 1;
BA_ "U_P708_MY2023_Rx" SG_ 493 Dsp_ListSize_Rq 1;
BA_ "U_V713AV_MY2022_Rx" SG_ 493 Dsp_ListSize_Rq 1;
BA_ "U_V713N_MY2022_Rx" SG_ 493 Dsp_ListSize_Rq 1;
BA_ "U_V710_MY2023_Rx" SG_ 493 Dsp_AFJump_Rq 1;
BA_ "U_P708_MY2023_Rx" SG_ 493 Dsp_AFJump_Rq 1;
BA_ "U_V713AV_MY2022_Rx" SG_ 493 Dsp_AFJump_Rq 1;
BA_ "U_V713N_MY2022_Rx" SG_ 493 Dsp_AFJump_Rq 1;
BA_ "GenSigSendType" SG_ 493 Dsp_AFJump_Rq 3;
BA_ "U_V710_MY2023_Rx" SG_ 511 Dsp_TUStartIndex2_Rq 1;
BA_ "U_P708_MY2023_Rx" SG_ 511 Dsp_TUStartIndex2_Rq 1;
BA_ "U_V713AV_MY2022_Rx" SG_ 511 Dsp_TUStartIndex2_Rq 1;
BA_ "U_V713N_MY2022_Rx" SG_ 511 Dsp_TUStartIndex2_Rq 1;
BA_ "U_V710_MY2023_Rx" SG_ 511 Dsp_TUPresetArea_Rq 1;
BA_ "U_P708_MY2023_Rx" SG_ 511 Dsp_TUPresetArea_Rq 1;
BA_ "U_V713AV_MY2022_Rx" SG_ 511 Dsp_TUPresetArea_Rq 1;
BA_ "U_V713N_MY2022_Rx" SG_ 511 Dsp_TUPresetArea_Rq 1;
BA_ "GenSigSendType" SG_ 511 Dsp_TUPresetArea_Rq 3;
BA_ "U_V710_MY2023_Rx" SG_ 511 Dsp_TUNbrOfPresets_Rq 1;
BA_ "U_P708_MY2023_Rx" SG_ 511 Dsp_TUNbrOfPresets_Rq 1;
BA_ "U_V713AV_MY2022_Rx" SG_ 511 Dsp_TUNbrOfPresets_Rq 1;
BA_ "U_V713N_MY2022_Rx" SG_ 511 Dsp_TUNbrOfPresets_Rq 1;
BA_ "U_V710_MY2023_Rx" SG_ 511 Dsp_SetCurrTUPreset_Rq 1;
BA_ "U_P708_MY2023_Rx" SG_ 511 Dsp_SetCurrTUPreset_Rq 1;
BA_ "U_V713AV_MY2022_Rx" SG_ 511 Dsp_SetCurrTUPreset_Rq 1;
BA_ "U_V713N_MY2022_Rx" SG_ 511 Dsp_SetCurrTUPreset_Rq 1;
BA_ "GenSigSendType" SG_ 511 Dsp_SetCurrTUPreset_Rq 3;
BA_ "U_V710_MY2023_Rx" SG_ 511 Dsp_SetCurrTUBand_Rq 1;
BA_ "U_P708_MY2023_Rx" SG_ 511 Dsp_SetCurrTUBand_Rq 1;
BA_ "U_V713AV_MY2022_Rx" SG_ 511 Dsp_SetCurrTUBand_Rq 1;
BA_ "U_V713N_MY2022_Rx" SG_ 511 Dsp_SetCurrTUBand_Rq 1;
BA_ "GenSigSendType" SG_ 511 Dsp_SetCurrTUBand_Rq 3;
BA_ "U_V710_MY2023_Rx" SG_ 511 SdarsAudioRtng_D_Rq 1;
BA_ "U_P708_MY2023_Rx" SG_ 511 SdarsAudioRtng_D_Rq 1;
BA_ "U_V713N_MY2022_Rx" SG_ 511 SdarsAudioRtng_D_Rq 1;
BA_ "GenSigSendType" SG_ 511 SdarsAudioRtng_D_Rq 3;
BA_ "U_V710_MY2023_Rx" SG_ 257 MFD_SetTagMode 1;
BA_ "U_P708_MY2023_Rx" SG_ 257 MFD_SetTagMode 1;
BA_ "U_V713AV_MY2022_Rx" SG_ 257 MFD_SetTagMode 1;
BA_ "U_V713N_MY2022_Rx" SG_ 257 MFD_SetTagMode 1;
BA_ "GenSigSendType" SG_ 257 MFD_SetTagMode 3;
BA_ "U_V710_MY2023_Rx" SG_ 257 MFD_SetRBDSMode 1;
BA_ "U_P708_MY2023_Rx" SG_ 257 MFD_SetRBDSMode 1;
BA_ "U_V713AV_MY2022_Rx" SG_ 257 MFD_SetRBDSMode 1;
BA_ "U_V713N_MY2022_Rx" SG_ 257 MFD_SetRBDSMode 1;
BA_ "GenSigSendType" SG_ 257 MFD_SetRBDSMode 3;
BA_ "U_V710_MY2023_Rx" SG_ 257 MFD_SetHDModeRq 1;
BA_ "U_P708_MY2023_Rx" SG_ 257 MFD_SetHDModeRq 1;
BA_ "U_V713AV_MY2022_Rx" SG_ 257 MFD_SetHDModeRq 1;
BA_ "U_V713N_MY2022_Rx" SG_ 257 MFD_SetHDModeRq 1;
BA_ "GenSigSendType" SG_ 257 MFD_SetHDModeRq 3;
BA_ "U_V710_MY2023_Rx" SG_ 257 MFD_GetTagInfo 1;
BA_ "U_P708_MY2023_Rx" SG_ 257 MFD_GetTagInfo 1;
BA_ "U_V713AV_MY2022_Rx" SG_ 257 MFD_GetTagInfo 1;
BA_ "U_V713N_MY2022_Rx" SG_ 257 MFD_GetTagInfo 1;
BA_ "GenSigSendType" SG_ 257 MFD_GetTagInfo 3;
BA_ "MetaData" SG_ 972 LatCtlCpbltyDStat_No_Cs 1;
BA_ "MetaData" SG_ 972 LatCtlCpbltyDStat_No_Cnt 1;
BA_ "GenSigStartValue" SG_ 972 TjaHandsOnCnfdnc_B_Est 1;
BA_ "U_P708_MY2023_Rx" SG_ 972 LaHandsOff_B_Actl 1;
BA_ "U_V713AV_MY2022_Rx" SG_ 972 LaHandsOff_B_Actl 1;
BA_ "U_V713N_MY2022_Rx" SG_ 972 LaHandsOff_B_Actl 1;
BA_ "GenSigStartValue" SG_ 972 LaHandsOff_B_Actl 1;
BA_ "U_P708_MY2023_Rx" SG_ 972 LaActDeny_B_Actl 1;
BA_ "U_V713AV_MY2022_Rx" SG_ 972 LaActDeny_B_Actl 1;
BA_ "U_V713N_MY2022_Rx" SG_ 972 LaActDeny_B_Actl 1;
BA_ "GenSigStartValue" SG_ 1120 FrontDiffLck_D_RqDrv 2;
BA_ "GenSigStartValue" SG_ 1120 AwdLck_D_RqDrv 2;
BA_ "U_P708_MY2023_Rx" SG_ 1120 RearDiffLck_D_RqDrv 1;
BA_ "U_V713AV_MY2022_Rx" SG_ 1120 RearDiffLck_D_RqDrv 1;
BA_ "U_V713N_MY2022_Rx" SG_ 1120 RearDiffLck_D_RqDrv 1;
BA_ "GenSigStartValue" SG_ 1120 RearDiffLck_D_RqDrv 2;
BA_ "U_P708_MY2023_Rx" SG_ 1120 AwdMde_D_RqDrv 1;
BA_ "U_V713AV_MY2022_Rx" SG_ 1120 AwdMde_D_RqDrv 1;
BA_ "U_V713N_MY2022_Rx" SG_ 1120 AwdMde_D_RqDrv 1;
BA_ "GenSigStartValue" SG_ 1120 AwdMde_D_RqDrv 5;
BA_ "U_P708_MY2023_Rx" SG_ 1087 StrtInGearMsgTxt_D_Rq 1;
BA_ "U_P708_MY2023_Rx" SG_ 787 PwTgateInhbtMsgTxt_B_Rq 1;
BA_ "WakeupSignal" SG_ 787 DrLckCnt_No_ActlTgate 1;
BA_ "U_P708_MY2023_Rx" SG_ 787 PwTgateStepMsgTxt_B_Rq 1;
BA_ "U_P708_MY2023_Rx" SG_ 787 PwTgateMsgTxt_B_Rq 1;
BA_ "U_P708_MY2023_Rx" SG_ 787 PwTgateLamp_B_Rq 1;
BA_ "U_V710_MY2023_Rx" SG_ 787 DrTgateChime2_D_Rq 1;
BA_ "U_P708_MY2023_Rx" SG_ 787 DrTgateChime2_D_Rq 1;
BA_ "U_V713AV_MY2022_Rx" SG_ 787 DrTgateChime2_D_Rq 1;
BA_ "U_V713N_MY2022_Rx" SG_ 787 DrTgateChime2_D_Rq 1;
BA_ "WakeupSignal" SG_ 787 DrTgateChime2_D_Rq 1;
BA_ "WakeupSignal" SG_ 787 DrTGate_D_Rq 1;
BA_ "WakeupSignal" SG_ 787 PwLftgtIntSw_B_Stat 1;
BA_ "U_V710_MY2023_Rx" SG_ 787 Power_Liftgate_Mode_Stt 1;
BA_ "U_P708_MY2023_Rx" SG_ 787 Power_Liftgate_Mode_Stt 1;
BA_ "U_V713AV_MY2022_Rx" SG_ 787 Power_Liftgate_Mode_Stt 1;
BA_ "U_V713N_MY2022_Rx" SG_ 787 Power_Liftgate_Mode_Stt 1;
BA_ "U_P708_MY2023_Rx" SG_ 819 DrPrsntPsngr_D_Stat 1;
BA_ "WakeupSignal" SG_ 819 DrPrsntPsngr_D_Stat 1;
BA_ "U_P708_MY2023_Rx" SG_ 819 DrPsngrMsgTxt_B_Rq 1;
BA_ "U_P708_MY2023_Rx" SG_ 819 DrPrsntRearPsngr_D_Stat 1;
BA_ "WakeupSignal" SG_ 819 DrPrsntRearPsngr_D_Stat 1;
BA_ "WakeupSignal" SG_ 819 Memory_3_SwPsngr_Stat 1;
BA_ "WakeupSignal" SG_ 819 Memory_2_SwPsngr_Stat 1;
BA_ "WakeupSignal" SG_ 819 Memory_1_SwPsngr_Stat 1;
BA_ "WakeupSignal" SG_ 819 Pasngr_Lock_Sw_Stat 1;
BA_ "MetaData" SG_ 819 Pasngr_Lock_Sw_Cnt 1;
BA_ "WakeupSignal" SG_ 819 Pasngr_Lock_Sw_Cnt 1;
BA_ "WakeupSignal" SG_ 819 ChildLckFdbckRp_B_Stat 1;
BA_ "U_V710_MY2023_Rx" SG_ 818 DrPrsntDrv_D_Stat 1;
BA_ "U_P708_MY2023_Rx" SG_ 818 DrPrsntDrv_D_Stat 1;
BA_ "WakeupSignal" SG_ 818 DrPrsntDrv_D_Stat 1;
BA_ "U_P708_MY2023_Rx" SG_ 818 DrPrsntRearDrv_D_Stat 1;
BA_ "WakeupSignal" SG_ 818 DrPrsntRearDrv_D_Stat 1;
BA_ "U_P708_MY2023_Rx" SG_ 818 DrDrvMsgTxt_B_Rq 1;
BA_ "WakeupSignal" SG_ 818 ChildLckPw_N_Cnt 1;
BA_ "WakeupSignal" SG_ 818 KeyCylSwDrvDr_D_Stat 1;
BA_ "WakeupSignal" SG_ 818 Driver_Lock_Sw_Stat 1;
BA_ "MetaData" SG_ 818 Driver_Lock_Sw_Cnt 1;
BA_ "WakeupSignal" SG_ 818 Driver_Lock_Sw_Cnt 1;
BA_ "WakeupSignal" SG_ 818 ChildLckPw_D_Rq 1;
BA_ "WakeupSignal" SG_ 818 ChildLckFdbckRd_B_Stat 1;
BA_ "U_V713AV_MY2022_Rx" SG_ 818 RvrseMirrorChime_B_Rq 1;
BA_ "U_V713N_MY2022_Rx" SG_ 818 RvrseMirrorChime_B_Rq 1;
BA_ "WakeupSignal" SG_ 1164 DrSwtchInnrFr_No_Rq 1;
BA_ "U_V713AV_MY2022_Rx" SG_ 1164 DrLatchFrMsgTxt_D_Rq 1;
BA_ "U_V713N_MY2022_Rx" SG_ 1164 DrLatchFrMsgTxt_D_Rq 1;
BA_ "WakeupSignal" SG_ 1163 DrSwtchInnrFl_No_Rq 1;
BA_ "U_V713AV_MY2022_Rx" SG_ 1163 DrLatchFlMsgTxt_D_Rq 1;
BA_ "U_V713N_MY2022_Rx" SG_ 1163 DrLatchFlMsgTxt_D_Rq 1;
BA_ "WakeupSignal" SG_ 1166 DrSwtchInnrRr_No_Rq 1;
BA_ "U_V713AV_MY2022_Rx" SG_ 1166 DrLatchRrMsgTxt_D_Rq 1;
BA_ "U_V713N_MY2022_Rx" SG_ 1166 DrLatchRrMsgTxt_D_Rq 1;
BA_ "U_V713AV_MY2022_Rx" SG_ 1165 DrLatchRlMsgTxt_D_Rq 1;
BA_ "U_V713N_MY2022_Rx" SG_ 1165 DrLatchRlMsgTxt_D_Rq 1;
BA_ "WakeupSignal" SG_ 1165 DrSwtchInnrRl_No_Rq 1;
BA_ "GenSigSendType" SG_ 556 Manual_Temp_Setting 3;
BA_ "GenSigSendType" SG_ 556 DrvAsstMnuButtn_B_Stat 3;
BA_ "GenSigSendType" SG_ 556 EFP_Bezel_Diag_St 3;
BA_ "GenSigSendType" SG_ 556 Bezel_Beeps_Supported 3;
BA_ "GenSigSendType" SG_ 556 Bezel_Beep_St 3;
BA_ "GenSigSendType" SG_ 556 PassRstrnInd_Stat 3;
BA_ "U_P708_MY2023_Rx" SG_ 1101 AwdLckLamp_D_Rq 1;
BA_ "U_V713AV_MY2022_Rx" SG_ 1101 AwdLckLamp_D_Rq 1;
BA_ "U_V713N_MY2022_Rx" SG_ 1101 AwdLckLamp_D_Rq 1;
BA_ "U_P708_MY2023_Rx" SG_ 1101 RearDiffLckLamp_D_Rq3 1;
BA_ "U_V713AV_MY2022_Rx" SG_ 1101 RearDiffLckLamp_D_Rq3 1;
BA_ "U_V713N_MY2022_Rx" SG_ 1101 RearDiffLckLamp_D_Rq3 1;
BA_ "U_V713AV_MY2022_Rx" SG_ 130 SteEffort_D_Stat 1;
BA_ "U_V713N_MY2022_Rx" SG_ 130 SteEffort_D_Stat 1;
BA_ "GenSigStartValue" SG_ 130 Veh_V_RqMxTrlrAid 255;
BA_ "GenSigStartValue" SG_ 130 SteMdule_U_Meas 255;
BA_ "GenSigStartValue" SG_ 130 SteMdule_I_Est 4095;
BA_ "U_V710_MY2023_Rx" SG_ 130 EPAS_Failure 1;
BA_ "U_P708_MY2023_Rx" SG_ 130 EPAS_Failure 1;
BA_ "U_V713N_MY2022_Rx" SG_ 130 EPAS_Failure 1;
BA_ "GenSigStartValue" SG_ 130 SteeringColumnTorque 254;
BA_ "U_V710_MY2023_Rx" SG_ 713 SDARS_RDISP_WORD_Rx 1;
BA_ "U_P708_MY2023_Rx" SG_ 713 SDARS_RDISP_WORD_Rx 1;
BA_ "U_V713AV_MY2022_Rx" SG_ 713 SDARS_RDISP_WORD_Rx 1;
BA_ "U_V713N_MY2022_Rx" SG_ 713 SDARS_RDISP_WORD_Rx 1;
BA_ "U_P708_MY2023_Rx" SG_ 382 EngMnfldChrg_Te_Actl 1;
BA_ "GenSigStartValue" SG_ 382 EngMnfldChrg_Te_Actl 126;
BA_ "GenSigStartValue" SG_ 382 EngInnrClnt_Te_Actl 126;
BA_ "GenSigStartValue" SG_ 877 CabnAmb_Te_ActlAft 255;
BA_ "GenSigStartValue" SG_ 877 Rr_Third_Power_Btn_Stt 2;
BA_ "GenSigStartValue" SG_ 877 Rr_Third_Floor_Btn_Stt 2;
BA_ "GenSigStartValue" SG_ 877 Rr_Third_Auto_Btn_Stt 2;
BA_ "GenSigStartValue" SG_ 877 Rr_Lock_Btn_Stt 2;
BA_ "GenSigStartValue" SG_ 877 Rr_RHS_Blower_Indicate 15;
BA_ "GenSigStartValue" SG_ 877 Rr_Third_Panel_Btn_Stt 2;
BA_ "GenSigStartValue" SG_ 877 Rr_Synch_Btn_Stt 2;
BA_ "GenSigStartValue" SG_ 877 AAR_Btn_Stt 2;
BA_ "GenSigStartValue" SG_ 877 Heat_Btn_Stt 2;
BA_ "U_V710_MY2023_Tx" SG_ 708 TMCSrvr_TMCClnt_WORD_Tx 1;
BA_ "U_P708_MY2023_Tx" SG_ 708 TMCSrvr_TMCClnt_WORD_Tx 1;
BA_ "U_V713AV_MY2022_Tx" SG_ 708 TMCSrvr_TMCClnt_WORD_Tx 1;
BA_ "U_V713N_MY2022_Tx" SG_ 708 TMCSrvr_TMCClnt_WORD_Tx 1;
BA_ "U_V710_MY2023_Tx" SG_ 414 LBS2_ListStatus 1;
BA_ "U_P708_MY2023_Tx" SG_ 414 LBS2_ListStatus 1;
BA_ "U_V713AV_MY2022_Tx" SG_ 414 LBS2_ListStatus 1;
BA_ "U_V713N_MY2022_Tx" SG_ 414 LBS2_ListStatus 1;
BA_ "U_V713AV_MY2022_Rx" SG_ 414 LBS2_ListStatus 1;
BA_ "U_V713N_MY2022_Rx" SG_ 414 LBS2_ListStatus 1;
BA_ "GenSigSendType" SG_ 414 LBS2_ListStatus 3;
BA_ "U_V710_MY2023_Tx" SG_ 414 LBS2_ParentID 1;
BA_ "U_P708_MY2023_Tx" SG_ 414 LBS2_ParentID 1;
BA_ "U_V713AV_MY2022_Tx" SG_ 414 LBS2_ParentID 1;
BA_ "U_V713N_MY2022_Tx" SG_ 414 LBS2_ParentID 1;
BA_ "U_V713AV_MY2022_Rx" SG_ 414 LBS2_ParentID 1;
BA_ "U_V713N_MY2022_Rx" SG_ 414 LBS2_ParentID 1;
BA_ "U_V710_MY2023_Tx" SG_ 414 LBS2_ListServer 1;
BA_ "U_P708_MY2023_Tx" SG_ 414 LBS2_ListServer 1;
BA_ "U_V713AV_MY2022_Tx" SG_ 414 LBS2_ListServer 1;
BA_ "U_V713N_MY2022_Tx" SG_ 414 LBS2_ListServer 1;
BA_ "U_V713AV_MY2022_Rx" SG_ 414 LBS2_ListServer 1;
BA_ "U_V713N_MY2022_Rx" SG_ 414 LBS2_ListServer 1;
BA_ "U_V710_MY2023_Tx" SG_ 414 LBS2_ListID 1;
BA_ "U_P708_MY2023_Tx" SG_ 414 LBS2_ListID 1;
BA_ "U_V713AV_MY2022_Tx" SG_ 414 LBS2_ListID 1;
BA_ "U_V713N_MY2022_Tx" SG_ 414 LBS2_ListID 1;
BA_ "U_V713AV_MY2022_Rx" SG_ 414 LBS2_ListID 1;
BA_ "U_V713N_MY2022_Rx" SG_ 414 LBS2_ListID 1;
BA_ "U_V710_MY2023_Tx" SG_ 414 LBS2_EntryIndex 1;
BA_ "U_P708_MY2023_Tx" SG_ 414 LBS2_EntryIndex 1;
BA_ "U_V713AV_MY2022_Tx" SG_ 414 LBS2_EntryIndex 1;
BA_ "U_V713N_MY2022_Tx" SG_ 414 LBS2_EntryIndex 1;
BA_ "U_V713AV_MY2022_Rx" SG_ 414 LBS2_EntryIndex 1;
BA_ "U_V713N_MY2022_Rx" SG_ 414 LBS2_EntryIndex 1;
BA_ "WakeupSignal" SG_ 619 PaakCtlActv_D_Rq 1;
BA_ "MetaData" SG_ 953 KeyMyKeyTot_No2_Cnt 1;
BA_ "GenSigStartValue" SG_ 953 WakeAlarm3_D_Stat 3;
BA_ "U_V710_MY2023_Rx" SG_ 953 WakeAlarm2_D_Stat 1;
BA_ "U_P708_MY2023_Rx" SG_ 953 WakeAlarm2_D_Stat 1;
BA_ "GenSigStartValue" SG_ 953 WakeAlarm2_D_Stat 3;
BA_ "GenSigStartValue" SG_ 953 WakeAlarm1_D_Stat 3;
BA_ "GenSigStartValue" SG_ 953 WakeAlarm0_D_Stat 3;
BA_ "GenSigStartValue" SG_ 953 BattRgenLoSoc_Pc_LimLo 30;
BA_ "ContentDependant" SG_ 985 LongCtrlEnblDRq_No_Cs 1;
BA_ "MetaData" SG_ 985 LongCtrlEnblDRq_No_Cs 1;
BA_ "ContentDependant" SG_ 985 LongCtrlEnblDRq_No_Cnt 1;
BA_ "MetaData" SG_ 985 LongCtrlEnblDRq_No_Cnt 1;
BA_ "U_V710_MY2023_Rx" SG_ 985 ClrExitAsst_D_Stat 1;
BA_ "U_V713N_MY2022_Rx" SG_ 985 ClrExitAsst_D_Stat 1;
BA_ "U_V710_MY2023_Rx" SG_ 985 ClrExitAsstMsgTxt_D_Rq 1;
BA_ "U_P708_MY2023_Rx" SG_ 985 ClrExitAsstMsgTxt_D_Rq 1;
BA_ "U_V713N_MY2022_Rx" SG_ 985 ClrExitAsstMsgTxt_D_Rq 1;
BA_ "U_V710_MY2023_Rx" SG_ 985 ClrExitAsstChime_D_Rq 1;
BA_ "U_P708_MY2023_Rx" SG_ 985 ClrExitAsstChime_D_Rq 1;
BA_ "U_V713N_MY2022_Rx" SG_ 985 ClrExitAsstChime_D_Rq 1;
BA_ "U_V710_MY2023_Rx" SG_ 985 LcwaMsgTxt_D_Stat 1;
BA_ "U_P708_MY2023_Rx" SG_ 985 LcwaMsgTxt_D_Stat 1;
BA_ "U_V713N_MY2022_Rx" SG_ 985 LcwaMsgTxt_D_Stat 1;
BA_ "GenSigStartValue" SG_ 985 IsaVLim_D_Rq 254;
BA_ "GenSigStartValue" SG_ 985 IaccVLimUnit_D_Rq 3;
BA_ "GenSigStartValue" SG_ 985 IaccVLim_D_Rq 254;
BA_ "U_P708_MY2023_Rx" SG_ 985 TsrRegionTxt_D_Stat 1;
BA_ "U_V713N_MY2022_Rx" SG_ 985 TsrRegionTxt_D_Stat 1;
BA_ "U_P708_MY2023_Rx" SG_ 985 LdwChime_B_Rq 1;
BA_ "U_V713N_MY2022_Rx" SG_ 985 LdwChime_B_Rq 1;
BA_ "GenSigStartValue" SG_ 770 ScMnSoc_Pc_Actl 100;
BA_ "GenSigStartValue" SG_ 770 CurntTrgtSoc_Pc_Rq 100;
BA_ "U_P708_MY2023_Rx" SG_ 770 FstChrgBulk_T_Est 1;
BA_ "U_P708_MY2023_Rx" SG_ 770 CurntTrgtSoc_Pc_Dsply 1;
BA_ "GenSigStartValue" SG_ 770 CurntTrgtSoc_Pc_Dsply 100;
BA_ "U_V710_MY2023_Rx" SG_ 716 TMCSrvr_TMCClnt_WORD_Rx 1;
BA_ "U_P708_MY2023_Rx" SG_ 716 TMCSrvr_TMCClnt_WORD_Rx 1;
BA_ "U_V713AV_MY2022_Rx" SG_ 716 TMCSrvr_TMCClnt_WORD_Rx 1;
BA_ "U_V713N_MY2022_Rx" SG_ 716 TMCSrvr_TMCClnt_WORD_Rx 1;
BA_ "MetaData" SG_ 1013 ChrgProgIdSaved_D_Stat 1;
BA_ "U_V710_MY2023_Rx" SG_ 1013 ChrgLocIdCurnt_D_Sav 1;
BA_ "U_V713AV_MY2022_Rx" SG_ 1013 ChrgLocIdCurnt_D_Sav 1;
BA_ "U_V713N_MY2022_Rx" SG_ 1013 ChrgLocIdCurnt_D_Sav 1;
BA_ "MetaData" SG_ 1013 ChrgLocIdCurnt_D_Sav 1;
BA_ "GenSigStartValue" SG_ 1012 ChrgLocLongFrct_An_Sav 1048575;
BA_ "GenSigStartValue" SG_ 1012 ChrgLocLattFrct_An_Sav 1048575;
BA_ "U_V710_MY2023_Rx" SG_ 1012 ChrgNowCurnt_B_Dsply 1;
BA_ "U_V713AV_MY2022_Rx" SG_ 1012 ChrgNowCurnt_B_Dsply 1;
BA_ "U_V713N_MY2022_Rx" SG_ 1012 ChrgNowCurnt_B_Dsply 1;
BA_ "GenSigStartValue" SG_ 1011 ChrgLocLongFrct_An_Uns 1048575;
BA_ "GenSigStartValue" SG_ 1011 ChrgLocLattFrct_An_Uns 1048575;
BA_ "U_V710_MY2023_Rx" SG_ 1011 VehShutDownMsgTxt_D_Rq 1;
BA_ "U_P708_MY2023_Rx" SG_ 1011 VehShutDownMsgTxt_D_Rq 1;
BA_ "GenSigSendType" SG_ 533 ClrExitAsstEnbl_D_RqMnu 3;
BA_ "GenSigSendType" SG_ 533 AutoEpbZoomView_B_Stat 3;
BA_ "GenSigSendType" SG_ 533 PaakMyKey_D_Rq 3;
BA_ "GenSigSendType" SG_ 533 DcacPw_D_Rq 3;
BA_ "GenSigSendType" SG_ 533 DcacPwReset_B_Rq 3;
BA_ "GenSigSendType" SG_ 533 AutoEpbButtn_B_Stat 3;
BA_ "GenSigSendType" SG_ 533 TrlrAidMde_D_Rq 3;
BA_ "GenSigSendType" SG_ 533 TCU_Init_Actvtn_St 3;
BA_ "GenSigSendType" SG_ 533 TCU_Final_Actvtn_St 3;
BA_ "GenSigSendType" SG_ 533 LghtAmbDrvMde_D_Rq 3;
BA_ "WakeupSignal" SG_ 533 LghtAmbDrvMde_D_Rq 1;
BA_ "GenSigSendType" SG_ 533 OtaTrg_D_Stat 3;
BA_ "GenSigSendType" SG_ 533 DcacPwLoButtn_B_Stat 3;
BA_ "GenSigSendType" SG_ 533 DcacPwOffButtn_B_Stat 3;
BA_ "GenSigSendType" SG_ 533 DcacPwHiButtn_B_Stat 3;
BA_ "GenSigSendType" SG_ 533 DcacPwResetButtn_B_Stat 3;
BA_ "GenSigSendType" SG_ 533 DcacPwButtn_B_Falt 3;
BA_ "GenSigSendType" SG_ 533 DcacMdeButtn_B_Stat 3;
BA_ "GenSigSendType" SG_ 533 OnbChrgGoTTouch_D_Rq 3;
BA_ "GenSigSendType" SG_ 533 OnbChrgGoTPrcond_D_Rq 3;
BA_ "GenSigSendType" SG_ 533 OnbChrgGoTOn_D_Rq 3;
BA_ "GenSigStartValue" SG_ 533 OnbChrgGoTOn_D_Rq 2;
BA_ "MetaData" SG_ 533 OnbChrgGoTMnte_D_Rq 1;
BA_ "GenSigStartValue" SG_ 533 OnbChrgGoTHr_T_Rq 30;
BA_ "GenSigSendType" SG_ 533 OnbChrgGoTExtHtr_D_Rq 3;
BA_ "GenSigSendType" SG_ 533 OnbChrgGoTElement_D_Rq 3;
BA_ "MetaData" SG_ 533 OnbChrgGoTElement_D_Rq 1;
BA_ "GenSigSendType" SG_ 533 OnbChrgGoTDelete_B_Rq 3;
BA_ "GenSigSendType" SG_ 533 OnbChrgClearAll_B_Rq 3;
BA_ "GenSigSendType" SG_ 533 DcacGfciTestBttn_B_Stat 3;
BA_ "U_P708_MY2023_Rx" SG_ 533 OnbChrgGoTUpdate_B_Rq 1;
BA_ "U_V713AV_MY2022_Rx" SG_ 533 OnbChrgGoTUpdate_B_Rq 1;
BA_ "U_V713N_MY2022_Rx" SG_ 533 OnbChrgGoTUpdate_B_Rq 1;
BA_ "ECGUsedRxSignal" SG_ 533 OnbChrgGoTUpdate_B_Rq 1;
BA_ "GenSigSendType" SG_ 533 OnbChrgGoTUpdate_B_Rq 3;
BA_ "U_V710_MY2023_Rx" SG_ 533 TrlrAlarmButtn_B_Stat 1;
BA_ "U_P708_MY2023_Rx" SG_ 533 TrlrAlarmButtn_B_Stat 1;
BA_ "GenSigSendType" SG_ 533 TrlrAlarmButtn_B_Stat 3;
BA_ "GenSigSendType" SG_ 533 DcacPwButtn_B_Stat 3;
BA_ "U_V710_MY2023_Rx" SG_ 533 TrlrBrkGain_No_Rq 1;
BA_ "U_P708_MY2023_Rx" SG_ 533 TrlrBrkGain_No_Rq 1;
BA_ "GenSigSendType" SG_ 533 TrlrBrkGain_No_Rq 3;
BA_ "GenSigSendType" SG_ 533 TrlrHitch_D_RqMnu 3;
BA_ "U_P708_MY2023_Tx" SG_ 801 CDWarnChime_St 1;
BA_ "U_V713AV_MY2022_Tx" SG_ 801 CDWarnChime_St 1;
BA_ "U_V713N_MY2022_Tx" SG_ 801 CDWarnChime_St 1;
BA_ "U_V713AV_MY2022_Rx" SG_ 801 CDWarnChime_St 1;
BA_ "U_V713N_MY2022_Rx" SG_ 801 CDWarnChime_St 1;
BA_ "GenSigSendType" SG_ 801 CDWarnChime_St 3;
BA_ "U_P708_MY2023_Tx" SG_ 801 DrvDsplyPalette_D_Stat 1;
BA_ "U_V713AV_MY2022_Tx" SG_ 801 DrvDsplyPalette_D_Stat 1;
BA_ "U_V713N_MY2022_Tx" SG_ 801 DrvDsplyPalette_D_Stat 1;
BA_ "U_P708_MY2023_Tx" SG_ 801 SoftWarning 1;
BA_ "U_V713AV_MY2022_Tx" SG_ 801 SoftWarning 1;
BA_ "U_V713N_MY2022_Tx" SG_ 801 SoftWarning 1;
BA_ "GenSigSendType" SG_ 801 SoftWarning 3;
BA_ "U_P708_MY2023_Tx" SG_ 801 HardWarning 1;
BA_ "U_V713AV_MY2022_Tx" SG_ 801 HardWarning 1;
BA_ "U_V713N_MY2022_Tx" SG_ 801 HardWarning 1;
BA_ "GenSigSendType" SG_ 801 HardWarning 3;
BA_ "U_P708_MY2023_Tx" SG_ 801 InfoWarning 1;
BA_ "U_V713AV_MY2022_Tx" SG_ 801 InfoWarning 1;
BA_ "U_V713N_MY2022_Tx" SG_ 801 InfoWarning 1;
BA_ "GenSigSendType" SG_ 801 InfoWarning 3;
BA_ "GenSigSendType" SG_ 878 ClimtSyncRear2_B_Stat 3;
BA_ "GenSigSendType" SG_ 878 ClimtStHeatRr2_B_Stat 3;
BA_ "GenSigSendType" SG_ 878 ClimtStHeatRl2_B_Stat 3;
BA_ "GenSigSendType" SG_ 878 ClimtStCoolRr2_B_Stat 3;
BA_ "GenSigSendType" SG_ 878 ClimtStCoolRl2_B_Stat 3;
BA_ "GenSigSendType" SG_ 878 ClimtSeatRr2_D_Rq 3;
BA_ "GenSigSendType" SG_ 878 ClimtSeatRl2_D_Rq 3;
BA_ "GenSigSendType" SG_ 878 ClimtRrTe3rd2_D_Stat 3;
BA_ "GenSigSendType" SG_ 878 ClimtRrPw3rd2_B_Stat 3;
BA_ "GenSigSendType" SG_ 878 ClimtRrPnl3rd2_B_Stat 3;
BA_ "GenSigSendType" SG_ 878 ClimtRrPf3rd2_B_Stat 3;
BA_ "GenSigSendType" SG_ 878 ClimtRrFlr3rd2_B_Stat 3;
BA_ "GenSigSendType" SG_ 878 ClimtRrBlwr3rd2_D_Stat 3;
BA_ "GenSigSendType" SG_ 878 ClimtRrAuto3rd2_B_Stat 3;
BA_ "GenSigSendType" SG_ 878 ClimtRearView2_D_Stat 3;
BA_ "GenSigSendType" SG_ 878 ClimtRearTe2_D_Stat 3;
BA_ "GenSigSendType" SG_ 878 ClimtRearTe2_An_Actl 3;
BA_ "GenSigStartValue" SG_ 878 ClimtRearTe2_An_Actl 511;
BA_ "GenSigSendType" SG_ 878 ClimtRearPw2_B_Stat 3;
BA_ "GenSigSendType" SG_ 878 ClimtRearPnlFlr2_B_Stat 3;
BA_ "GenSigSendType" SG_ 878 ClimtRearPnl2_B_Stat 3;
BA_ "GenSigSendType" SG_ 878 ClimtRearFlr2_B_Stat 3;
BA_ "GenSigSendType" SG_ 878 ClimtRearBlwr2_D_Stat 3;
BA_ "GenSigSendType" SG_ 878 ClimtRearBlwr2_An_Actl 3;
BA_ "GenSigStartValue" SG_ 878 ClimtRearBlwr2_An_Actl 511;
BA_ "GenSigSendType" SG_ 878 ClimtRearAuto2_B_Stat 3;
BA_ "U_V710_MY2023_Rx" SG_ 259 SDARS_CurrCATlstSize_Rq 1;
BA_ "U_P708_MY2023_Rx" SG_ 259 SDARS_CurrCATlstSize_Rq 1;
BA_ "U_V713AV_MY2022_Rx" SG_ 259 SDARS_CurrCATlstSize_Rq 1;
BA_ "U_V713N_MY2022_Rx" SG_ 259 SDARS_CurrCATlstSize_Rq 1;
BA_ "U_V710_MY2023_Rx" SG_ 259 SDARS_CurrCATlistInd_Rq 1;
BA_ "U_P708_MY2023_Rx" SG_ 259 SDARS_CurrCATlistInd_Rq 1;
BA_ "U_V713AV_MY2022_Rx" SG_ 259 SDARS_CurrCATlistInd_Rq 1;
BA_ "U_V713N_MY2022_Rx" SG_ 259 SDARS_CurrCATlistInd_Rq 1;
BA_ "GenSigSendType" SG_ 259 SDARS_CurrCATlistInd_Rq 3;
BA_ "U_V710_MY2023_Rx" SG_ 259 SDARS_ChipControl_Rq 1;
BA_ "U_P708_MY2023_Rx" SG_ 259 SDARS_ChipControl_Rq 1;
BA_ "U_V713AV_MY2022_Rx" SG_ 259 SDARS_ChipControl_Rq 1;
BA_ "U_V713N_MY2022_Rx" SG_ 259 SDARS_ChipControl_Rq 1;
BA_ "GenSigSendType" SG_ 259 SDARS_ChipControl_Rq 3;
BA_ "U_V710_MY2023_Rx" SG_ 259 SDARS_AlertStatus_Rq 1;
BA_ "U_P708_MY2023_Rx" SG_ 259 SDARS_AlertStatus_Rq 1;
BA_ "U_V713AV_MY2022_Rx" SG_ 259 SDARS_AlertStatus_Rq 1;
BA_ "U_V713N_MY2022_Rx" SG_ 259 SDARS_AlertStatus_Rq 1;
BA_ "GenSigSendType" SG_ 259 SDARS_AlertStatus_Rq 3;
BA_ "U_V710_MY2023_Tx" SG_ 538 MK_UserMyKeyCount_St 1;
BA_ "U_P708_MY2023_Tx" SG_ 538 MK_UserMyKeyCount_St 1;
BA_ "U_V713AV_MY2022_Tx" SG_ 538 MK_UserMyKeyCount_St 1;
BA_ "U_V713N_MY2022_Tx" SG_ 538 MK_UserMyKeyCount_St 1;
BA_ "GenSigSendType" SG_ 538 MK_UserMyKeyCount_St 3;
BA_ "U_V710_MY2023_Tx" SG_ 538 MK_SpeedMinderConf_St 1;
BA_ "U_P708_MY2023_Tx" SG_ 538 MK_SpeedMinderConf_St 1;
BA_ "U_V713AV_MY2022_Tx" SG_ 538 MK_SpeedMinderConf_St 1;
BA_ "U_V713N_MY2022_Tx" SG_ 538 MK_SpeedMinderConf_St 1;
BA_ "GenSigSendType" SG_ 538 MK_SpeedMinderConf_St 3;
BA_ "U_V710_MY2023_Tx" SG_ 538 MK_SpeedLimitConf_St 1;
BA_ "U_P708_MY2023_Tx" SG_ 538 MK_SpeedLimitConf_St 1;
BA_ "U_V713AV_MY2022_Tx" SG_ 538 MK_SpeedLimitConf_St 1;
BA_ "U_V713N_MY2022_Tx" SG_ 538 MK_SpeedLimitConf_St 1;
BA_ "GenSigSendType" SG_ 538 MK_SpeedLimitConf_St 3;
BA_ "U_V710_MY2023_Tx" SG_ 538 MK_ESCRestrictConf_St 1;
BA_ "U_P708_MY2023_Tx" SG_ 538 MK_ESCRestrictConf_St 1;
BA_ "U_V713AV_MY2022_Tx" SG_ 538 MK_ESCRestrictConf_St 1;
BA_ "U_V713N_MY2022_Tx" SG_ 538 MK_ESCRestrictConf_St 1;
BA_ "GenSigSendType" SG_ 538 MK_ESCRestrictConf_St 3;
BA_ "U_V710_MY2023_Tx" SG_ 538 MK_ECalRestrictConf_St 1;
BA_ "U_P708_MY2023_Tx" SG_ 538 MK_ECalRestrictConf_St 1;
BA_ "U_V713AV_MY2022_Tx" SG_ 538 MK_ECalRestrictConf_St 1;
BA_ "U_V713N_MY2022_Tx" SG_ 538 MK_ECalRestrictConf_St 1;
BA_ "GenSigSendType" SG_ 538 MK_ECalRestrictConf_St 3;
BA_ "U_V710_MY2023_Tx" SG_ 538 MK_DNDRestrictConf_St 1;
BA_ "U_P708_MY2023_Tx" SG_ 538 MK_DNDRestrictConf_St 1;
BA_ "U_V713AV_MY2022_Tx" SG_ 538 MK_DNDRestrictConf_St 1;
BA_ "U_V713N_MY2022_Tx" SG_ 538 MK_DNDRestrictConf_St 1;
BA_ "GenSigSendType" SG_ 538 MK_DNDRestrictConf_St 3;
BA_ "U_V710_MY2023_Tx" SG_ 538 MK_AudioLimitConfig_St 1;
BA_ "U_P708_MY2023_Tx" SG_ 538 MK_AudioLimitConfig_St 1;
BA_ "U_V713AV_MY2022_Tx" SG_ 538 MK_AudioLimitConfig_St 1;
BA_ "U_V713N_MY2022_Tx" SG_ 538 MK_AudioLimitConfig_St 1;
BA_ "GenSigSendType" SG_ 538 MK_AudioLimitConfig_St 3;
BA_ "U_V710_MY2023_Tx" SG_ 538 MK_AdminMyKeyCount_St 1;
BA_ "U_P708_MY2023_Tx" SG_ 538 MK_AdminMyKeyCount_St 1;
BA_ "U_V713AV_MY2022_Tx" SG_ 538 MK_AdminMyKeyCount_St 1;
BA_ "U_V713N_MY2022_Tx" SG_ 538 MK_AdminMyKeyCount_St 1;
BA_ "GenSigSendType" SG_ 538 MK_AdminMyKeyCount_St 3;
BA_ "U_V710_MY2023_Tx" SG_ 422 MK_UserMyKeyCount_Rsp 1;
BA_ "U_P708_MY2023_Tx" SG_ 422 MK_UserMyKeyCount_Rsp 1;
BA_ "U_V713AV_MY2022_Tx" SG_ 422 MK_UserMyKeyCount_Rsp 1;
BA_ "U_V713N_MY2022_Tx" SG_ 422 MK_UserMyKeyCount_Rsp 1;
BA_ "GenSigSendType" SG_ 422 MK_UserMyKeyCount_Rsp 3;
BA_ "U_V710_MY2023_Tx" SG_ 422 MK_MyKeyDrivenKm_Rsp 1;
BA_ "U_P708_MY2023_Tx" SG_ 422 MK_MyKeyDrivenKm_Rsp 1;
BA_ "U_V713AV_MY2022_Tx" SG_ 422 MK_MyKeyDrivenKm_Rsp 1;
BA_ "U_V713N_MY2022_Tx" SG_ 422 MK_MyKeyDrivenKm_Rsp 1;
BA_ "GenSigSendType" SG_ 422 MK_MyKeyDrivenKm_Rsp 3;
BA_ "U_V710_MY2023_Tx" SG_ 422 MK_CreateMyKey_Rsp 1;
BA_ "U_V713AV_MY2022_Tx" SG_ 422 MK_CreateMyKey_Rsp 1;
BA_ "U_V713N_MY2022_Tx" SG_ 422 MK_CreateMyKey_Rsp 1;
BA_ "GenSigSendType" SG_ 422 MK_CreateMyKey_Rsp 3;
BA_ "U_V710_MY2023_Tx" SG_ 422 MK_AdminMyKeyCount_Rsp 1;
BA_ "U_P708_MY2023_Tx" SG_ 422 MK_AdminMyKeyCount_Rsp 1;
BA_ "U_V713AV_MY2022_Tx" SG_ 422 MK_AdminMyKeyCount_Rsp 1;
BA_ "U_V713N_MY2022_Tx" SG_ 422 MK_AdminMyKeyCount_Rsp 1;
BA_ "GenSigSendType" SG_ 422 MK_AdminMyKeyCount_Rsp 3;
BA_ "U_V710_MY2023_Rx" SG_ 1041 ElCmpr_N_Actl 1;
BA_ "U_P708_MY2023_Rx" SG_ 1041 ElCmpr_N_Actl 1;
BA_ "U_V713N_MY2022_Rx" SG_ 1041 ElCmpr_N_Actl 1;
BA_ "U_V710_MY2023_Tx" SG_ 890 ActvNseMute_D_Rq 1;
BA_ "U_P708_MY2023_Tx" SG_ 890 ActvNseMute_D_Rq 1;
BA_ "GenSigSendType" SG_ 890 ActvNseMute_D_Rq 3;
BA_ "U_V710_MY2023_Tx" SG_ 890 ActvNseAudio_D_Stat 1;
BA_ "U_P708_MY2023_Tx" SG_ 890 ActvNseAudio_D_Stat 1;
BA_ "U_V713AV_MY2022_Tx" SG_ 890 ActvNseAudio_D_Stat 1;
BA_ "U_V713N_MY2022_Tx" SG_ 890 ActvNseAudio_D_Stat 1;
BA_ "GenSigSendType" SG_ 890 ActvNseAudio_D_Stat 3;
BA_ "U_V710_MY2023_Tx" SG_ 890 ActvNse_B_Actv 1;
BA_ "U_P708_MY2023_Tx" SG_ 890 ActvNse_B_Actv 1;
BA_ "U_V713AV_MY2022_Tx" SG_ 890 ActvNse_B_Actv 1;
BA_ "U_V713N_MY2022_Tx" SG_ 890 ActvNse_B_Actv 1;
BA_ "GenSigSendType" SG_ 890 ActvNse_B_Actv 3;
BA_ "GenSigSendType" SG_ 2008 TesterPhysicalResAPIM 3;
BA_ "GenSigStartValue" SG_ 884 PmSnsCabn_D_Stat 5;
BA_ "GenSigStartValue" SG_ 884 PmCabn_Conc_Actl 510;
BA_ "GenSigStartValue" SG_ 884 PmCabn20Mnte_Conc_Actl 510;
BA_ "GenSigStartValue" SG_ 884 PmCabn18Mnte_Conc_Actl 510;
BA_ "GenSigStartValue" SG_ 884 PmCabn16Mnte_Conc_Actl 510;
BA_ "GenSigStartValue" SG_ 884 PmCabn14Mnte_Conc_Actl 510;
BA_ "GenSigStartValue" SG_ 884 PmCabn12Mnte_Conc_Actl 510;
BA_ "GenSigStartValue" SG_ 883 PmCabn10Mnte_Conc_Actl 510;
BA_ "GenSigStartValue" SG_ 883 PmCabn08Mnte_Conc_Actl 510;
BA_ "GenSigStartValue" SG_ 883 PmCabn06Mnte_Conc_Actl 510;
BA_ "GenSigStartValue" SG_ 883 PmCabn04Mnte_Conc_Actl 510;
BA_ "GenSigStartValue" SG_ 883 PmCabn02Mnte_Conc_Actl 510;
BA_ "U_P708_MY2023_Rx" SG_ 1090 VehElRnge_L_Dsply 1;
BA_ "U_V713AV_MY2022_Rx" SG_ 1090 VehElRnge_L_Dsply 1;
BA_ "U_V713N_MY2022_Rx" SG_ 1090 VehElRnge_L_Dsply 1;
BA_ "GenSigStartValue" SG_ 1090 VehElRnge_L_Dsply 4093;
BA_ "GenSigStartValue" SG_ 1090 Inv1Ain_I_ActlMntr 32765;
BA_ "U_V710_MY2023_Rx" SG_ 715 RDISP_SSP_WORD_Rx 1;
BA_ "U_P708_MY2023_Rx" SG_ 715 RDISP_SSP_WORD_Rx 1;
BA_ "U_V713AV_MY2022_Rx" SG_ 715 RDISP_SSP_WORD_Rx 1;
BA_ "U_V713N_MY2022_Rx" SG_ 715 RDISP_SSP_WORD_Rx 1;
BA_ "U_P708_MY2023_Rx" SG_ 473 NAV_StorePreset2_Rq 1;
BA_ "U_V713AV_MY2022_Rx" SG_ 473 NAV_StorePreset2_Rq 1;
BA_ "U_V713N_MY2022_Rx" SG_ 473 NAV_StorePreset2_Rq 1;
BA_ "GenSigSendType" SG_ 473 NAV_StorePreset2_Rq 3;
BA_ "U_V710_MY2023_Rx" SG_ 473 NAV_SetAFMode_Rq 1;
BA_ "U_P708_MY2023_Rx" SG_ 473 NAV_SetAFMode_Rq 1;
BA_ "U_V713AV_MY2022_Rx" SG_ 473 NAV_SetAFMode_Rq 1;
BA_ "U_V713N_MY2022_Rx" SG_ 473 NAV_SetAFMode_Rq 1;
BA_ "GenSigSendType" SG_ 473 NAV_SetAFMode_Rq 3;
BA_ "U_P708_MY2023_Rx" SG_ 473 NAV_StorePreset_Rq 1;
BA_ "U_V713AV_MY2022_Rx" SG_ 473 NAV_StorePreset_Rq 1;
BA_ "U_V713N_MY2022_Rx" SG_ 473 NAV_StorePreset_Rq 1;
BA_ "GenSigSendType" SG_ 473 NAV_StorePreset_Rq 3;
BA_ "U_V710_MY2023_Rx" SG_ 473 HMI_StorePreset2_Rq 1;
BA_ "U_P708_MY2023_Rx" SG_ 473 HMI_StorePreset2_Rq 1;
BA_ "U_V713AV_MY2022_Rx" SG_ 473 HMI_StorePreset2_Rq 1;
BA_ "U_V713N_MY2022_Rx" SG_ 473 HMI_StorePreset2_Rq 1;
BA_ "GenSigSendType" SG_ 473 HMI_StorePreset2_Rq 3;
BA_ "U_P708_MY2023_Rx" SG_ 473 NAV_SetTUServiceLink_Rq 1;
BA_ "U_V713AV_MY2022_Rx" SG_ 473 NAV_SetTUServiceLink_Rq 1;
BA_ "U_V713N_MY2022_Rx" SG_ 473 NAV_SetTUServiceLink_Rq 1;
BA_ "GenSigSendType" SG_ 473 NAV_SetTUServiceLink_Rq 3;
BA_ "U_V710_MY2023_Rx" SG_ 473 NAV_SetTAMode_Rq 1;
BA_ "U_P708_MY2023_Rx" SG_ 473 NAV_SetTAMode_Rq 1;
BA_ "U_V713AV_MY2022_Rx" SG_ 473 NAV_SetTAMode_Rq 1;
BA_ "U_V713N_MY2022_Rx" SG_ 473 NAV_SetTAMode_Rq 1;
BA_ "GenSigSendType" SG_ 473 NAV_SetTAMode_Rq 3;
BA_ "U_V710_MY2023_Rx" SG_ 473 NAV_SetReg_Rq 1;
BA_ "U_P708_MY2023_Rx" SG_ 473 NAV_SetReg_Rq 1;
BA_ "U_V713AV_MY2022_Rx" SG_ 473 NAV_SetReg_Rq 1;
BA_ "U_V713N_MY2022_Rx" SG_ 473 NAV_SetReg_Rq 1;
BA_ "GenSigSendType" SG_ 473 NAV_SetReg_Rq 3;
BA_ "U_V710_MY2023_Rx" SG_ 473 NAV_SelectPTYCodeSet_Rq 1;
BA_ "U_P708_MY2023_Rx" SG_ 473 NAV_SelectPTYCodeSet_Rq 1;
BA_ "U_V713AV_MY2022_Rx" SG_ 473 NAV_SelectPTYCodeSet_Rq 1;
BA_ "U_V713N_MY2022_Rx" SG_ 473 NAV_SelectPTYCodeSet_Rq 1;
BA_ "GenSigSendType" SG_ 473 NAV_SelectPTYCodeSet_Rq 3;
BA_ "U_V710_MY2023_Rx" SG_ 473 NAV_SelectPTYCodes_Rq 1;
BA_ "U_P708_MY2023_Rx" SG_ 473 NAV_SelectPTYCodes_Rq 1;
BA_ "U_V713AV_MY2022_Rx" SG_ 473 NAV_SelectPTYCodes_Rq 1;
BA_ "U_V713N_MY2022_Rx" SG_ 473 NAV_SelectPTYCodes_Rq 1;
BA_ "U_V710_MY2023_Rx" SG_ 473 NAV_CDSetShuffle_Rq 1;
BA_ "U_V713AV_MY2022_Rx" SG_ 473 NAV_CDSetShuffle_Rq 1;
BA_ "U_V713N_MY2022_Rx" SG_ 473 NAV_CDSetShuffle_Rq 1;
BA_ "GenSigSendType" SG_ 473 NAV_CDSetShuffle_Rq 3;
BA_ "U_V710_MY2023_Rx" SG_ 473 NAV_CDSetRepeat_Rq 1;
BA_ "U_V713AV_MY2022_Rx" SG_ 473 NAV_CDSetRepeat_Rq 1;
BA_ "U_V713N_MY2022_Rx" SG_ 473 NAV_CDSetRepeat_Rq 1;
BA_ "GenSigSendType" SG_ 473 NAV_CDSetRepeat_Rq 3;
BA_ "U_V710_MY2023_Rx" SG_ 473 NAV_CDSetIntroScan_Rq 1;
BA_ "U_V713AV_MY2022_Rx" SG_ 473 NAV_CDSetIntroScan_Rq 1;
BA_ "U_V713N_MY2022_Rx" SG_ 473 NAV_CDSetIntroScan_Rq 1;
BA_ "GenSigSendType" SG_ 473 NAV_CDSetIntroScan_Rq 3;
BA_ "GenSigSendType" SG_ 2000 TesterPhysicalReqAPIM 3;
BA_ "GenSigStartValue" SG_ 90 DrQltyDrv_D_StatGsm 6;
BA_ "U_V710_MY2023_Rx" SG_ 90 GsmGearMsgTxt_D_Rq 1;
BA_ "U_P708_MY2023_Rx" SG_ 90 GsmGearMsgTxt_D_Rq 1;
BA_ "U_V713AV_MY2022_Rx" SG_ 90 GsmGearMsgTxt_D_Rq 1;
BA_ "U_V713N_MY2022_Rx" SG_ 90 GsmGearMsgTxt_D_Rq 1;
BA_ "GenSigStartValue" SG_ 90 TrnRng_D_RqGsm 14;
BA_ "WakeupSignal" SG_ 90 TrnGearButtn_U_Actl 1;
BA_ "WakeupSignal" SG_ 90 TrnGearButtn_B_ActlR2 1;
BA_ "WakeupSignal" SG_ 90 TrnGearButtn_B_ActlR1 1;
BA_ "WakeupSignal" SG_ 90 TrnGearButtn_B_ActlR0 1;
BA_ "WakeupSignal" SG_ 90 TrnGearButtn_B_ActlP2 1;
BA_ "WakeupSignal" SG_ 90 TrnGearButtn_B_ActlP1 1;
BA_ "WakeupSignal" SG_ 90 TrnGearButtn_B_ActlP0 1;
BA_ "WakeupSignal" SG_ 90 TrnGearButtn_B_ActlN2 1;
BA_ "WakeupSignal" SG_ 90 TrnGearButtn_B_ActlN1 1;
BA_ "WakeupSignal" SG_ 90 TrnGearButtn_B_ActlN0 1;
BA_ "WakeupSignal" SG_ 90 TrnGearButtn_B_ActlM2 1;
BA_ "WakeupSignal" SG_ 90 TrnGearButtn_B_ActlM1 1;
BA_ "WakeupSignal" SG_ 90 TrnGearButtn_B_ActlM0 1;
BA_ "WakeupSignal" SG_ 90 TrnGearButtn_B_ActlD2 1;
BA_ "WakeupSignal" SG_ 90 TrnGearButtn_B_ActlD1 1;
BA_ "WakeupSignal" SG_ 90 TrnGearButtn_B_ActlD0 1;
BA_ "MetaData" SG_ 90 TrnGear_No_Cs 1;
BA_ "MetaData" SG_ 90 TrnGear_No_Cnt 1;
BA_ "WakeupSignal" SG_ 90 TrnGear_D_RqDrv 1;
BA_ "U_P708_MY2023_Rx" SG_ 1021 TrlrTireSensIRR_D_Stat 1;
BA_ "U_P708_MY2023_Rx" SG_ 1021 TrlrTireSensIRM_D_Stat 1;
BA_ "U_P708_MY2023_Rx" SG_ 1021 TrlrTireIRR_P_Actl 1;
BA_ "GenSigStartValue" SG_ 1021 TrlrTireIRR_P_Actl 65533;
BA_ "U_P708_MY2023_Rx" SG_ 1021 TrlrTireIRM_P_Actl 1;
BA_ "GenSigStartValue" SG_ 1021 TrlrTireIRM_P_Actl 65533;
BA_ "U_P708_MY2023_Rx" SG_ 1021 TrlrTireIRF_P_Actl 1;
BA_ "GenSigStartValue" SG_ 1021 TrlrTireIRF_P_Actl 65533;
BA_ "ECGUsedTxSignal" SG_ 2611166424 PARSEDPhysGWM_ECGtoESPM 1;
BA_ "U_V713AV_MY2022_Rx" SG_ 2611166424 PARSEDPhysGWM_ECGtoESPM 1;
BA_ "GenSigSendType" SG_ 2611166424 PARSEDPhysGWM_ECGtoESPM 3;
BA_ "U_V713AV_MY2022_Rx" SG_ 482 SDARS_Firm_Update2_St 1;
BA_ "U_V713N_MY2022_Rx" SG_ 482 SDARS_Firm_Update2_St 1;
BA_ "GenSigSendType" SG_ 482 SDARS_Firm_Update2_St 3;
BA_ "U_V713AV_MY2022_Rx" SG_ 482 SDARS_UnSubscrb_Chan2_St 1;
BA_ "U_V713N_MY2022_Rx" SG_ 482 SDARS_UnSubscrb_Chan2_St 1;
BA_ "GenSigSendType" SG_ 482 SDARS_UnSubscrb_Chan2_St 3;
BA_ "U_V713AV_MY2022_Rx" SG_ 482 SDARS_UnSubscrb2_St 1;
BA_ "U_V713N_MY2022_Rx" SG_ 482 SDARS_UnSubscrb2_St 1;
BA_ "GenSigSendType" SG_ 482 SDARS_UnSubscrb2_St 3;
BA_ "U_V713AV_MY2022_Rx" SG_ 482 SDARS_Subscription2_St 1;
BA_ "U_V713N_MY2022_Rx" SG_ 482 SDARS_Subscription2_St 1;
BA_ "GenSigSendType" SG_ 482 SDARS_Subscription2_St 3;
BA_ "U_V713AV_MY2022_Rx" SG_ 482 SDARS_Seek_Scan2_St 1;
BA_ "U_V713N_MY2022_Rx" SG_ 482 SDARS_Seek_Scan2_St 1;
BA_ "GenSigSendType" SG_ 482 SDARS_Seek_Scan2_St 3;
BA_ "U_V713AV_MY2022_Rx" SG_ 482 SDARS_Receive_Err2_St 1;
BA_ "U_V713N_MY2022_Rx" SG_ 482 SDARS_Receive_Err2_St 1;
BA_ "GenSigSendType" SG_ 482 SDARS_Receive_Err2_St 3;
BA_ "U_V713AV_MY2022_Rx" SG_ 482 SDARS_Loss_Ant2_St 1;
BA_ "U_V713N_MY2022_Rx" SG_ 482 SDARS_Loss_Ant2_St 1;
BA_ "GenSigSendType" SG_ 482 SDARS_Loss_Ant2_St 3;
BA_ "U_V713AV_MY2022_Rx" SG_ 482 SDARS_Invalid_Chan2_St 1;
BA_ "U_V713N_MY2022_Rx" SG_ 482 SDARS_Invalid_Chan2_St 1;
BA_ "GenSigSendType" SG_ 482 SDARS_Invalid_Chan2_St 3;
BA_ "U_V713AV_MY2022_Rx" SG_ 482 SDARS_GCI_Update2_St 1;
BA_ "U_V713N_MY2022_Rx" SG_ 482 SDARS_GCI_Update2_St 1;
BA_ "GenSigSendType" SG_ 482 SDARS_GCI_Update2_St 3;
BA_ "U_V713AV_MY2022_Rx" SG_ 482 SDARS_Error_Conf2_St 1;
BA_ "U_V713N_MY2022_Rx" SG_ 482 SDARS_Error_Conf2_St 1;
BA_ "GenSigSendType" SG_ 482 SDARS_Error_Conf2_St 3;
BA_ "U_V713AV_MY2022_Rx" SG_ 482 SDARS_Antenna_Err2_St 1;
BA_ "U_V713N_MY2022_Rx" SG_ 482 SDARS_Antenna_Err2_St 1;
BA_ "GenSigSendType" SG_ 482 SDARS_Antenna_Err2_St 3;
BA_ "U_V710_MY2023_Rx" SG_ 764 SDARS_SID2_St 1;
BA_ "U_P708_MY2023_Rx" SG_ 764 SDARS_SID2_St 1;
BA_ "U_V713AV_MY2022_Rx" SG_ 764 SDARS_SID2_St 1;
BA_ "U_V713N_MY2022_Rx" SG_ 764 SDARS_SID2_St 1;
BA_ "GenSigSendType" SG_ 764 SDARS_SID2_St 3;
BA_ "U_V710_MY2023_Rx" SG_ 764 SdarsSampleRate_D_Stat 1;
BA_ "U_P708_MY2023_Rx" SG_ 764 SdarsSampleRate_D_Stat 1;
BA_ "U_V713AV_MY2022_Rx" SG_ 764 SdarsSampleRate_D_Stat 1;
BA_ "U_V713N_MY2022_Rx" SG_ 764 SdarsSampleRate_D_Stat 1;
BA_ "GenSigSendType" SG_ 764 SdarsSampleRate_D_Stat 3;
BA_ "U_V710_MY2023_Rx" SG_ 764 SdarsBaudRate_D_Stat 1;
BA_ "U_P708_MY2023_Rx" SG_ 764 SdarsBaudRate_D_Stat 1;
BA_ "U_V713AV_MY2022_Rx" SG_ 764 SdarsBaudRate_D_Stat 1;
BA_ "U_V713N_MY2022_Rx" SG_ 764 SdarsBaudRate_D_Stat 1;
BA_ "GenSigSendType" SG_ 764 SdarsBaudRate_D_Stat 3;
BA_ "U_V710_MY2023_Rx" SG_ 764 SDARS_CurrentChanNum2_St 1;
BA_ "U_V713AV_MY2022_Rx" SG_ 764 SDARS_CurrentChanNum2_St 1;
BA_ "U_V713N_MY2022_Rx" SG_ 764 SDARS_CurrentChanNum2_St 1;
BA_ "U_P708_MY2023_Rx" SG_ 764 SDARS_CurrentChanNum2_St 1;
BA_ "GenSigSendType" SG_ 764 SDARS_CurrentChanNum2_St 3;
BA_ "GenSigStartValue" SG_ 764 SDARS_CurrentChanNum2_St 1022;
BA_ "U_V710_MY2023_Rx" SG_ 764 SDARS_ChannelUpdate_St 1;
BA_ "U_P708_MY2023_Rx" SG_ 764 SDARS_ChannelUpdate_St 1;
BA_ "U_V713AV_MY2022_Rx" SG_ 764 SDARS_ChannelUpdate_St 1;
BA_ "U_V713N_MY2022_Rx" SG_ 764 SDARS_ChannelUpdate_St 1;
BA_ "GenSigSendType" SG_ 764 SDARS_ChannelUpdate_St 3;
BA_ "U_V710_MY2023_Rx" SG_ 764 SDARS_Channel_Lock2 1;
BA_ "U_P708_MY2023_Rx" SG_ 764 SDARS_Channel_Lock2 1;
BA_ "U_V713AV_MY2022_Rx" SG_ 764 SDARS_Channel_Lock2 1;
BA_ "U_V713N_MY2022_Rx" SG_ 764 SDARS_Channel_Lock2 1;
BA_ "GenSigSendType" SG_ 764 SDARS_Channel_Lock2 3;
BA_ "U_V710_MY2023_Rx" SG_ 1188 OPTIN_MC_WORD_Rx 1;
BA_ "ECGUsedRxSignal" SG_ 1188 OPTIN_MC_WORD_Rx 1;
BA_ "U_V713N_MY2022_Rx" SG_ 139 ActvFrontSteMsgTxt_D_Rq 1;
BA_ "GenSigStartValue" SG_ 837 VehCurb_M_Actl 1022;
BA_ "GenSigStartValue" SG_ 837 VehGvwr_M_Actl 1022;
BA_ "MetaData" SG_ 837 SuspVLimBRq_No_Cnt 1;
BA_ "MetaData" SG_ 837 SuspVLimBRq_No_Cs 1;
BA_ "U_P708_MY2023_Rx" SG_ 837 Ccd_B_Falt 1;
BA_ "U_V713N_MY2022_Rx" SG_ 837 Ccd_B_Falt 1;
BA_ "U_V713N_MY2022_Rx" SG_ 837 AirSusp_D_Stat 1;
BA_ "U_V713AV_MY2022_Rx" SG_ 837 AirSuspMsgTxt_D_Rq 1;
BA_ "U_V713N_MY2022_Rx" SG_ 837 AirSuspMsgTxt_D_Rq 1;
BA_ "U_P708_MY2023_Rx" SG_ 837 SuspDrvMde_D_Stat 1;
BA_ "U_V713N_MY2022_Rx" SG_ 837 SuspDrvMde_D_Stat 1;
BA_ "U_V713AV_MY2022_Rx" SG_ 837 CcdMsgTxt_D_RqDsply 1;
BA_ "U_P708_MY2023_Rx" SG_ 837 CcdMsgTxt_D_RqDsply 1;
BA_ "U_V713N_MY2022_Rx" SG_ 837 CcdMsgTxt_D_RqDsply 1;
BA_ "GenSigStartValue" SG_ 146 VehVert2_A_Actl 8190;
BA_ "MetaData" SG_ 146 VehLatLongVertA_No_Cs 1;
BA_ "MetaData" SG_ 146 VehLatLongVert_No_Cnt 1;
BA_ "U_P708_MY2023_Rx" SG_ 146 VehLong2_A_Actl 1;
BA_ "U_V713AV_MY2022_Rx" SG_ 146 VehLong2_A_Actl 1;
BA_ "U_V713N_MY2022_Rx" SG_ 146 VehLong2_A_Actl 1;
BA_ "GenSigStartValue" SG_ 146 VehLong2_A_Actl 8190;
BA_ "GenSigStartValue" SG_ 146 VehLat2_A_Actl 8190;
BA_ "GenSigStartValue" SG_ 146 VehVertAActl_D_Qf 1;
BA_ "MetaData" SG_ 146 VehVertAActl_D_Qf 1;
BA_ "GenSigStartValue" SG_ 146 VehLongAActl_D_Qf 1;
BA_ "MetaData" SG_ 146 VehLongAActl_D_Qf 1;
BA_ "GenSigStartValue" SG_ 146 VehLatAActl_D_Qf 1;
BA_ "MetaData" SG_ 146 VehLatAActl_D_Qf 1;
BA_ "U_V710_MY2023_Rx" SG_ 925 VehElEffTrip_No_Dsply 1;
BA_ "U_P708_MY2023_Rx" SG_ 925 VehElEffTrip_No_Dsply 1;
BA_ "GenSigStartValue" SG_ 925 VehElEffTrip_No_Dsply 126;
BA_ "U_P708_MY2023_Rx" SG_ 925 TripSumDrvE_Pc_Dsply 1;
BA_ "GenSigStartValue" SG_ 925 TripSumDrvE_Pc_Dsply 1022;
BA_ "U_P708_MY2023_Rx" SG_ 925 TripExtFctrE_Pc_Dsply 1;
BA_ "GenSigStartValue" SG_ 925 TripExtFctrE_Pc_Dsply 1022;
BA_ "U_P708_MY2023_Rx" SG_ 925 TripClimE_Pc_Dsply 1;
BA_ "GenSigStartValue" SG_ 925 TripClimE_Pc_Dsply 1022;
BA_ "U_P708_MY2023_Rx" SG_ 925 TripBattULoE_Pc_Dsply 1;
BA_ "GenSigStartValue" SG_ 925 TripBattULoE_Pc_Dsply 1022;
BA_ "U_V710_MY2023_Rx" SG_ 501 Dsp_PresetArea_Rq 1;
BA_ "U_P708_MY2023_Rx" SG_ 501 Dsp_PresetArea_Rq 1;
BA_ "U_V713AV_MY2022_Rx" SG_ 501 Dsp_PresetArea_Rq 1;
BA_ "U_V713N_MY2022_Rx" SG_ 501 Dsp_PresetArea_Rq 1;
BA_ "GenSigSendType" SG_ 501 Dsp_PresetArea_Rq 3;
BA_ "U_V710_MY2023_Rx" SG_ 501 Dsp_StartIndex2_Rq 1;
BA_ "U_P708_MY2023_Rx" SG_ 501 Dsp_StartIndex2_Rq 1;
BA_ "U_V713AV_MY2022_Rx" SG_ 501 Dsp_StartIndex2_Rq 1;
BA_ "U_V713N_MY2022_Rx" SG_ 501 Dsp_StartIndex2_Rq 1;
BA_ "U_V710_MY2023_Rx" SG_ 501 Dsp_SetRadSeekMode_Rq 1;
BA_ "U_P708_MY2023_Rx" SG_ 501 Dsp_SetRadSeekMode_Rq 1;
BA_ "U_V713AV_MY2022_Rx" SG_ 501 Dsp_SetRadSeekMode_Rq 1;
BA_ "U_V713N_MY2022_Rx" SG_ 501 Dsp_SetRadSeekMode_Rq 1;
BA_ "GenSigSendType" SG_ 501 Dsp_SetRadSeekMode_Rq 3;
BA_ "U_V710_MY2023_Rx" SG_ 501 Dsp_SetCurrPreset2_Rq 1;
BA_ "U_P708_MY2023_Rx" SG_ 501 Dsp_SetCurrPreset2_Rq 1;
BA_ "U_V713AV_MY2022_Rx" SG_ 501 Dsp_SetCurrPreset2_Rq 1;
BA_ "U_V713N_MY2022_Rx" SG_ 501 Dsp_SetCurrPreset2_Rq 1;
BA_ "GenSigSendType" SG_ 501 Dsp_SetCurrPreset2_Rq 3;
BA_ "U_V710_MY2023_Rx" SG_ 501 Dsp_SetCurrFMSLPr_Rq 1;
BA_ "U_P708_MY2023_Rx" SG_ 501 Dsp_SetCurrFMSLPr_Rq 1;
BA_ "U_V713AV_MY2022_Rx" SG_ 501 Dsp_SetCurrFMSLPr_Rq 1;
BA_ "U_V713N_MY2022_Rx" SG_ 501 Dsp_SetCurrFMSLPr_Rq 1;
BA_ "GenSigSendType" SG_ 501 Dsp_SetCurrFMSLPr_Rq 3;
BA_ "U_V710_MY2023_Rx" SG_ 501 Dsp_SetCRadioBand_Rq 1;
BA_ "U_P708_MY2023_Rx" SG_ 501 Dsp_SetCRadioBand_Rq 1;
BA_ "U_V713AV_MY2022_Rx" SG_ 501 Dsp_SetCRadioBand_Rq 1;
BA_ "U_V713N_MY2022_Rx" SG_ 501 Dsp_SetCRadioBand_Rq 1;
BA_ "GenSigSendType" SG_ 501 Dsp_SetCRadioBand_Rq 3;
BA_ "U_V710_MY2023_Rx" SG_ 501 Dsp_NbrOfPresets_Rq 1;
BA_ "U_P708_MY2023_Rx" SG_ 501 Dsp_NbrOfPresets_Rq 1;
BA_ "U_V713AV_MY2022_Rx" SG_ 501 Dsp_NbrOfPresets_Rq 1;
BA_ "U_V713N_MY2022_Rx" SG_ 501 Dsp_NbrOfPresets_Rq 1;
BA_ "U_V710_MY2023_Rx" SG_ 501 Dsp_FreezeFMSL_Rq 1;
BA_ "U_P708_MY2023_Rx" SG_ 501 Dsp_FreezeFMSL_Rq 1;
BA_ "U_V713AV_MY2022_Rx" SG_ 501 Dsp_FreezeFMSL_Rq 1;
BA_ "U_V713N_MY2022_Rx" SG_ 501 Dsp_FreezeFMSL_Rq 1;
BA_ "GenSigSendType" SG_ 501 Dsp_FreezeFMSL_Rq 3;
BA_ "U_V710_MY2023_Rx" SG_ 1506 APIM_GWOnBoardTester 1;
BA_ "U_P708_MY2023_Rx" SG_ 1506 APIM_GWOnBoardTester 1;
BA_ "GenSigStartValue" SG_ 1506 APIM_GWOnBoardTester 255;
BA_ "U_V710_MY2023_Rx" SG_ 1506 APIM_GWNMProxy 1;
BA_ "U_P708_MY2023_Rx" SG_ 1506 APIM_GWNMProxy 1;
BA_ "GenSigStartValue" SG_ 1506 APIM_GWNMProxy 255;
BA_ "U_V710_MY2023_Rx" SG_ 1506 APIM_AutoSarNMReserved4 1;
BA_ "U_P708_MY2023_Rx" SG_ 1506 APIM_AutoSarNMReserved4 1;
BA_ "GenSigStartValue" SG_ 1506 APIM_AutoSarNMReserved4 255;
BA_ "U_V710_MY2023_Rx" SG_ 1506 APIM_AutoSarNMReserved3 1;
BA_ "U_P708_MY2023_Rx" SG_ 1506 APIM_AutoSarNMReserved3 1;
BA_ "GenSigStartValue" SG_ 1506 APIM_AutoSarNMReserved3 255;
BA_ "U_V710_MY2023_Rx" SG_ 1506 APIM_AutoSarNMReserved2 1;
BA_ "U_P708_MY2023_Rx" SG_ 1506 APIM_AutoSarNMReserved2 1;
BA_ "GenSigStartValue" SG_ 1506 APIM_AutoSarNMReserved2 255;
BA_ "U_V710_MY2023_Rx" SG_ 1506 APIM_AutoSarNMReserved1 1;
BA_ "U_P708_MY2023_Rx" SG_ 1506 APIM_AutoSarNMReserved1 1;
BA_ "GenSigStartValue" SG_ 1506 APIM_AutoSarNMReserved1 255;
BA_ "U_V710_MY2023_Rx" SG_ 1506 APIM_AutoSarNMNodeId 1;
BA_ "U_P708_MY2023_Rx" SG_ 1506 APIM_AutoSarNMNodeId 1;
BA_ "GenSigStartValue" SG_ 1506 APIM_AutoSarNMNodeId 226;
BA_ "U_V710_MY2023_Rx" SG_ 1506 APIM_AutoSarNMControl 1;
BA_ "U_P708_MY2023_Rx" SG_ 1506 APIM_AutoSarNMControl 1;
BA_ "U_V710_MY2023_Rx" SG_ 651 TelematicsSrvc_D_St 1;
BA_ "U_P708_MY2023_Rx" SG_ 651 TelematicsSrvc_D_St 1;
BA_ "U_V713AV_MY2022_Rx" SG_ 651 TelematicsSrvc_D_St 1;
BA_ "U_V713N_MY2022_Rx" SG_ 651 TelematicsSrvc_D_St 1;
BA_ "U_V710_MY2023_Rx" SG_ 651 EmgcyCallMute_D_Stat 1;
BA_ "U_P708_MY2023_Rx" SG_ 651 EmgcyCallMute_D_Stat 1;
BA_ "U_V713AV_MY2022_Rx" SG_ 651 EmgcyCallMute_D_Stat 1;
BA_ "U_V713N_MY2022_Rx" SG_ 651 EmgcyCallMute_D_Stat 1;
BA_ "U_P708_MY2023_Rx" SG_ 1098 EcoCochInstTot_Pc_Dsply 1;
BA_ "GenSigStartValue" SG_ 1098 EcoCochInstTot_Pc_Dsply 255;
BA_ "U_V710_MY2023_Rx" SG_ 1098 EdmVeh_V_Dsply 1;
BA_ "U_P708_MY2023_Rx" SG_ 1098 EdmVeh_V_Dsply 1;
BA_ "U_V713AV_MY2022_Rx" SG_ 1098 EdmVeh_V_Dsply 1;
BA_ "U_V713N_MY2022_Rx" SG_ 1098 EdmVeh_V_Dsply 1;
BA_ "U_V710_MY2023_Rx" SG_ 1098 EdmSailMdeOn_B_Stat 1;
BA_ "U_P708_MY2023_Rx" SG_ 1098 EdmSailMdeOn_B_Stat 1;
BA_ "U_V713AV_MY2022_Rx" SG_ 1098 EdmSailMdeOn_B_Stat 1;
BA_ "U_V713N_MY2022_Rx" SG_ 1098 EdmSailMdeOn_B_Stat 1;
BA_ "U_V710_MY2023_Rx" SG_ 1098 EdmPrev_Fe_Dsply 1;
BA_ "U_P708_MY2023_Rx" SG_ 1098 EdmPrev_Fe_Dsply 1;
BA_ "U_V713AV_MY2022_Rx" SG_ 1098 EdmPrev_Fe_Dsply 1;
BA_ "U_V713N_MY2022_Rx" SG_ 1098 EdmPrev_Fe_Dsply 1;
BA_ "U_V710_MY2023_Rx" SG_ 1098 EdmMsgTxt_D_Rq 1;
BA_ "U_P708_MY2023_Rx" SG_ 1098 EdmMsgTxt_D_Rq 1;
BA_ "U_V713AV_MY2022_Rx" SG_ 1098 EdmMsgTxt_D_Rq 1;
BA_ "U_V713N_MY2022_Rx" SG_ 1098 EdmMsgTxt_D_Rq 1;
BA_ "U_V710_MY2023_Rx" SG_ 1098 EdmLamp_D_Dsply 1;
BA_ "U_V713AV_MY2022_Rx" SG_ 1098 EdmLamp_D_Dsply 1;
BA_ "U_V713N_MY2022_Rx" SG_ 1098 EdmLamp_D_Dsply 1;
BA_ "U_P708_MY2023_Rx" SG_ 1098 EdmLamp_D_Dsply 1;
BA_ "U_V710_MY2023_Rx" SG_ 1098 EdmCurrent_Fe_Dsply 1;
BA_ "U_P708_MY2023_Rx" SG_ 1098 EdmCurrent_Fe_Dsply 1;
BA_ "U_V713AV_MY2022_Rx" SG_ 1098 EdmCurrent_Fe_Dsply 1;
BA_ "U_V713N_MY2022_Rx" SG_ 1098 EdmCurrent_Fe_Dsply 1;
BA_ "U_V710_MY2023_Rx" SG_ 1098 EdmCmplnc_B_Dsply 1;
BA_ "U_V713AV_MY2022_Rx" SG_ 1098 EdmCmplnc_B_Dsply 1;
BA_ "U_V713N_MY2022_Rx" SG_ 1098 EdmCmplnc_B_Dsply 1;
BA_ "U_P708_MY2023_Rx" SG_ 1098 EdmCmplnc_B_Dsply 1;
BA_ "U_V710_MY2023_Rx" SG_ 1098 EdmCmplnc_Pc_Dsply 1;
BA_ "U_P708_MY2023_Rx" SG_ 1098 EdmCmplnc_Pc_Dsply 1;
BA_ "U_V713AV_MY2022_Rx" SG_ 1098 EdmCmplnc_Pc_Dsply 1;
BA_ "U_V713N_MY2022_Rx" SG_ 1098 EdmCmplnc_Pc_Dsply 1;
BA_ "U_V710_MY2023_Tx" SG_ 1239 CstmDrvMdeChassis_D_Rq 1;
BA_ "ECGUsedTxSignal" SG_ 1239 CstmDrvMdeChassis_D_Rq 1;
BA_ "GenSigSendType" SG_ 1239 CstmDrvMdeChassis_D_Rq 3;
BA_ "U_V710_MY2023_Tx" SG_ 1239 CstmDrvMdeHmi2_D_Rq 1;
BA_ "ECGUsedTxSignal" SG_ 1239 CstmDrvMdeHmi2_D_Rq 1;
BA_ "GenSigSendType" SG_ 1239 CstmDrvMdeHmi2_D_Rq 3;
BA_ "GenSigStartValue" SG_ 1239 CstmDrvMdeHmi2_D_Rq 31;
BA_ "U_V710_MY2023_Tx" SG_ 1239 CstmDrvMdeTracCtl_D_Rq 1;
BA_ "ECGUsedTxSignal" SG_ 1239 CstmDrvMdeTracCtl_D_Rq 1;
BA_ "GenSigSendType" SG_ 1239 CstmDrvMdeTracCtl_D_Rq 3;
BA_ "U_V710_MY2023_Tx" SG_ 1239 SeatOccRearChime_B_Rq 1;
BA_ "ECGUsedTxSignal" SG_ 1239 SeatOccRearChime_B_Rq 1;
BA_ "U_V710_MY2023_Rx" SG_ 1239 SeatOccRearChime_B_Rq 1;
BA_ "U_P708_MY2023_Rx" SG_ 1239 SeatOccRearChime_B_Rq 1;
BA_ "GenSigSendType" SG_ 1239 SeatOccRearChime_B_Rq 3;
BA_ "U_V710_MY2023_Tx" SG_ 1239 StabBarCnnctLamp_D_Cstm 1;
BA_ "ECGUsedTxSignal" SG_ 1239 StabBarCnnctLamp_D_Cstm 1;
BA_ "U_P708_MY2023_Rx" SG_ 1239 StabBarCnnctLamp_D_Cstm 1;
BA_ "GenSigSendType" SG_ 1239 StabBarCnnctLamp_D_Cstm 3;
BA_ "U_V710_MY2023_Tx" SG_ 1239 SelDrvMdeCstmLamp_D_Rq 1;
BA_ "ECGUsedTxSignal" SG_ 1239 SelDrvMdeCstmLamp_D_Rq 1;
BA_ "U_P708_MY2023_Rx" SG_ 1239 SelDrvMdeCstmLamp_D_Rq 1;
BA_ "GenSigSendType" SG_ 1239 SelDrvMdeCstmLamp_D_Rq 3;
BA_ "U_V710_MY2023_Tx" SG_ 1239 SelDrvMdeCstm_D_RqDrv 1;
BA_ "ECGUsedTxSignal" SG_ 1239 SelDrvMdeCstm_D_RqDrv 1;
BA_ "U_P708_MY2023_Rx" SG_ 1239 SelDrvMdeCstm_D_RqDrv 1;
BA_ "GenSigSendType" SG_ 1239 SelDrvMdeCstm_D_RqDrv 3;
BA_ "U_V710_MY2023_Tx" SG_ 1239 IndvMdeSuspCstm_No_Rq 1;
BA_ "ECGUsedTxSignal" SG_ 1239 IndvMdeSuspCstm_No_Rq 1;
BA_ "U_P708_MY2023_Rx" SG_ 1239 IndvMdeSuspCstm_No_Rq 1;
BA_ "GenSigSendType" SG_ 1239 IndvMdeSuspCstm_No_Rq 3;
BA_ "GenSigStartValue" SG_ 1239 IndvMdeSuspCstm_No_Rq 15;
BA_ "U_V710_MY2023_Tx" SG_ 1239 IndvMdeSteCstm_No_Rq 1;
BA_ "ECGUsedTxSignal" SG_ 1239 IndvMdeSteCstm_No_Rq 1;
BA_ "U_P708_MY2023_Rx" SG_ 1239 IndvMdeSteCstm_No_Rq 1;
BA_ "GenSigSendType" SG_ 1239 IndvMdeSteCstm_No_Rq 3;
BA_ "GenSigStartValue" SG_ 1239 IndvMdeSteCstm_No_Rq 15;
BA_ "U_V710_MY2023_Tx" SG_ 1239 CstmDrvMdeMsgTxt_D_Rq 1;
BA_ "ECGUsedTxSignal" SG_ 1239 CstmDrvMdeMsgTxt_D_Rq 1;
BA_ "U_P708_MY2023_Rx" SG_ 1239 CstmDrvMdeMsgTxt_D_Rq 1;
BA_ "GenSigSendType" SG_ 1239 CstmDrvMdeMsgTxt_D_Rq 3;
BA_ "U_V710_MY2023_Tx" SG_ 1239 ActvDrvMdeCstm_D2_Rq 1;
BA_ "ECGUsedTxSignal" SG_ 1239 ActvDrvMdeCstm_D2_Rq 1;
BA_ "U_P708_MY2023_Rx" SG_ 1239 ActvDrvMdeCstm_D2_Rq 1;
BA_ "GenSigSendType" SG_ 1239 ActvDrvMdeCstm_D2_Rq 3;
BA_ "GenSigStartValue" SG_ 1239 ActvDrvMdeCstm_D2_Rq 31;
BA_ "U_V710_MY2023_Rx" SG_ 785 BattElecPerf_D2_Actl 1;
BA_ "U_V710_MY2023_Rx" SG_ 785 RgenAnimation_B_Dsply 1;
BA_ "U_V710_MY2023_Rx" SG_ 785 VehVLimMsgTxt_B_Rq 1;
BA_ "U_V713AV_MY2022_Rx" SG_ 785 DteVehOffst_L_Dsply 1;
BA_ "U_V713N_MY2022_Rx" SG_ 785 DteVehOffst_L_Dsply 1;
BA_ "GenSigStartValue" SG_ 785 DteVehOffst_L_Dsply 8190;
BA_ "U_V710_MY2023_Rx" SG_ 785 DteVehOffstMsgTxt_D_Rq 1;
BA_ "U_V713AV_MY2022_Rx" SG_ 785 DteVehOffstMsgTxt_D_Rq 1;
BA_ "U_V713N_MY2022_Rx" SG_ 785 DteVehOffstMsgTxt_D_Rq 1;
BA_ "U_V710_MY2023_Rx" SG_ 785 PwPckTqRdyChime_B_Rq 1;
BA_ "U_V713AV_MY2022_Rx" SG_ 785 PwPckTqRdyChime_B_Rq 1;
BA_ "U_V713N_MY2022_Rx" SG_ 785 PwPckTqRdyChime_B_Rq 1;
BA_ "U_V710_MY2023_Rx" SG_ 785 BattTracLoThres_D_Stat 1;
BA_ "U_V710_MY2023_Rx" SG_ 785 BattTracLoMsgTxt_D_Rq 1;
BA_ "U_V713AV_MY2022_Rx" SG_ 785 BattTracLoMsgTxt_D_Rq 1;
BA_ "U_V713N_MY2022_Rx" SG_ 785 BattTracLoMsgTxt_D_Rq 1;
BA_ "U_V710_MY2023_Rx" SG_ 785 DestSocRqd_Pc_Dsply 1;
BA_ "U_V713AV_MY2022_Rx" SG_ 785 DestSocRqd_Pc_Dsply 1;
BA_ "U_V713N_MY2022_Rx" SG_ 785 DestSocRqd_Pc_Dsply 1;
BA_ "U_V713AV_MY2022_Rx" SG_ 785 DestChrgEndMin_No_Actl 1;
BA_ "U_V713N_MY2022_Rx" SG_ 785 DestChrgEndMin_No_Actl 1;
BA_ "U_V713AV_MY2022_Rx" SG_ 785 DestChrgEndHr_No_Actl 1;
BA_ "U_V713N_MY2022_Rx" SG_ 785 DestChrgEndHr_No_Actl 1;
BA_ "U_V713AV_MY2022_Rx" SG_ 785 DestChrgEndDay_No_Actl 1;
BA_ "U_V713N_MY2022_Rx" SG_ 785 DestChrgEndDay_No_Actl 1;
BA_ "GenSigStartValue" SG_ 785 DestChrgEndDay_No_Actl 1;
BA_ "U_V710_MY2023_Rx" SG_ 785 BattTracLoSoc_D_Dsply 1;
BA_ "U_V713AV_MY2022_Rx" SG_ 785 BattTracLoSoc_D_Dsply 1;
BA_ "U_V713N_MY2022_Rx" SG_ 785 BattTracLoSoc_D_Dsply 1;
BA_ "U_V710_MY2023_Rx" SG_ 785 BattTracLimPerf_D_Dsply 1;
BA_ "U_V713AV_MY2022_Rx" SG_ 785 BattTracLimPerf_D_Dsply 1;
BA_ "U_V713N_MY2022_Rx" SG_ 785 BattTracLimPerf_D_Dsply 1;
BA_ "U_V710_MY2023_Tx" SG_ 1210 SDARS_VR_WORD_Tx 1;
BA_ "U_P708_MY2023_Tx" SG_ 1210 SDARS_VR_WORD_Tx 1;
BA_ "U_V713AV_MY2022_Tx" SG_ 1210 SDARS_VR_WORD_Tx 1;
BA_ "U_V713N_MY2022_Tx" SG_ 1210 SDARS_VR_WORD_Tx 1;
BA_ "U_P708_MY2023_Rx" SG_ 1202 SDARS_VR_WORD_Rx 1;
BA_ "U_V713AV_MY2022_Rx" SG_ 1202 SDARS_VR_WORD_Rx 1;
BA_ "U_V713N_MY2022_Rx" SG_ 1202 SDARS_VR_WORD_Rx 1;
BA_ "U_V710_MY2023_Rx" SG_ 415 LBC3_StartItemInd 1;
BA_ "U_P708_MY2023_Rx" SG_ 415 LBC3_StartItemInd 1;
BA_ "U_V713AV_MY2022_Rx" SG_ 415 LBC3_StartItemInd 1;
BA_ "U_V713N_MY2022_Rx" SG_ 415 LBC3_StartItemInd 1;
BA_ "U_V710_MY2023_Rx" SG_ 415 LBC3_SetListServ 1;
BA_ "U_P708_MY2023_Rx" SG_ 415 LBC3_SetListServ 1;
BA_ "U_V713AV_MY2022_Rx" SG_ 415 LBC3_SetListServ 1;
BA_ "U_V713N_MY2022_Rx" SG_ 415 LBC3_SetListServ 1;
BA_ "U_V710_MY2023_Rx" SG_ 415 LBC3_Opcode 1;
BA_ "U_P708_MY2023_Rx" SG_ 415 LBC3_Opcode 1;
BA_ "U_V713AV_MY2022_Rx" SG_ 415 LBC3_Opcode 1;
BA_ "U_V713N_MY2022_Rx" SG_ 415 LBC3_Opcode 1;
BA_ "GenSigSendType" SG_ 415 LBC3_Opcode 3;
BA_ "U_V710_MY2023_Rx" SG_ 415 LBC3_NbrOfItems 1;
BA_ "U_P708_MY2023_Rx" SG_ 415 LBC3_NbrOfItems 1;
BA_ "U_V713AV_MY2022_Rx" SG_ 415 LBC3_NbrOfItems 1;
BA_ "U_V713N_MY2022_Rx" SG_ 415 LBC3_NbrOfItems 1;
BA_ "U_V710_MY2023_Rx" SG_ 415 LBC3_ItemIndex 1;
BA_ "U_P708_MY2023_Rx" SG_ 415 LBC3_ItemIndex 1;
BA_ "U_V713AV_MY2022_Rx" SG_ 415 LBC3_ItemIndex 1;
BA_ "U_V713N_MY2022_Rx" SG_ 415 LBC3_ItemIndex 1;
BA_ "U_V710_MY2023_Rx" SG_ 415 LBC3_ActiveListID 1;
BA_ "U_P708_MY2023_Rx" SG_ 415 LBC3_ActiveListID 1;
BA_ "U_V713AV_MY2022_Rx" SG_ 415 LBC3_ActiveListID 1;
BA_ "U_V713N_MY2022_Rx" SG_ 415 LBC3_ActiveListID 1;
BA_ "U_P708_MY2023_Rx" SG_ 695 CONMP_MC_WORD_Tx 1;
BA_ "U_P708_MY2023_Tx" SG_ 703 CONMP_MC_WORD_Rx 1;
BA_ "U_V713AV_MY2022_Tx" SG_ 703 CONMP_MC_WORD_Rx 1;
BA_ "U_V713N_MY2022_Tx" SG_ 703 CONMP_MC_WORD_Rx 1;
BA_ "U_V710_MY2023_Rx" SG_ 1829 TesterPhysicalReqWCM 1;
BA_ "U_P708_MY2023_Rx" SG_ 1829 TesterPhysicalReqWCM 1;
BA_ "U_V713N_MY2022_Rx" SG_ 1829 TesterPhysicalReqWCM 1;
BA_ "GenSigSendType" SG_ 1829 TesterPhysicalReqWCM 3;
BA_ "U_V710_MY2023_Rx" SG_ 332 UreaLvlQlty_D_RqDsply 1;
BA_ "U_P708_MY2023_Rx" SG_ 332 UreaLvlQlty_D_RqDsply 1;
BA_ "U_V710_MY2023_Rx" SG_ 332 UreaLvlTxtWarn_D_Rq 1;
BA_ "U_P708_MY2023_Rx" SG_ 332 UreaLvlTxtWarn_D_Rq 1;
BA_ "U_V710_MY2023_Rx" SG_ 332 UreaQltySysWarn_D_Rq 1;
BA_ "U_P708_MY2023_Rx" SG_ 332 UreaQltySysWarn_D_Rq 1;
BA_ "U_V710_MY2023_Rx" SG_ 332 DieslPrtcWarn_D_Rq 1;
BA_ "U_P708_MY2023_Rx" SG_ 332 DieslPrtcWarn_D_Rq 1;
BA_ "U_V710_MY2023_Rx" SG_ 332 UreaQltyFlg_B_RqDsply 1;
BA_ "U_P708_MY2023_Rx" SG_ 332 UreaQltyFlg_B_RqDsply 1;
BA_ "U_P708_MY2023_Rx" SG_ 332 ExhOverheat_T_Actl 1;
BA_ "U_V710_MY2023_Rx" SG_ 332 UreaLvl_Pc_Actl 1;
BA_ "U_P708_MY2023_Rx" SG_ 332 UreaLvl_Pc_Actl 1;
BA_ "U_V710_MY2023_Rx" SG_ 332 VehUreaRnge2_L_DsplyMx 1;
BA_ "U_P708_MY2023_Rx" SG_ 332 VehUreaRnge2_L_DsplyMx 1;
BA_ "U_V710_MY2023_Rx" SG_ 332 UreaQltySys_D_RqDsply 1;
BA_ "U_P708_MY2023_Rx" SG_ 332 UreaQltySys_D_RqDsply 1;
BA_ "U_V710_MY2023_Rx" SG_ 332 UreaLvlTxt_D_RqDsply 1;
BA_ "U_P708_MY2023_Rx" SG_ 332 UreaLvlTxt_D_RqDsply 1;
BA_ "U_P708_MY2023_Rx" SG_ 332 VehUreaImmo_No_DsplyMx 1;
BA_ "U_V710_MY2023_Rx" SG_ 332 VehUreaWarn_V_DsplyMx 1;
BA_ "U_P708_MY2023_Rx" SG_ 332 VehUreaWarn_V_DsplyMx 1;
BA_ "U_V710_MY2023_Tx" SG_ 2612224096 PARSEDPushIPCtoGWM_ECG 1;
BA_ "U_P708_MY2023_Tx" SG_ 2612224096 PARSEDPushIPCtoGWM_ECG 1;
BA_ "U_V713AV_MY2022_Tx" SG_ 2612224096 PARSEDPushIPCtoGWM_ECG 1;
BA_ "U_V713N_MY2022_Tx" SG_ 2612224096 PARSEDPushIPCtoGWM_ECG 1;
BA_ "U_V710_MY2023_Rx" SG_ 2612224096 PARSEDPushIPCtoGWM_ECG 1;
BA_ "U_P708_MY2023_Rx" SG_ 2612224096 PARSEDPushIPCtoGWM_ECG 1;
BA_ "U_V713AV_MY2022_Rx" SG_ 2612224096 PARSEDPushIPCtoGWM_ECG 1;
BA_ "U_V713N_MY2022_Rx" SG_ 2612224096 PARSEDPushIPCtoGWM_ECG 1;
BA_ "ECGUsedRxSignal" SG_ 2612224096 PARSEDPushIPCtoGWM_ECG 1;
BA_ "GenSigSendType" SG_ 2612224096 PARSEDPushIPCtoGWM_ECG 3;
BA_ "U_V710_MY2023_Tx" SG_ 2612101336 PARSEDPushFcGWM_ECGtoIPC 1;
BA_ "U_P708_MY2023_Tx" SG_ 2612101336 PARSEDPushFcGWM_ECGtoIPC 1;
BA_ "U_V713AV_MY2022_Tx" SG_ 2612101336 PARSEDPushFcGWM_ECGtoIPC 1;
BA_ "U_V713N_MY2022_Tx" SG_ 2612101336 PARSEDPushFcGWM_ECGtoIPC 1;
BA_ "ECGUsedTxSignal" SG_ 2612101336 PARSEDPushFcGWM_ECGtoIPC 1;
BA_ "U_V710_MY2023_Rx" SG_ 2612101336 PARSEDPushFcGWM_ECGtoIPC 1;
BA_ "U_P708_MY2023_Rx" SG_ 2612101336 PARSEDPushFcGWM_ECGtoIPC 1;
BA_ "GenSigSendType" SG_ 2612101336 PARSEDPushFcGWM_ECGtoIPC 3;
BA_ "U_V710_MY2023_Rx" SG_ 636 WifiHtsptFqBand_D_Stat 1;
BA_ "U_P708_MY2023_Rx" SG_ 636 WifiHtsptFqBand_D_Stat 1;
BA_ "U_V713AV_MY2022_Rx" SG_ 636 WifiHtsptFqBand_D_Stat 1;
BA_ "U_V713N_MY2022_Rx" SG_ 636 WifiHtsptFqBand_D_Stat 1;
BA_ "U_V710_MY2023_Rx" SG_ 636 WifiHtspt_D_Falt 1;
BA_ "U_P708_MY2023_Rx" SG_ 636 WifiHtspt_D_Falt 1;
BA_ "U_V713AV_MY2022_Rx" SG_ 636 WifiHtspt_D_Falt 1;
BA_ "U_V713N_MY2022_Rx" SG_ 636 WifiHtspt_D_Falt 1;
BA_ "U_V710_MY2023_Rx" SG_ 636 ModemSigStren_D_Stat 1;
BA_ "U_P708_MY2023_Rx" SG_ 636 ModemSigStren_D_Stat 1;
BA_ "U_V713AV_MY2022_Rx" SG_ 636 ModemSigStren_D_Stat 1;
BA_ "U_V713N_MY2022_Rx" SG_ 636 ModemSigStren_D_Stat 1;
BA_ "GenSigStartValue" SG_ 636 ModemSigStren_D_Stat 6;
BA_ "U_P708_MY2023_Rx" SG_ 636 ModemTechnology_D2_Stat 1;
BA_ "U_V710_MY2023_Rx" SG_ 636 WifiHtsptFq_D_Avail 1;
BA_ "U_P708_MY2023_Rx" SG_ 636 WifiHtsptFq_D_Avail 1;
BA_ "U_V713AV_MY2022_Rx" SG_ 636 WifiHtsptFq_D_Avail 1;
BA_ "U_V713N_MY2022_Rx" SG_ 636 WifiHtsptFq_D_Avail 1;
BA_ "U_V710_MY2023_Tx" SG_ 805 FuelRange_L2_Dsply 1;
BA_ "U_V710_MY2023_Rx" SG_ 805 FuelRange_L2_Dsply 1;
BA_ "ECGUsedRxSignal" SG_ 805 FuelRange_L2_Dsply 1;
BA_ "U_V710_MY2023_Tx" SG_ 805 InstFeTripUnit_D_Stat 1;
BA_ "U_P708_MY2023_Tx" SG_ 805 InstFeTripUnit_D_Stat 1;
BA_ "U_V710_MY2023_Tx" SG_ 805 InstFe_No_Dsply 1;
BA_ "U_P708_MY2023_Tx" SG_ 805 InstFe_No_Dsply 1;
BA_ "U_V710_MY2023_Tx" SG_ 804 InstFeMax_No_Dsply 1;
BA_ "U_P708_MY2023_Tx" SG_ 804 InstFeMax_No_Dsply 1;
BA_ "GenSigSendType" SG_ 804 InstFeMax_No_Dsply 3;
BA_ "U_V710_MY2023_Tx" SG_ 804 ConsInstActv_B_Dsply 1;
BA_ "U_P708_MY2023_Tx" SG_ 804 ConsInstActv_B_Dsply 1;
BA_ "GenSigSendType" SG_ 804 ConsInstActv_B_Dsply 3;
BA_ "U_V710_MY2023_Tx" SG_ 804 ConsInst_No_Dsply 1;
BA_ "U_P708_MY2023_Tx" SG_ 804 ConsInst_No_Dsply 1;
BA_ "GenSigSendType" SG_ 804 ConsInst_No_Dsply 3;
BA_ "U_V710_MY2023_Tx" SG_ 804 ConsInstUnit_D_Stat 1;
BA_ "U_P708_MY2023_Tx" SG_ 804 ConsInstUnit_D_Stat 1;
BA_ "GenSigSendType" SG_ 804 ConsInstUnit_D_Stat 3;
BA_ "U_V710_MY2023_Tx" SG_ 803 DistTripUnit_D_Stat 1;
BA_ "U_P708_MY2023_Tx" SG_ 803 DistTripUnit_D_Stat 1;
BA_ "U_V713AV_MY2022_Tx" SG_ 803 DistTripUnit_D_Stat 1;
BA_ "U_V713N_MY2022_Tx" SG_ 803 DistTripUnit_D_Stat 1;
BA_ "GenSigSendType" SG_ 803 DistTripUnit_D_Stat 3;
BA_ "U_V710_MY2023_Tx" SG_ 803 DistTrip2_No_Dsply 1;
BA_ "U_P708_MY2023_Tx" SG_ 803 DistTrip2_No_Dsply 1;
BA_ "U_V713AV_MY2022_Tx" SG_ 803 DistTrip2_No_Dsply 1;
BA_ "U_V713N_MY2022_Tx" SG_ 803 DistTrip2_No_Dsply 1;
BA_ "GenSigSendType" SG_ 803 DistTrip2_No_Dsply 3;
BA_ "U_V710_MY2023_Tx" SG_ 803 DistTrip1_No_Dsply 1;
BA_ "U_P708_MY2023_Tx" SG_ 803 DistTrip1_No_Dsply 1;
BA_ "U_V713AV_MY2022_Tx" SG_ 803 DistTrip1_No_Dsply 1;
BA_ "U_V713N_MY2022_Tx" SG_ 803 DistTrip1_No_Dsply 1;
BA_ "GenSigSendType" SG_ 803 DistTrip1_No_Dsply 3;
BA_ "U_V710_MY2023_Tx" SG_ 802 AvgFeTripUnit_D_Stat 1;
BA_ "U_P708_MY2023_Tx" SG_ 802 AvgFeTripUnit_D_Stat 1;
BA_ "U_V713AV_MY2022_Tx" SG_ 802 AvgFeTripUnit_D_Stat 1;
BA_ "U_V713N_MY2022_Tx" SG_ 802 AvgFeTripUnit_D_Stat 1;
BA_ "GenSigSendType" SG_ 802 AvgFeTripUnit_D_Stat 3;
BA_ "U_V710_MY2023_Tx" SG_ 802 AvgFeTrip2Actv_B_Dsply 1;
BA_ "U_P708_MY2023_Tx" SG_ 802 AvgFeTrip2Actv_B_Dsply 1;
BA_ "U_V713AV_MY2022_Tx" SG_ 802 AvgFeTrip2Actv_B_Dsply 1;
BA_ "U_V713N_MY2022_Tx" SG_ 802 AvgFeTrip2Actv_B_Dsply 1;
BA_ "GenSigSendType" SG_ 802 AvgFeTrip2Actv_B_Dsply 3;
BA_ "U_V710_MY2023_Tx" SG_ 802 AvgFeTrip2_No_Dsply 1;
BA_ "U_P708_MY2023_Tx" SG_ 802 AvgFeTrip2_No_Dsply 1;
BA_ "U_V713AV_MY2022_Tx" SG_ 802 AvgFeTrip2_No_Dsply 1;
BA_ "U_V713N_MY2022_Tx" SG_ 802 AvgFeTrip2_No_Dsply 1;
BA_ "GenSigSendType" SG_ 802 AvgFeTrip2_No_Dsply 3;
BA_ "U_V710_MY2023_Tx" SG_ 802 AvgFeTrip1Actv_B_Dsply 1;
BA_ "U_P708_MY2023_Tx" SG_ 802 AvgFeTrip1Actv_B_Dsply 1;
BA_ "U_V713AV_MY2022_Tx" SG_ 802 AvgFeTrip1Actv_B_Dsply 1;
BA_ "U_V713N_MY2022_Tx" SG_ 802 AvgFeTrip1Actv_B_Dsply 1;
BA_ "GenSigSendType" SG_ 802 AvgFeTrip1Actv_B_Dsply 3;
BA_ "U_V710_MY2023_Tx" SG_ 802 AvgFeTrip1_No_Dsply 1;
BA_ "U_P708_MY2023_Tx" SG_ 802 AvgFeTrip1_No_Dsply 1;
BA_ "U_V713AV_MY2022_Tx" SG_ 802 AvgFeTrip1_No_Dsply 1;
BA_ "U_V713N_MY2022_Tx" SG_ 802 AvgFeTrip1_No_Dsply 1;
BA_ "GenSigSendType" SG_ 802 AvgFeTrip1_No_Dsply 3;
BA_ "U_V710_MY2023_Tx" SG_ 802 AvgFeActv_B_Dsply 1;
BA_ "U_P708_MY2023_Tx" SG_ 802 AvgFeActv_B_Dsply 1;
BA_ "U_V713AV_MY2022_Tx" SG_ 802 AvgFeActv_B_Dsply 1;
BA_ "U_V713N_MY2022_Tx" SG_ 802 AvgFeActv_B_Dsply 1;
BA_ "GenSigSendType" SG_ 802 AvgFeActv_B_Dsply 3;
BA_ "U_V710_MY2023_Tx" SG_ 802 AvgFe_No_Dsply 1;
BA_ "U_P708_MY2023_Tx" SG_ 802 AvgFe_No_Dsply 1;
BA_ "U_V713AV_MY2022_Tx" SG_ 802 AvgFe_No_Dsply 1;
BA_ "U_V713N_MY2022_Tx" SG_ 802 AvgFe_No_Dsply 1;
BA_ "GenSigSendType" SG_ 802 AvgFe_No_Dsply 3;
BA_ "U_V710_MY2023_Tx" SG_ 812 TimerTrip2_T_Dsply 1;
BA_ "U_P708_MY2023_Tx" SG_ 812 TimerTrip2_T_Dsply 1;
BA_ "GenSigSendType" SG_ 812 TimerTrip2_T_Dsply 3;
BA_ "U_V710_MY2023_Tx" SG_ 812 TimerTrip1_T_Dsply 1;
BA_ "U_P708_MY2023_Tx" SG_ 812 TimerTrip1_T_Dsply 1;
BA_ "GenSigSendType" SG_ 812 TimerTrip1_T_Dsply 3;
BA_ "U_V710_MY2023_Tx" SG_ 885 VehStrtInhbt_T_Dsply 1;
BA_ "U_P708_MY2023_Tx" SG_ 885 VehStrtInhbt_T_Dsply 1;
BA_ "U_V713AV_MY2022_Tx" SG_ 885 VehStrtInhbt_T_Dsply 1;
BA_ "U_V713N_MY2022_Tx" SG_ 885 VehStrtInhbt_T_Dsply 1;
BA_ "ECGUsedTxSignal" SG_ 885 VehStrtInhbt_T_Dsply 1;
BA_ "U_V710_MY2023_Rx" SG_ 885 VehStrtInhbt_T_Dsply 1;
BA_ "U_P708_MY2023_Rx" SG_ 885 VehStrtInhbt_T_Dsply 1;
BA_ "U_V710_MY2023_Tx" SG_ 885 VehStrtInhbt_D_Dsply 1;
BA_ "U_P708_MY2023_Tx" SG_ 885 VehStrtInhbt_D_Dsply 1;
BA_ "U_V713AV_MY2022_Tx" SG_ 885 VehStrtInhbt_D_Dsply 1;
BA_ "U_V713N_MY2022_Tx" SG_ 885 VehStrtInhbt_D_Dsply 1;
BA_ "ECGUsedTxSignal" SG_ 885 VehStrtInhbt_D_Dsply 1;
BA_ "U_V710_MY2023_Rx" SG_ 885 VehStrtInhbt_D_Dsply 1;
BA_ "U_P708_MY2023_Rx" SG_ 885 VehStrtInhbt_D_Dsply 1;
BA_ "U_V710_MY2023_Tx" SG_ 885 OtaActv_D_Stat 1;
BA_ "U_P708_MY2023_Tx" SG_ 885 OtaActv_D_Stat 1;
BA_ "U_V713AV_MY2022_Tx" SG_ 885 OtaActv_D_Stat 1;
BA_ "U_V713N_MY2022_Tx" SG_ 885 OtaActv_D_Stat 1;
BA_ "ECGUsedTxSignal" SG_ 885 OtaActv_D_Stat 1;
BA_ "U_P708_MY2023_Rx" SG_ 885 OtaActv_D_Stat 1;
BA_ "U_P708_MY2023_Rx" SG_ 784 TrlrTireTSensRr_D_Stat 1;
BA_ "U_V713N_MY2022_Rx" SG_ 784 TrlrTireTSensRr_D_Stat 1;
BA_ "U_P708_MY2023_Rx" SG_ 784 TrlrTireTSensRm_D_Stat 1;
BA_ "U_V713N_MY2022_Rx" SG_ 784 TrlrTireTSensRm_D_Stat 1;
BA_ "U_P708_MY2023_Rx" SG_ 784 TrlrTireTSensRf_D_Stat 1;
BA_ "U_V713N_MY2022_Rx" SG_ 784 TrlrTireTSensRf_D_Stat 1;
BA_ "U_P708_MY2023_Rx" SG_ 784 TrlrTireTSensLr_D_Stat 1;
BA_ "U_V713N_MY2022_Rx" SG_ 784 TrlrTireTSensLr_D_Stat 1;
BA_ "U_P708_MY2023_Rx" SG_ 784 TrlrTireTSensLm_D_Stat 1;
BA_ "U_V713N_MY2022_Rx" SG_ 784 TrlrTireTSensLm_D_Stat 1;
BA_ "U_P708_MY2023_Rx" SG_ 784 TrlrTireTSensLf_D_Stat 1;
BA_ "U_V713N_MY2022_Rx" SG_ 784 TrlrTireTSensLf_D_Stat 1;
BA_ "U_P708_MY2023_Rx" SG_ 784 TrlrTireTempSys_D_Stat 1;
BA_ "U_V713N_MY2022_Rx" SG_ 784 TrlrTireTempSys_D_Stat 1;
BA_ "GenSigStartValue" SG_ 784 TrlrTireTempSys_D_Stat 3;
BA_ "U_P708_MY2023_Rx" SG_ 784 TrlrTireRr_T_Actl 1;
BA_ "U_V713N_MY2022_Rx" SG_ 784 TrlrTireRr_T_Actl 1;
BA_ "GenSigStartValue" SG_ 784 TrlrTireRr_T_Actl 253;
BA_ "U_P708_MY2023_Rx" SG_ 784 TrlrTireRm_T_Actl 1;
BA_ "U_V713N_MY2022_Rx" SG_ 784 TrlrTireRm_T_Actl 1;
BA_ "GenSigStartValue" SG_ 784 TrlrTireRm_T_Actl 253;
BA_ "U_P708_MY2023_Rx" SG_ 784 TrlrTireRf_T_Actl 1;
BA_ "U_V713N_MY2022_Rx" SG_ 784 TrlrTireRf_T_Actl 1;
BA_ "GenSigStartValue" SG_ 784 TrlrTireRf_T_Actl 253;
BA_ "U_P708_MY2023_Rx" SG_ 784 TrlrTireLr_T_Actl 1;
BA_ "U_V713N_MY2022_Rx" SG_ 784 TrlrTireLr_T_Actl 1;
BA_ "GenSigStartValue" SG_ 784 TrlrTireLr_T_Actl 253;
BA_ "U_P708_MY2023_Rx" SG_ 784 TrlrTireLm_T_Actl 1;
BA_ "U_V713N_MY2022_Rx" SG_ 784 TrlrTireLm_T_Actl 1;
BA_ "GenSigStartValue" SG_ 784 TrlrTireLm_T_Actl 253;
BA_ "U_P708_MY2023_Rx" SG_ 784 TrlrTireLf_T_Actl 1;
BA_ "U_V713N_MY2022_Rx" SG_ 784 TrlrTireLf_T_Actl 1;
BA_ "GenSigStartValue" SG_ 784 TrlrTireLf_T_Actl 253;
BA_ "U_V710_MY2023_Rx" SG_ 1119 LocationServices_2 1;
BA_ "U_V713AV_MY2022_Rx" SG_ 1119 LocationServices_2 1;
BA_ "U_V713N_MY2022_Rx" SG_ 1119 LocationServices_2 1;
BA_ "ECGUsedRxSignal" SG_ 1119 LocationServices_2 1;
BA_ "U_P708_MY2023_Rx" SG_ 1119 LocationServices_2 1;
BA_ "GenSigSendType" SG_ 1119 LocationServices_2 1;
BA_ "U_V710_MY2023_Rx" SG_ 1118 LocationServices_1 1;
BA_ "U_V713AV_MY2022_Rx" SG_ 1118 LocationServices_1 1;
BA_ "ECGUsedRxSignal" SG_ 1118 LocationServices_1 1;
BA_ "U_P708_MY2023_Rx" SG_ 1118 LocationServices_1 1;
BA_ "U_V713N_MY2022_Rx" SG_ 1118 LocationServices_1 1;
BA_ "GenSigSendType" SG_ 1118 LocationServices_1 1;
BA_ "GenSigSendType" SG_ 290 WifiHtsptFqBand_D_Rq 3;
BA_ "GenSigSendType" SG_ 290 WifiHtsptTrial_D_RqDrv 3;
BA_ "GenSigSendType" SG_ 290 WifiHtsptEnbl_D_Rq 3;
BA_ "GenSigStartValue" SG_ 290 WifiRemoveIndx_No_Rq 20;
BA_ "GenSigSendType" SG_ 290 WifiRemoveDevc_D_Rq 3;
BA_ "GenSigSendType" SG_ 290 WifiHtsptVisbl_D_Rq 3;
BA_ "GenSigSendType" SG_ 290 WifiHtsptMacAddr_B_Rq 3;
BA_ "GenSigStartValue" SG_ 290 WifiDevcListIndx_No_Rq 22;
BA_ "GenSigSendType" SG_ 290 WifiDevcList_D_Rq 3;
BA_ "GenSigSendType" SG_ 290 WifiDataUsage_D_Rq 3;
BA_ "GenSigSendType" SG_ 290 WifiCarrierInfo_B_Rq 3;
BA_ "GenSigSendType" SG_ 290 WifiHtsptScrty_D_Rq 3;
BA_ "U_V710_MY2023_Tx" SG_ 554 SeatOccRearMsgTxt_B_Rq 1;
BA_ "ECGUsedTxSignal" SG_ 554 SeatOccRearMsgTxt_B_Rq 1;
BA_ "GenSigSendType" SG_ 554 SeatOccRearMsgTxt_B_Rq 3;
BA_ "U_V710_MY2023_Tx" SG_ 554 Frt_Btn_Status_1st_2 1;
BA_ "ECGUsedTxSignal" SG_ 554 Frt_Btn_Status_1st_2 1;
BA_ "GenSigSendType" SG_ 554 Frt_Btn_Status_1st_2 3;
BA_ "U_V710_MY2023_Tx" SG_ 554 Drv_Set_Tmp2 1;
BA_ "ECGUsedTxSignal" SG_ 554 Drv_Set_Tmp2 1;
BA_ "GenSigSendType" SG_ 554 Drv_Set_Tmp2 3;
BA_ "U_V710_MY2023_Tx" SG_ 554 DrvHazrdModel_D_St 1;
BA_ "U_V713AV_MY2022_Tx" SG_ 554 DrvHazrdModel_D_St 1;
BA_ "U_V713N_MY2022_Tx" SG_ 554 DrvHazrdModel_D_St 1;
BA_ "ECGUsedTxSignal" SG_ 554 DrvHazrdModel_D_St 1;
BA_ "GenSigSendType" SG_ 554 DrvHazrdModel_D_St 3;
BA_ "U_V710_MY2023_Tx" SG_ 554 DrvHazrd_D_St 1;
BA_ "U_V713AV_MY2022_Tx" SG_ 554 DrvHazrd_D_St 1;
BA_ "U_V713N_MY2022_Tx" SG_ 554 DrvHazrd_D_St 1;
BA_ "ECGUsedTxSignal" SG_ 554 DrvHazrd_D_St 1;
BA_ "U_V710_MY2023_Rx" SG_ 554 DrvHazrd_D_St 1;
BA_ "GenSigSendType" SG_ 554 DrvHazrd_D_St 3;
BA_ "U_V710_MY2023_Tx" SG_ 554 PtWakeupActv1_B_Rq 1;
BA_ "U_V713AV_MY2022_Tx" SG_ 554 PtWakeupActv1_B_Rq 1;
BA_ "U_V713N_MY2022_Tx" SG_ 554 PtWakeupActv1_B_Rq 1;
BA_ "ECGUsedTxSignal" SG_ 554 PtWakeupActv1_B_Rq 1;
BA_ "GenSigSendType" SG_ 554 PtWakeupActv1_B_Rq 3;
BA_ "WakeupSignal" SG_ 554 PtWakeupActv1_B_Rq 1;
BA_ "U_V710_MY2023_Rx" SG_ 419 MK_SpeedValue_Rq 1;
BA_ "U_P708_MY2023_Rx" SG_ 419 MK_SpeedValue_Rq 1;
BA_ "U_V713AV_MY2022_Rx" SG_ 419 MK_SpeedValue_Rq 1;
BA_ "U_V713N_MY2022_Rx" SG_ 419 MK_SpeedValue_Rq 1;
BA_ "U_V710_MY2023_Rx" SG_ 419 MK_SpeedSetting_Rq 1;
BA_ "U_P708_MY2023_Rx" SG_ 419 MK_SpeedSetting_Rq 1;
BA_ "U_V713AV_MY2022_Rx" SG_ 419 MK_SpeedSetting_Rq 1;
BA_ "U_V713N_MY2022_Rx" SG_ 419 MK_SpeedSetting_Rq 1;
BA_ "GenSigSendType" SG_ 419 MK_SpeedSetting_Rq 3;
BA_ "U_V710_MY2023_Rx" SG_ 419 MK_ResetAllUserKeys_Rq 1;
BA_ "U_P708_MY2023_Rx" SG_ 419 MK_ResetAllUserKeys_Rq 1;
BA_ "U_V713AV_MY2022_Rx" SG_ 419 MK_ResetAllUserKeys_Rq 1;
BA_ "U_V713N_MY2022_Rx" SG_ 419 MK_ResetAllUserKeys_Rq 1;
BA_ "GenSigSendType" SG_ 419 MK_ResetAllUserKeys_Rq 3;
BA_ "U_V710_MY2023_Rx" SG_ 419 MK_MyKeySystemInfo_Rq 1;
BA_ "U_P708_MY2023_Rx" SG_ 419 MK_MyKeySystemInfo_Rq 1;
BA_ "U_V713AV_MY2022_Rx" SG_ 419 MK_MyKeySystemInfo_Rq 1;
BA_ "U_V713N_MY2022_Rx" SG_ 419 MK_MyKeySystemInfo_Rq 1;
BA_ "GenSigSendType" SG_ 419 MK_MyKeySystemInfo_Rq 3;
BA_ "U_V710_MY2023_Rx" SG_ 419 MK_ESCRestrictConf_Rq 1;
BA_ "U_P708_MY2023_Rx" SG_ 419 MK_ESCRestrictConf_Rq 1;
BA_ "U_V713AV_MY2022_Rx" SG_ 419 MK_ESCRestrictConf_Rq 1;
BA_ "U_V713N_MY2022_Rx" SG_ 419 MK_ESCRestrictConf_Rq 1;
BA_ "GenSigSendType" SG_ 419 MK_ESCRestrictConf_Rq 3;
BA_ "U_V710_MY2023_Rx" SG_ 419 MK_ECalRestrictConf_Rq 1;
BA_ "U_P708_MY2023_Rx" SG_ 419 MK_ECalRestrictConf_Rq 1;
BA_ "U_V713AV_MY2022_Rx" SG_ 419 MK_ECalRestrictConf_Rq 1;
BA_ "U_V713N_MY2022_Rx" SG_ 419 MK_ECalRestrictConf_Rq 1;
BA_ "GenSigSendType" SG_ 419 MK_ECalRestrictConf_Rq 3;
BA_ "U_V710_MY2023_Rx" SG_ 419 MK_DNDRestrictConf_Rq 1;
BA_ "U_P708_MY2023_Rx" SG_ 419 MK_DNDRestrictConf_Rq 1;
BA_ "U_V713AV_MY2022_Rx" SG_ 419 MK_DNDRestrictConf_Rq 1;
BA_ "U_V713N_MY2022_Rx" SG_ 419 MK_DNDRestrictConf_Rq 1;
BA_ "GenSigSendType" SG_ 419 MK_DNDRestrictConf_Rq 3;
BA_ "U_V710_MY2023_Rx" SG_ 419 MK_CreateMyKey_Rq 1;
BA_ "U_P708_MY2023_Rx" SG_ 419 MK_CreateMyKey_Rq 1;
BA_ "U_V713AV_MY2022_Rx" SG_ 419 MK_CreateMyKey_Rq 1;
BA_ "U_V713N_MY2022_Rx" SG_ 419 MK_CreateMyKey_Rq 1;
BA_ "GenSigSendType" SG_ 419 MK_CreateMyKey_Rq 3;
BA_ "U_V710_MY2023_Rx" SG_ 419 MK_AudioLimitConfig_Rq 1;
BA_ "U_P708_MY2023_Rx" SG_ 419 MK_AudioLimitConfig_Rq 1;
BA_ "U_V713AV_MY2022_Rx" SG_ 419 MK_AudioLimitConfig_Rq 1;
BA_ "U_V713N_MY2022_Rx" SG_ 419 MK_AudioLimitConfig_Rq 1;
BA_ "GenSigSendType" SG_ 419 MK_AudioLimitConfig_Rq 3;
BA_ "U_V710_MY2023_Rx" SG_ 419 MK_ACSRestrictConf_Rq 1;
BA_ "U_P708_MY2023_Rx" SG_ 419 MK_ACSRestrictConf_Rq 1;
BA_ "U_V713AV_MY2022_Rx" SG_ 419 MK_ACSRestrictConf_Rq 1;
BA_ "U_V713N_MY2022_Rx" SG_ 419 MK_ACSRestrictConf_Rq 1;
BA_ "GenSigSendType" SG_ 419 MK_ACSRestrictConf_Rq 3;
BA_ "U_P708_MY2023_Rx" SG_ 542 LocationServices_3 1;
BA_ "U_V713AV_MY2022_Rx" SG_ 542 LocationServices_3 1;
BA_ "U_V713N_MY2022_Rx" SG_ 542 LocationServices_3 1;
VAL_ 493 Dsp_StatLiScanCancel_Rq 1 "Cancel" 0 "Inactive" ;
VAL_ 493 Dsp_StationList_Rq 15 "reserved_last" 8 "reserved" 7 "DAB_Service_List" 6 "DAB_Ensemble_Service_List" 5 "Analog_FM_PTY_List" 4 "Analog_and_HD_FM_List" 3 "HD_FM_List" 2 "Analog_FM_List" 1 "Analog_AM_List" 0 "Inactive" ;
VAL_ 493 Dsp_RefreshFlag 1 "True" 0 "False" ;
VAL_ 493 Dsp_AFJump_Rq 2 "Enable" 1 "Inhibit" 0 "Inactive" ;
VAL_ 511 Dsp_TUPresetArea_Rq 13 "reserved" 12 "GetSAT3PresetData" 11 "GetSAT2PresetData" 15 "reserved_last" 10 "GetSAT1PresetData" 9 "GetDAB2PresetData" 8 "GetDAB1PresetData" 7 "GetDAB3PresetData" 6 "GetAmPresetData" 5 "GetAmAstPresetData" 4 "GetFmAstPresetData" 3 "GetFm3PresetData" 2 "GetFm2PresetData" 1 "GetFm1PresetData" 0 "Inactive" ;
VAL_ 511 Dsp_SetCurrTUBand_Rq 13 "reserved1" 12 "DAB3" 11 "SAT3" 10 "SAT2" 15 "reserved_last" 9 "SAT1" 8 "DAB2" 7 "DAB1" 6 "AmAst" 5 "Am" 4 "FmAst" 3 "Fm3" 2 "Fm2" 1 "Fm1" 0 "Inactive" ;
VAL_ 511 SdarsAudioRtng_D_Rq 3 "NotUsed" 2 "APIMStereoOut" 1 "X40l2SStereoOut" 0 "Null" ;
VAL_ 257 MFD_SetTagMode 2 "On" 1 "Off" 0 "Inactive" ;
VAL_ 257 MFD_SetRBDSMode 2 "On" 1 "Off" 0 "Inactive" ;
VAL_ 257 MFD_SetHDModeRq 2 "On" 1 "Off" 0 "Inactive" ;
VAL_ 257 MFD_GetTagInfo 1 "TagInformation" 0 "Inactive" ;
VAL_ 972 LatCtlSte_D_Stat 7 "NotUsed3" 6 "NotUsed2" 5 "NotUsed1" 4 "Denied" 3 "RampOut" 2 "ContLatControlInProgress" 1 "Available" 0 "Unavailable" ;
VAL_ 972 LatCtlLim_D_Stat 3 "LimitWithDriverActive" 2 "LimitReached" 1 "LimitClose" 0 "LimitNotReached" ;
VAL_ 972 LatCtlCpblty_D_Stat 3 "Faulty" 2 "ExtendedModeAvailable" 1 "LimitedModeAvailable" 0 "NoModeAvailable" ;
VAL_ 972 LsmcBrkDecelEnbl_D_Rq 3 "NotUsed2" 2 "NotUsed1" 1 "On" 0 "Off" ;
VAL_ 972 TjaHandsOnCnfdnc_B_Est 1 "High_Confidence" 0 "Low_Confidence" ;
VAL_ 972 LaHandsOff_B_Actl 1 "Hands_Off" 0 "Hands_On" ;
VAL_ 972 LaActDeny_B_Actl 1 "LA_Denied" 0 "LA_Not_Denied" ;
VAL_ 972 LaActAvail_D2_Actl 3 "Intervention_Available" 2 "NoIntervention_Available" 1 "Intervention_NotAvailable" 0 "NoIntervention_NotAvailabl" ;
VAL_ 1120 StabBarCnncButtn_D_Stat 3 "Faulty" 2 "NotUsed" 1 "Pressed" 0 "Not_Pressed" ;
VAL_ 1120 DrvSlipCtlMde_B_Rq3 1 "Pressed" 0 "Not_Pressed" ;
VAL_ 1120 HybMdeSwtch_B_Rq 1 "Pressed" 0 "Not_Pressed" ;
VAL_ 1120 FrontDiffLck_D_RqDrv 3 "Faulty" 2 "NoRequest" 1 "On" 0 "Off" ;
VAL_ 1120 AwdLck_D_RqDrv 3 "Faulty" 2 "NoRequest" 1 "On" 0 "Off" ;
VAL_ 1120 TrailCtlSwtch_B_Stat3 1 "Pressed" 0 "Not_Pressed" ;
VAL_ 1120 RearDiffLck_D_RqDrv 3 "Faulty" 2 "NoRequest" 1 "On" 0 "Off" ;
VAL_ 1120 AwdMde_D_RqDrv 7 "Faulty" 6 "NotUsed2" 5 "NoRequest" 4 "Neutral" 3 "FourByFourLow" 2 "FourByFourHigh" 1 "FourByFourAuto" 0 "FourByTwo" ;
VAL_ 1120 HdcSwtchPos_B_Actl 1 "Pressed" 0 "Not_Pressed" ;
VAL_ 1087 DcacFaltMsgTxt_D2_Rq 35 "NotUsed_1" 34 "FrontTrnkPlgWarnDertExceed" 33 "FrontTrnkPlgWarnDerate" 32 "FrontTrnkPlgWarnFullPw" 31 "IpcPlugWarnDrive" 30 "DcacbOvercurrentLp" 29 "DcacbService" 28 "DcacbNotAvailable" 27 "DcacbAcOnOutput" 26 "DcacbTemperature" 25 "DcacbGfci" 24 "DcacbOvercurrent" 23 "PpoUsageWhenVehlsCharging" 22 "RpsNewKeyCycleWarning" 21 "LowSocRpsWarning" 20 "RpsResetWarn_ChngDrvToPark" 19 "RpsResetWarning" 18 "FirstRpsWarning" 63 "NotUsed_29" 17 "PowerTakeoff" 16 "HevDerate" 15 "HvacOn" 14 "OvercurrentLP" 13 "EngineRun" 12 "Service" 11 "NotAvailable" 10 "PlugWarn" 9 "PlugWarnDrive" 8 "BreakerC" 7 "BreakerB" 6 "BreakerA" 5 "FuelLow" 4 "AcOnOutput" 3 "Temperature" 2 "Gfci" 1 "Overcurrent" 0 "Ok" ;
VAL_ 1087 StopStrtCstm_D_Stat 3 "Faulty" 2 "On" 1 "Off" 0 "NotAvailable" ;
VAL_ 1087 SelDrvMdeCstmPt_D_Stat 31 "Faulty" 30 "NotUsed15" 29 "NotUsed14" 28 "NotUsed13" 27 "NotUsed12" 26 "NotUsed11" 25 "NotUsed10" 24 "NotUsed9" 23 "NotUsed8" 22 "NotUsed7" 21 "CustomMode" 20 "TrackMode" 19 "OnePedalDrive" 18 "EvLaterChargerMode" 17 "EvNowMode" 16 "DragMode" 15 "HighSpeedDesertMode_Baja" 14 "SportAdaptiveMode" 13 "NotAvailable_13" 12 "NotAvailable_12" 11 "NotAvailable_11" 10 "NotAvailable_10" 9 "RockCrawlMode" 8 "MudRutsMode" 7 "SandMode" 6 "EconomyMode" 5 "GrassGravelSnow" 4 "NotAvailable_04" 3 "TowHaulMode" 2 "NotAvailable_02" 1 "SportMode" 0 "NormalMode" ;
VAL_ 1087 RepaLcGrdInhbt_B_Stat 1 "Yes" 0 "No" ;
VAL_ 1087 ClimtCool_D_RqPt 3 "NotUsed_2" 2 "NotUsed_1" 1 "On" 0 "Off" ;
VAL_ 1087 StrtInGearMsgTxt_D_Rq 15 "Message15" 14 "Message14" 13 "Message13" 12 "Message12" 11 "Message11" 10 "Message10" 9 "Message9" 8 "Message8" 7 "Message7" 6 "Message6" 5 "Message5" 4 "Message4" 3 "Message3" 2 "Message2" 1 "Message1" 0 "NoMessage" ;
VAL_ 1087 IgnOffInhbt_B_Stat 1 "Yes" 0 "No" ;
VAL_ 1087 BtsiShifInhbt_B_RqPt 1 "Yes" 0 "No" ;
VAL_ 1087 FapLcInhbt_B_Rq 1 "Yes" 0 "No" ;
VAL_ 1087 FapLcStopHold_B_Rq 1 "Yes" 0 "No" ;
VAL_ 1087 FapLcPrchgBrk_B_Rq 1 "Yes" 0 "No" ;
VAL_ 1087 FapLcObstcl_B_Stat 1 "Yes" 0 "No" ;
VAL_ 1087 FapLcMaxGrdInhbt_B_Stat 1 "Yes" 0 "No" ;
VAL_ 1087 FapLcMaxGrdAbrt_B_Stat 1 "Yes" 0 "No" ;
VAL_ 1087 FapLcActv_B_Stat 1 "Yes" 0 "No" ;
VAL_ 1087 BattRgenLoDChrg_D_RqEng 3 "Disable" 2 "Retain" 1 "Closed" 0 "Open" ;
VAL_ 1087 BattRgenLoChrg_D_RqEng 3 "Disable" 2 "Retain" 1 "Closed" 0 "Open" ;
VAL_ 1087 AdasLcObtclAbrt_B_Stat 1 "Yes" 0 "No" ;
VAL_ 1087 AirDamPos_D_Stat 3 "Faulty" 2 "NotUsed" 1 "Down" 0 "Up" ;
VAL_ 787 PwTgateInhbtMsgTxt_B_Rq 1 "DisplayMessage" 0 "NoMessage" ;
VAL_ 787 PwTgateStepMsgTxt_B_Rq 1 "DisplayMessage" 0 "NoMessage" ;
VAL_ 787 PwTgateMsgTxt_B_Rq 1 "DisplayMessage" 0 "NoMessage" ;
VAL_ 787 PwTgateLamp_B_Rq 1 "On" 0 "Off" ;
VAL_ 787 DrTgateChime2_D_Rq 7 "NotUsed3" 6 "NotUsed2" 5 "NotUsed1" 4 "Long_Repeated" 3 "Fast" 2 "Short" 1 "Long" 0 "Off" ;
VAL_ 787 DrTGate_D_Rq 3 "NotUsed" 2 "Closing" 1 "Opening" 0 "Not_Moving" ;
VAL_ 787 PwLftgtIntSw_B_Stat 1 "Pressed" 0 "Null" ;
VAL_ 787 Power_Liftgate_Mode_Stt 2 "Unused" 3 "Not_Supported" 1 "Enabled" 0 "Disabled" ;
VAL_ 819 WndwUpPsngrRear_D_Falt 3 "NotUsed" 2 "Fault" 1 "NoFault" 0 "Null" ;
VAL_ 819 WndwUpPsngrFront_D_Falt 3 "NotUsed" 2 "Fault" 1 "NoFault" 0 "Null" ;
VAL_ 819 DrPrsntPsngr_D_Stat 3 "Faulty" 2 "Present" 1 "NotPresent" 0 "NotDetermined" ;
VAL_ 819 DrPsngrMsgTxt_B_Rq 1 "Yes" 0 "No" ;
VAL_ 819 DrPrsntRearPsngr_D_Stat 3 "Faulty" 2 "Present" 1 "NotPresent" 0 "NotDetermined" ;
VAL_ 819 Memory_3_SwPsngr_Stat 1 "Pressed" 0 "Null" ;
VAL_ 819 Memory_2_SwPsngr_Stat 1 "Pressed" 0 "Null" ;
VAL_ 819 Memory_1_SwPsngr_Stat 1 "Pressed" 0 "Null" ;
VAL_ 819 BLISLEDStatPassSide 3 "Fault" 2 "Unused" 1 "On" 0 "Off" ;
VAL_ 819 WndwPsngrSide_D_Stat 3 "BothWindow_Operating" 2 "RearWindow_Operating" 1 "FrontWindow_Operating" 0 "NoWindows_Operating" ;
VAL_ 819 Pasngr_Lock_Sw_Stat 3 "Invalid" 2 "Unlock" 1 "Lock" 0 "Null" ;
VAL_ 819 ChildLckFdbckRp_B_Stat 1 "Locked" 0 "Unlock" ;
VAL_ 818 WndwUpDrvRear_D_Falt 3 "NotUsed" 2 "Fault" 1 "NoFault" 0 "Null" ;
VAL_ 818 WndwUpDrvFront_D_Falt 3 "NotUsed" 2 "Fault" 1 "NoFault" 0 "Null" ;
VAL_ 818 DrvSpotLight_B_Stat 1 "Active" 0 "Inactive" ;
VAL_ 818 DrPrsntDrv_D_Stat 3 "Faulty" 2 "Present" 1 "NotPresent" 0 "NotDetermined" ;
VAL_ 818 DrPrsntRearDrv_D_Stat 3 "Faulty" 2 "Present" 1 "NotPresent" 0 "NotDetermined" ;
VAL_ 818 DrDrvMsgTxt_B_Rq 1 "Yes" 0 "No" ;
VAL_ 818 BLISLEDStatDriverSide 3 "Fault" 2 "Unused" 1 "On" 0 "Off" ;
VAL_ 818 WndwDrvSide_D_Stat 3 "BothWindow_Operating" 2 "RearWindow_Operating" 1 "FrontWindow_Operating" 0 "NoWindows_Operating" ;
VAL_ 818 KeyCylSwDrvDr_D_Stat 3 "NotUsed" 2 "Unlock" 1 "Lock" 0 "Null" ;
VAL_ 818 Driver_Lock_Sw_Stat 3 "Invalid" 2 "Unlock" 1 "Lock" 0 "Null" ;
VAL_ 818 ChildLckPw_D_Rq 1 "Active" 0 "Null" ;
VAL_ 818 ChildLckFdbckRd_B_Stat 1 "Locked" 0 "Unlock" ;
VAL_ 818 RvrseMirrorChime_B_Rq 1 "Yes" 0 "No" ;
VAL_ 1164 DrHandleInnrFr_B_Stat 1 "Pulled" 0 "AtRest" ;
VAL_ 1164 DrLatchLckFr_B_Stat 1 "Locked" 0 "Unlock" ;
VAL_ 1164 DrLatchFrMsgTxt_D_Rq 7 "Message7" 6 "Message6" 5 "Message5" 4 "Message4" 3 "Message3" 2 "Message2" 1 "Message1" 0 "NoMessage" ;
VAL_ 1164 DrLatchFr_B_Falt 1 "Yes" 0 "No" ;
VAL_ 1163 DrHandleInnrFl_B_Stat 1 "Pulled" 0 "AtRest" ;
VAL_ 1163 DrLatchLckFl_B_Stat 1 "Locked" 0 "Unlock" ;
VAL_ 1163 DrLatchFlMsgTxt_D_Rq 7 "Message7" 6 "Message6" 5 "Message5" 4 "Message4" 3 "Message3" 2 "Message2" 1 "Message1" 0 "NoMessage" ;
VAL_ 1163 DrLatchFl_B_Falt 1 "Yes" 0 "No" ;
VAL_ 1166 DrHandleInnrRr_B_Stat 1 "Pulled" 0 "AtRest" ;
VAL_ 1166 DrLatchRrMsgTxt_D_Rq 7 "Message7" 6 "Message6" 5 "Message5" 4 "Message4" 3 "Message3" 2 "Message2" 1 "Message1" 0 "NoMessage" ;
VAL_ 1166 DrLatchRr_B_Falt 1 "Yes" 0 "No" ;
VAL_ 1166 DrLatchLckRr_B_Stat 1 "Locked" 0 "Unlock" ;
VAL_ 1166 ChildLckFdbckRr_B_Stat 1 "Locked" 0 "Unlock" ;
VAL_ 1165 DrLatchRlMsgTxt_D_Rq 7 "Message7" 6 "Message6" 5 "Message5" 4 "Message4" 3 "Message3" 2 "Message2" 1 "Message1" 0 "NoMessage" ;
VAL_ 1165 DrLatchRl_B_Falt 1 "Yes" 0 "No" ;
VAL_ 1165 DrLatchLckRl_B_Stat 1 "Locked" 0 "Unlock" ;
VAL_ 1165 ChildLckFdbckRl_B_Stat 1 "Locked" 0 "Unlock" ;
VAL_ 1165 DrHandleInnrRl_B_Stat 1 "Pulled" 0 "AtRest" ;
VAL_ 556 Manual_Temp_Setting 31 "Full_Heat" 30 "Setting_30" 29 "Setting_29" 28 "Setting_28" 27 "Setting_27" 26 "Setting_26" 25 "Setting_25" 24 "Setting_24" 23 "Setting_23" 22 "Setting_22" 21 "Setting_21" 20 "Setting_20" 19 "Setting_19" 18 "Setting_18" 17 "Setting_17" 16 "Setting_16" 15 "Setting_15" 14 "Setting_14" 13 "Setting_13" 12 "Setting_12" 11 "Setting_11" 10 "Setting_10" 9 "Setting_9" 8 "Setting_8" 7 "Setting_7" 6 "Setting_6" 5 "Setting_5" 4 "Setting_4" 3 "Setting_3" 2 "Setting_2" 1 "Full_Cool" 0 "Off" ;
VAL_ 556 DrvAsstMnuButtn_B_Stat 1 "Pressed" 0 "Not_Pressed" ;
VAL_ 556 EFP_Bezel_Diag_St 15 "Reserved" 3 "CalibrationPartNumber" 2 "HardwarePartNumber" 1 "SoftwarePartNumber" 0 "Inactive_NOP" ;
VAL_ 556 Bezel_Beeps_Supported 2 "Not_Supported" 1 "Supported" 0 "Invalid" ;
VAL_ 556 Bezel_Beep_St 0 "Invalid" 2 "Disabled" 1 "Enabled" ;
VAL_ 556 PassRstrnInd_Stat 7 "Invalid" 6 "Unused_2" 5 "Unused_1" 4 "Both_Indicators_Faulted" 3 "AirbagOff_Indicator_fault" 2 "AirbagOn_Indicator_fault" 1 "Normal" 0 "Not_Supported" ;
VAL_ 1101 AwdLckLamp_D_Rq 3 "Triggered" 2 "Flash" 1 "On" 0 "Off" ;
VAL_ 1101 Ptu_Te_Actl 255 "Faulty" ;
VAL_ 1101 PtLatchActv_B_RqAwd 1 "Yes" 0 "No" ;
VAL_ 1101 PtuFanOn_B_Rq 1 "On" 0 "Off" ;
VAL_ 1101 RearDiffLckLamp_D_Rq3 3 "Triggered" 2 "Flash" 1 "On" 0 "Off" ;
VAL_ 130 TrlrHitchLamp_D_Rqst 1 "On" 0 "Off" ;
VAL_ 130 VehVTrlrAid_B_Rq 1 "Request" 0 "NoRequest" ;
VAL_ 130 SteEffort_D_Stat 7 "NotUsed_3" 6 "NotUsed_2" 5 "NotUsed_1" 4 "SpecialMode_2" 3 "SpecialMode_1" 2 "Comfort" 1 "Sport" 0 "Normal" ;
VAL_ 130 DrvSteActv_B_Stat 1 "Active" 0 "Inactive" ;
VAL_ 130 DrvSte_Tq_Actl 255 "Invalid" 254 "Unknown" ;
VAL_ 130 SteMdule_D_Stat 7 "NotUsed" 6 "EPAS_Failure3" 5 "EPAS_Failure2" 4 "System_Failure" 3 "EPAS_Shutdown" 2 "Normal_Op_Full_Assist" 1 "Normal_Op_Limited_Assist" 0 "EPAS_Initialization" ;
VAL_ 130 SteMdule_U_Meas 255 "Invalid" ;
VAL_ 130 SteMdule_I_Est 4095 "Invalid" ;
VAL_ 130 EPAS_Failure 3 "SERVICE_POWER_STEERING_NOW" 2 "SERVICE_POWER_STEERING" 1 "POWER_STRG_ASSIST_FAULT" 0 "EPAS_OK_NO_MESSAGE" ;
VAL_ 130 SteeringColumnTorque 255 "Invalid" 254 "Unknown" ;
VAL_ 130 SAPPAngleControlStat6 1 "RequestedAngleNotReached" 0 "RequestedAngleCanBeReached" ;
VAL_ 130 SAPPAngleControlStat5 1 "StrgColTorqueExceed_EAROn" 0 "ExternalSigContentOKforEAC" ;
VAL_ 130 SAPPAngleControlStat4 1 "SpeedLimitExceededEAROn" 0 "ExternalSigContentOKforEAC" ;
VAL_ 130 SAPPAngleControlStat3 1 "EARactiveNoReverseEngage" 0 "ExternalSigContentOKforEAC" ;
VAL_ 130 SAPPAngleControlStat2 1 "Rel_ExtSteeringAngleReqx" 0 "NoRel_ExtSteeringAngleReqx" ;
VAL_ 130 SAPPAngleControlStat1 3 "Fault" 2 "Active" 1 "Open" 0 "Closed" ;
VAL_ 382 EngIdlShutDown_D2_Type 3 "Fleet" 2 "Keyless" 1 "Keyed" 0 "Null" ;
VAL_ 382 DcacOut2_Pw2_Dsply 8191 "Faulty" 8190 "NoDataExists" ;
VAL_ 382 DcacOut1_Pw2_Dsply 8191 "Faulty" 8190 "NoDataExists" ;
VAL_ 382 EngMnfldChrg_Te_Actl 127 "Faulty" 126 "NoDataExists" ;
VAL_ 382 EngInnrClnt_Te_Actl 127 "Faulty" 126 "NoDataExists" ;
VAL_ 877 Manual_Temp_Setting2 31 "Full_Heat" 30 "Setting_30" 29 "Setting_29" 28 "Setting_28" 27 "Setting_27" 26 "Setting_26" 25 "Setting_25" 24 "Setting_24" 23 "Setting_23" 22 "Setting_22" 21 "Setting_21" 20 "Setting_20" 19 "Setting_19" 18 "Setting_18" 17 "Setting_17" 16 "Setting_16" 15 "Setting_15" 14 "Setting_14" 13 "Setting_13" 12 "Setting_12" 11 "Setting_11" 10 "Setting_10" 9 "Setting_9" 8 "Setting_8" 7 "Setting_7" 6 "Setting_6" 5 "Setting_5" 4 "Setting_4" 3 "Setting_3" 2 "Setting_2" 1 "Full_Cool" 0 "Off" ;
VAL_ 877 CabnAmb_Te_ActlAft 255 "Faulty" ;
VAL_ 877 RstrtClimtSet_B_Actv 1 "Active" 0 "Inactive" ;
VAL_ 877 Rr_Third_Power_Btn_Stt 3 "Unused" 2 "Disabled" 1 "Active" 0 "Enabled_Inactive" ;
VAL_ 877 Rr_Third_Floor_Btn_Stt 3 "Unused" 2 "Disabled" 1 "Active" 0 "Enabled_Inactive" ;
VAL_ 877 Rr_Third_Auto_Btn_Stt 3 "Unused" 2 "Disabled" 1 "Active" 0 "Enabled_Inactive" ;
VAL_ 877 Rr_Lock_Btn_Stt 3 "Unused" 2 "Disabled" 1 "Active" 0 "Enabled_Inactive" ;
VAL_ 877 Rr_RHS_Blower_Indicate 15 "Display_Blank" 14 "14_Indicators_On" 13 "13_Indicators_On" 12 "12_Indicators_On" 11 "11_Indicators_On" 10 "10_Indicators_On" 9 "9_Indicators_On" 8 "8_Indicators_On" 7 "7_Indicators_On" 6 "6_Indicators_On" 5 "5_Indicators_On" 4 "4_Indicators_On" 3 "3_Indicators_On" 2 "2_Indicators_On" 1 "1_Indicator_On" 0 "Indicators_Off" ;
VAL_ 877 Rr_Third_Panel_Btn_Stt 3 "Unused" 2 "Disabled" 1 "Active" 0 "Enabled_Inactive" ;
VAL_ 877 Rr_Synch_Btn_Stt 3 "Unused" 2 "Disabled" 1 "Active" 0 "Enabled_Inactive" ;
VAL_ 877 AAR_Btn_Stt 3 "Unused" 2 "Disabled" 1 "Active" 0 "Enabled_Inactive" ;
VAL_ 877 Heat_Btn_Stt 3 "Unused" 2 "Disabled" 1 "Active" 0 "Enabled_Inactive" ;
VAL_ 414 LBS2_ListStatus 0 "Inactive" 1 "Valid" 2 "Updating" 3 "Reserved" ;
VAL_ 619 KeyPadCodeProg_D_Rq 7 "NotUsed_3" 6 "NotUsed_2" 5 "NotUsed_1" 4 "DeleteAll" 3 "Delete" 2 "Add" 1 "ProgrammingMode" 0 "Null" ;
VAL_ 619 PaakCnnct_D_Stat 3 "NotUsed" 2 "Connected" 1 "NotConnected" 0 "Null" ;
VAL_ 619 PaakCtlActv_D_Rq 31 "NotUsed_13" 30 "NotUsed_12" 29 "NotUsed_11" 28 "NotUsed_10" 27 "NotUsed_9" 26 "NotUsed_8" 25 "NotUsed_7" 24 "NotUsed_6" 23 "NotUsed_5" 22 "NotUsed_4" 21 "NotUsed_3" 20 "TrunkFrontRelease" 19 "RemoteStop" 18 "RemoteStart" 17 "PowerDecklid" 16 "RightPowerSlidingDoor" 15 "LeftPowerSlidingDoor" 14 "PowerLiftgate" 13 "GlobalClose" 12 "GlobalOpen" 11 "PanicOff" 10 "PanicOn" 9 "LiftgateGlassRelease" 8 "LiftgateRelease" 7 "DecklidRelease" 6 "DoubleLock" 5 "LockAll" 4 "UnlockAllDoorsPlusCargo" 3 "UnlockCargoDoor" 2 "UnlockAllDoors" 1 "UnlockDriverDoor" 0 "Null" ;
VAL_ 953 PaakMyKeySearch_D_Stat 7 "PhoneErased" 6 "LockButtonTimeOut" 5 "PressLockButton" 4 "ConfirmHmi" 3 "MyKeyPaakFound" 2 "StandardPaakFound" 1 "NoValidPaakFound" 0 "Null" ;
VAL_ 953 BattULoChrgHyb_D_Stat 7 "NotUsed_4" 6 "NotUsed_3" 5 "NotUsed_2" 4 "NotUsed_1" 3 "VehicleServiceRequired" 2 "EvRangeLossDueToLoadActive" 1 "BatteryServiceRequired" 0 "Null" ;
VAL_ 953 BattULoChrgHyb_B_Rq 1 "True" 0 "False" ;
VAL_ 953 ChrgCordLck_B_Stat 1 "Unlock" 0 "Null" ;
VAL_ 953 WakeAlarm3_D_Stat 3 "PublisherReset" 2 "Wake" 1 "AlarmRunning" 0 "AlarmOff" ;
VAL_ 953 WakeAlarm2_D_Stat 3 "PublisherReset" 2 "Wake" 1 "AlarmRunning" 0 "AlarmOff" ;
VAL_ 953 WakeAlarm1_D_Stat 3 "PublisherReset" 2 "Wake" 1 "AlarmRunning" 0 "AlarmOff" ;
VAL_ 953 WakeAlarm0_D_Stat 3 "PublisherReset" 2 "Wake" 1 "AlarmRunning" 0 "AlarmOff" ;
VAL_ 953 BattRgenLoChrg_D_Rq 3 "DoNotCare" 2 "Retain" 1 "Closed" 0 "Open" ;
VAL_ 953 BattRgenLoDChrg_D_Rq 3 "DoNotCare" 2 "Retain" 1 "Closed" 0 "Open" ;
VAL_ 985 ClrExitAsst_D_Stat 3 "NotUsed" 2 "Enabled" 1 "Disabled" 0 "Null" ;
VAL_ 985 ClrExitAsstMsgTxt_D_Rq 15 "NotUsed_8" 14 "NotUsed_7" 13 "NotUsed_6" 12 "NotUsed_5" 11 "NotUsed_4" 10 "NotUsed_3" 9 "NotUsed_2" 8 "NotUsed_1" 7 "SystemFault" 6 "ChildLockMaintained" 5 "WarningRight" 4 "WarningLeft" 3 "InformationRight" 2 "InformationLeft" 1 "Shutdown" 0 "NoMessage" ;
VAL_ 985 ClrExitAsstChime_D_Rq 7 "NotUsed_4" 6 "NotUsed_3" 5 "NotUsed_2" 4 "NotUsed_1" 3 "WarningChimeFront" 2 "WarningChimeRear" 1 "InformationChime" 0 "Off" ;
VAL_ 985 AdbDrvSide_B_Stat 1 "Left_Hand_Traffic" 0 "Right_Hand_Traffic" ;
VAL_ 985 LcwaMsgTxt_D_Stat 3 "SodXFaulty" 2 "SodXBlocked" 1 "TrailerConnected" 0 "NoMessage" ;
VAL_ 985 AdbDividedRoad_B_Stat 1 "Yes" 0 "No" ;
VAL_ 985 IsaVLimUnit_D_Rq 3 "NoDataExists" 2 "Mph" 1 "Kph" 0 "Null" ;
VAL_ 985 SblmYieldScnr_B_Stat 1 "Yes" 0 "No" ;
VAL_ 985 SblmStopScnr_B_Stat 1 "Yes" 0 "No" ;
VAL_ 985 IsaVLim_D_Rq 252 "NotUsed_2" 250 "LimitSpeed_250" 240 "LimitSpeed_240" 230 "LimitSpeed_230" 220 "LimitSpeed_220" 210 "LimitSpeed_210" 200 "LimitSpeed_200" 190 "LimitSpeed_190" 150 "LimitSpeed_150" 140 "LimitSpeed_140" 130 "LimitSpeed_130" 120 "LimitSpeed_120" 110 "LimitSpeed_110" 100 "LimitSpeed_100" 90 "LimitSpeed_90" 80 "LimitSpeed_80" 70 "LimitSpeed_70" 60 "LimitSpeed_60" 50 "LimitSpeed_50" 40 "LimitSpeed_40" 30 "LimitSpeed_30" 20 "LimtSpeed_20" 251 "NotUsed_1" 255 "Faulty" 254 "NoDataExists" 253 "NotUsed_3" 180 "LimitSpeed_180" 179 "LimitSpeed_179" 178 "LimitSpeed_178" 177 "LimitSpeed_177" 176 "LimitSpeed_176" 175 "LimitSpeed_175" 174 "LimitSpeed_174" 173 "LimitSpeed_173" 172 "LimitSpeed_172" 171 "LimitSpeed_171" 170 "LimitSpeed_170" 169 "LimitSpeed_169" 168 "LimitSpeed_168" 167 "LimitSpeed_167" 166 "LimitSpeed_166" 165 "LimitSpeed_165" 164 "LimitSpeed_164" 163 "LimitSpeed_163" 162 "LimitSpeed_162" 161 "LimitSpeed_161" 160 "LimitSpeed_160" 15 "LimitSpeed_15" 14 "LimitSpeed_14" 13 "LimitSpeed_13" 12 "LimitSpeed_12" 11 "LimitSpeed_11" 10 "LimitSpeed_10" 9 "LimitSpeed_9" 8 "LimitSpeed_8" 7 "LimitSpeed_7" 6 "LimitSpeed_6" 5 "LimitSpeed_5" 4 "LimitSpeed_4" 3 "LimitSpeed_3" 2 "LimitSpeed_2" 1 "LimitSpeed_1" 0 "LimitSpeed_0" ;
VAL_ 985 IaccVLimUnit_D_Rq 3 "NoDataExists" 2 "Mph" 1 "Kph" 0 "Null" ;
VAL_ 985 IaccVLim_D_Rq 252 "NotUsed_2" 250 "LimitSpeed_250" 240 "LimitSpeed_240" 230 "LimitSpeed_230" 220 "LimitSpeed_220" 210 "LimitSpeed_210" 200 "LimitSpeed_200" 190 "LimitSpeed_190" 150 "LimitSpeed_150" 140 "LimitSpeed_140" 130 "LimitSpeed_130" 120 "LimitSpeed_120" 110 "LimitSpeed_110" 100 "LimitSpeed_100" 90 "LimitSpeed_90" 80 "LimitSpeed_80" 70 "LimitSpeed_70" 60 "LimitSpeed_60" 50 "LimitSpeed_50" 40 "LimitSpeed_40" 30 "LimitSpeed_30" 20 "LimtSpeed_20" 251 "NotUsed_1" 255 "Faulty" 254 "NoDataExists" 253 "NotUsed_3" 180 "LimitSpeed_180" 179 "LimitSpeed_179" 178 "LimitSpeed_178" 177 "LimitSpeed_177" 176 "LimitSpeed_176" 175 "LimitSpeed_175" 174 "LimitSpeed_174" 173 "LimitSpeed_173" 172 "LimitSpeed_172" 171 "LimitSpeed_171" 170 "LimitSpeed_170" 169 "LimitSpeed_169" 168 "LimitSpeed_168" 167 "LimitSpeed_167" 166 "LimitSpeed_166" 165 "LimitSpeed_165" 164 "LimitSpeed_164" 163 "LimitSpeed_163" 162 "LimitSpeed_162" 161 "LimitSpeed_161" 160 "LimitSpeed_160" 15 "LimitSpeed_15" 14 "LimitSpeed_14" 13 "LimitSpeed_13" 12 "LimitSpeed_12" 11 "LimitSpeed_11" 10 "LimitSpeed_10" 9 "LimitSpeed_9" 8 "LimitSpeed_8" 7 "LimitSpeed_7" 6 "LimitSpeed_6" 5 "LimitSpeed_5" 4 "LimitSpeed_4" 3 "LimitSpeed_3" 2 "LimitSpeed_2" 1 "LimitSpeed_1" 0 "LimitSpeed_0" ;
VAL_ 985 DasAlrtInfo_D_Dsply 3 "NotUsed" 2 "On" 1 "Off" 0 "Null" ;
VAL_ 985 SblmRndAbtScnr_B_Stat 1 "Yes" 0 "No" ;
VAL_ 985 LongCtrlEnbl_D_Rq 7 "Faulty" 6 "NotUsed_3" 5 "NotUsed_2" 4 "NotUsed_1" 3 "RemoteParking" 2 "Autohitch" 1 "AutomaticParking" 0 "None" ;
VAL_ 985 SblmPedCrossScnr_B_Stat 1 "Yes" 0 "No" ;
VAL_ 985 TsrRegionTxt_D_Stat 31 "Faulty" 30 "NotUsed_8" 29 "NotUsed_7" 28 "NotUsed_6" 27 "NotUsed_5" 26 "NotUsed_4" 25 "NotUsed_3" 24 "NotUsed_2" 23 "NotUsed_1" 22 "Region_22" 21 "Region_21" 20 "Region_20" 19 "Region_19" 18 "Region_18" 17 "Region_17" 16 "Region_16" 15 "Region_15" 14 "Region_14" 13 "Region_13" 12 "Region_12" 11 "Region_11" 10 "Region_10" 9 "Region_09" 8 "Region_08" 7 "Region_07" 6 "Region_06" 5 "Region_05" 4 "Region_04" 3 "Region_03" 2 "Region_02" 1 "Region_01" 0 "NotDetermined" ;
VAL_ 985 LdwChime_B_Rq 1 "On" 0 "Off" ;
VAL_ 985 PwSustnAdas_B_Rq 1 "Active" 0 "Inactive" ;
VAL_ 985 LongCtrlBrk_D_Rq 3 "NotUsed" 2 "LowDecel" 1 "HighDecel" 0 "NoRequest" ;
VAL_ 770 ScEnbl_B_Stat 1 "On" 0 "Off" ;
VAL_ 770 ScPayloadUpdate_B_Stat 3 "NotUsed" 2 "Complete" 1 "InProcess" 0 "Null" ;
VAL_ 770 ScChrgrPwMax_Pw_Actl 4095 "Faulty" ;
VAL_ 1013 ChrgToPcWkndSav_D_Stat 7 "Percent_50" 6 "Percent_60" 5 "Percent_70" 4 "Percent_80" 3 "Percent_85" 2 "Percent_90" 1 "Percent_95" 0 "Percent_100" ;
VAL_ 1013 ChrgToPcWkdySav_D_Stat 7 "Percent_50" 6 "Percent_60" 5 "Percent_70" 4 "Percent_80" 3 "Percent_85" 2 "Percent_90" 1 "Percent_95" 0 "Percent_100" ;
VAL_ 1013 ChrgNowEnbl_B_Saved 1 "On" 0 "Off" ;
VAL_ 1013 ChrgLocIdUnsAck_B_Stat 1 "Yes" 0 "No" ;
VAL_ 1012 ChrgLocSaved_B_Dsply 1 "Yes" 0 "No" ;
VAL_ 1012 AirCondRec_B_RqVehEl 1 "Yes" 0 "No" ;
VAL_ 1012 ChrgLocLongPostv_B_Sav 1 "Yes" 0 "No" ;
VAL_ 1012 ChrgLocLattPostv_B_Sav 1 "Yes" 0 "No" ;
VAL_ 1012 ChrgNowCurnt_B_Dsply 1 "On" 0 "Off" ;
VAL_ 1011 ChrgLocLongPostv_B_Uns 1 "Yes" 0 "No" ;
VAL_ 1011 ChrgLocLattPostv_B_Uns 1 "Yes" 0 "No" ;
VAL_ 1011 VehShutDownMsgTxt_D_Rq 3 "NotUsed" 2 "ProhibitedRestart" 1 "ShutdownWarning" 0 "NoMessage" ;
VAL_ 533 ClrExitAsstEnbl_D_RqMnu 3 "NotUsed" 0 "Inactive" 2 "Enable" 1 "Disable" ;
VAL_ 533 AutoEpbZoomView_B_Stat 1 "Active" 0 "Inactive" ;
VAL_ 533 PaakMyKey_D_Rq 3 "NotUsed" 2 "ConfirmNewPaakMyKey" 1 "RequestNewPaakMyKey" 0 "None" ;
VAL_ 533 DcacPw_D_Rq 3 "High" 2 "Low" 1 "Off" 0 "Null" ;
VAL_ 533 DcacPwReset_B_Rq 1 "Reset" 0 "Null" ;
VAL_ 533 AutoEpbButtn_B_Stat 1 "Pressed" 0 "Not_Pressed" ;
VAL_ 533 TrlrAidMde_D_Rq 3 "Mode_3" 2 "Mode_2" 1 "Mode_1" 0 "NoRequest" ;
VAL_ 533 TCU_Init_Actvtn_St 3 "NotUsed" 2 "InitialActivateDeny" 1 "InitialActivateAccept" 0 "Invalid" ;
VAL_ 533 TCU_Final_Actvtn_St 3 "NotUsed" 2 "FinalActivateDeny" 1 "FinalActivateAccept" 0 "Invalid" ;
VAL_ 533 LghtAmbDrvMde_D_Rq 3 "NotUsed" 2 "Automatic" 1 "Manual" 0 "Null" ;
VAL_ 533 OtaTrg_D_Stat 3 "NotUsed_1" 2 "Accepted" 1 "NotAccepted" 0 "Null" ;
VAL_ 533 DcacPwLoButtn_B_Stat 1 "Pressed" 0 "Not_Pressed" ;
VAL_ 533 DcacPwOffButtn_B_Stat 1 "Pressed" 0 "Not_Pressed" ;
VAL_ 533 DcacPwHiButtn_B_Stat 1 "Pressed" 0 "Not_Pressed" ;
VAL_ 533 DcacPwResetButtn_B_Stat 1 "Pressed" 0 "Not_Pressed" ;
VAL_ 533 DcacPwButtn_B_Falt 1 "Faulted" 0 "NotFaulted" ;
VAL_ 533 DcacMdeButtn_B_Stat 1 "Pressed" 0 "Not_Pressed" ;
VAL_ 533 OnbChrgGoTTouch_D_Rq 3 "NotUsed" 2 "On" 1 "Off" 0 "Null" ;
VAL_ 533 OnbChrgGoTPrcond_D_Rq 3 "High" 2 "Medium" 1 "Low" 0 "Off" ;
VAL_ 533 OnbChrgGoTOn_D_Rq 3 "NotUsed" 2 "On" 1 "Off" 0 "Null" ;
VAL_ 533 OnbChrgGoTMnte_D_Rq 15 "NotUsed_4" 14 "NotUsed_3" 13 "NotUsed_2" 12 "NotUsed_1" 11 "Minute_55" 10 "Minute_50" 9 "Minute_45" 8 "Minute_40" 7 "Minute_35" 6 "Minute_30" 5 "Minute_25" 4 "Minute_20" 3 "Minute_15" 2 "Minute_10" 1 "Minute_5" 0 "Minute_0" ;
VAL_ 533 OnbChrgGoTHr_T_Rq 31 "Faulty" 30 "NoDataExists" ;
VAL_ 533 OnbChrgGoTExtHtr_D_Rq 3 "NotUsed" 2 "On" 1 "Off" 0 "Null" ;
VAL_ 533 OnbChrgGoTDelete_B_Rq 1 "Request" 0 "NoRequest" ;
VAL_ 533 OnbChrgClearAll_B_Rq 1 "Request" 0 "NoRequest" ;
VAL_ 533 DcacGfciTestBttn_B_Stat 1 "Pressed" 0 "Not_Pressed" ;
VAL_ 533 OnbChrgGoTUpdate_B_Rq 1 "Request" 0 "NoRequest" ;
VAL_ 533 TrlrAlarmButtn_B_Stat 1 "On" 0 "Off" ;
VAL_ 533 DcacPwButtn_B_Stat 1 "Pressed" 0 "Not_Pressed" ;
VAL_ 533 TrlrHitch_D_RqMnu 15 "NotUsed_10" 14 "NotUsed_9" 13 "NotUsed_8" 12 "NotUsed_7" 11 "NotUsed_6" 10 "NotUsed_5" 9 "NotUsed_4" 8 "NotUsed_3" 7 "NotUsed_2" 6 "NotUsed_1" 5 "GoToTraileringDomain" 4 "Confirm" 3 "TurnOnTba" 2 "TurnOnAutohitch" 1 "CancelAutohitch" 0 "NoRequest" ;
VAL_ 801 CDWarnChime_St 1 "On" 0 "Off" ;
VAL_ 801 DrvDsplyPalette_D_Stat 7 "NotUsed_3" 6 "NotUsed_2" 5 "ManualNightDark" 4 "ManualNightBright" 3 "ManualDay" 2 "AutoNight" 1 "AutoDay" 0 "Null" ;
VAL_ 801 SoftWarning 1 "Chime_On" 0 "Chime_Off" ;
VAL_ 801 HardWarning 1 "Chime_On" 0 "Chime_Off" ;
VAL_ 801 InfoWarning 1 "Chime_On" 0 "Chime_Off" ;
VAL_ 878 ClimtSyncRear2_B_Stat 1 "Pressed" 0 "Not_Pressed" ;
VAL_ 878 ClimtStHeatRr2_B_Stat 1 "Pressed" 0 "Not_Pressed" ;
VAL_ 878 ClimtStHeatRl2_B_Stat 1 "Pressed" 0 "Not_Pressed" ;
VAL_ 878 ClimtStCoolRr2_B_Stat 1 "Pressed" 0 "Not_Pressed" ;
VAL_ 878 ClimtStCoolRl2_B_Stat 1 "Pressed" 0 "Not_Pressed" ;
VAL_ 878 ClimtSeatRr2_D_Rq 128 "H3_High_Heat_MAX" 64 "H2_Medium_Heat" 32 "H1_Low_Heat" 16 "C3_High_Cool_MAX" 8 "C2_Medium_Cool" 4 "C1_Low_Cool" 2 "Off" ;
VAL_ 878 ClimtSeatRl2_D_Rq 128 "H3_High_Heat_MAX" 64 "H2_Medium_Heat" 32 "H1_Low_Heat" 16 "C3_High_Cool_MAX" 8 "C2_Medium_Cool" 4 "C1_Low_Cool" 2 "Off" ;
VAL_ 878 ClimtRrTe3rd2_D_Stat 3 "NotUsed" 2 "Decrement" 1 "Increment" 0 "Inactive" ;
VAL_ 878 ClimtRrPw3rd2_B_Stat 1 "Pressed" 0 "Not_Pressed" ;
VAL_ 878 ClimtRrPnl3rd2_B_Stat 1 "Pressed" 0 "Not_Pressed" ;
VAL_ 878 ClimtRrPf3rd2_B_Stat 1 "Pressed" 0 "Not_Pressed" ;
VAL_ 878 ClimtRrFlr3rd2_B_Stat 1 "Pressed" 0 "Not_Pressed" ;
VAL_ 878 ClimtRrBlwr3rd2_D_Stat 3 "NotUsed" 2 "Decrement" 1 "Increment" 0 "Inactive" ;
VAL_ 878 ClimtRrAuto3rd2_B_Stat 1 "Pressed" 0 "Not_Pressed" ;
VAL_ 878 ClimtRearView2_D_Stat 3 "ThirdRow" 2 "SecondRow" 1 "Both" 0 "NotDisplayed" ;
VAL_ 878 ClimtRearTe2_D_Stat 3 "NotUsed" 2 "Decrement" 1 "Increment" 0 "Inactive" ;
VAL_ 878 ClimtRearTe2_An_Actl 511 "Faulty" ;
VAL_ 878 ClimtRearPw2_B_Stat 1 "Pressed" 0 "Not_Pressed" ;
VAL_ 878 ClimtRearPnlFlr2_B_Stat 1 "Pressed" 0 "Not_Pressed" ;
VAL_ 878 ClimtRearPnl2_B_Stat 1 "Pressed" 0 "Not_Pressed" ;
VAL_ 878 ClimtRearFlr2_B_Stat 1 "Pressed" 0 "Not_Pressed" ;
VAL_ 878 ClimtRearBlwr2_D_Stat 3 "NotUsed" 2 "Decrement" 1 "Increment" 0 "Inactive" ;
VAL_ 878 ClimtRearBlwr2_An_Actl 511 "Faulty" ;
VAL_ 878 ClimtRearAuto2_B_Stat 1 "Pressed" 0 "Not_Pressed" ;
VAL_ 259 SDARS_ChipControl_Rq 7 "NotUsed_4" 6 "NotUsed_3" 5 "NotUsed_2" 4 "NotUsed_1" 3 "Reset" 2 "PowerDown" 1 "PowerUp" 0 "Inactive" ;
VAL_ 259 SDARS_AlertStatus_Rq 2 "Disable" 1 "Enable" 0 "Inactive" ;
VAL_ 538 MK_SpeedMinderConf_St 31 "mph90" 30 "mph85" 29 "mph80" 28 "mph75" 27 "mph70" 26 "mph65" 25 "mph60" 24 "mph55" 23 "mph50" 22 "mph45" 21 "mph40" 20 "Kmh165" 19 "Kmh160" 18 "Kmh155" 17 "Kmh150" 16 "Kmh145" 15 "Kmh140" 14 "Kmh135" 13 "Kmh130" 12 "Kmh125" 11 "Kmh120" 10 "Kmh115" 9 "Kmh110" 8 "Kmh105" 7 "Kmh100" 6 "kmh95" 5 "kmh90" 4 "kmh85" 3 "kmh80" 2 "kmh75" 1 "kmh70" 0 "Off" ;
VAL_ 538 MK_SpeedLimitConf_St 31 "mph90" 30 "mph85" 29 "mph80" 28 "mph75" 27 "mph70" 26 "mph65" 25 "mph60" 24 "mph55" 23 "mph50" 22 "mph45" 21 "mph40" 20 "Kmh165" 19 "Kmh160" 18 "Kmh155" 17 "Kmh150" 16 "Kmh145" 15 "Kmh140" 14 "Kmh135" 13 "Kmh130" 12 "Kmh125" 11 "Kmh120" 10 "Kmh115" 9 "Kmh110" 8 "Kmh105" 7 "Kmh100" 6 "kmh95" 5 "kmh90" 4 "kmh85" 3 "kmh80" 2 "kmh75" 1 "kmh70" 0 "Off" ;
VAL_ 538 MK_ESCRestrictConf_St 3 "NotUsed" 2 "On" 1 "Off" 0 "Null" ;
VAL_ 538 MK_ECalRestrictConf_St 3 "NotUsed" 2 "On" 1 "Off" 0 "Null" ;
VAL_ 538 MK_DNDRestrictConf_St 3 "NotUsed" 2 "On" 1 "Off" 0 "Null" ;
VAL_ 538 MK_AudioLimitConfig_St 3 "NotUsed" 2 "On" 1 "Off" 0 "Null" ;
VAL_ 422 MK_UserMyKeyCount_Rsp 15 "Inactive" 14 "Unlimited" 13 "Thirteen" 12 "Twelve" 11 "Eleven" 10 "Ten" 9 "Nine" 8 "Eight" 7 "Seven" 6 "Six" 5 "Five" 4 "Four" 3 "Three" 2 "Two" 1 "One" 0 "Zero" ;
VAL_ 422 MK_CreateMyKey_Rsp 7 "NotUsed_3" 6 "NotUsed_2" 5 "NotUsed_1" 4 "Success" 3 "GenericFailure" 2 "NoKeyInSlot" 1 "KeyInSlotAlreadyMyKey" 0 "Inactive" ;
VAL_ 422 MK_AdminMyKeyCount_Rsp 15 "Inactive" 14 "Unlimited" 13 "Thirteen" 12 "Twelve" 11 "Eleven" 10 "Ten" 9 "Nine" 8 "Eight" 7 "Seven" 6 "Six" 5 "Five" 4 "Four" 3 "Three" 2 "Two" 1 "One" 0 "Zero" ;
VAL_ 1041 ElCmprPerfErr_D_Falt 3 "NotUsed" 2 "Pass" 1 "Fail" 0 "Not_Diagnose_Yet" ;
VAL_ 1041 ElCmprInnrErr_D_Falt 3 "NotUsed" 2 "Pass" 1 "Fail" 0 "Not_Diagnose_Yet" ;
VAL_ 1041 ElCmprLostComm_D_Falt 3 "NotUsed" 2 "Pass" 1 "Fail" 0 "Not_Diagnose_Yet" ;
VAL_ 1041 ElCmprOverLoad_D_Falt 3 "NotUsed" 2 "Pass" 1 "Fail" 0 "Not_Diagnose_Yet" ;
VAL_ 1041 ElCmprOverTe_D_Falt 3 "NotUsed" 2 "Pass" 1 "Fail" 0 "Not_Diagnose_Yet" ;
VAL_ 1041 ElCmprBattURng_D_Falt 3 "NotUsed" 2 "Pass" 1 "Fail" 0 "Not_Diagnose_Yet" ;
VAL_ 1041 ElCmprBattSysU_D_Falt 3 "NotUsed" 2 "Pass" 1 "Fail" 0 "Not_Diagnose_Yet" ;
VAL_ 1041 ElCmprSysU_D_Falt 3 "NotUsed" 2 "Pass" 1 "Fail" 0 "Not_Diagnose_Yet" ;
VAL_ 1041 ElCmprUHi_D_Stat 3 "Overvoltage" 2 "Undervoltage" 1 "InRange" 0 "Undetermined" ;
VAL_ 1041 ElCmprOverTe_D_Stat 3 "OverTempStop" 2 "OverTempWarning" 1 "Normal" 0 "Undefined" ;
VAL_ 1041 ElCmpr_N_Actl 255 "Invalid" ;
VAL_ 1041 ElCmpr_Pw_Actl 255 "Invalid" ;
VAL_ 1041 ElCmpr_D_Stat 7 "Signal_Invalid" 6 "Comp_Off_ActlSpd_Abnormal" 5 "Comp_Off_TrgtSpd_OutRange" 4 "Comp_Shutdown" 3 "Comp_Stopped_Self_Protect" 2 "Comp_Degraded" 1 "Comp_On" 0 "Comp_Off" ;
VAL_ 890 ActvNseMute_D_Rq 3 "NotUsed_1" 2 "Mute" 1 "Unmute" 0 "Inactive" ;
VAL_ 890 ActvNseAudio_D_Stat 3 "Audio_Off" 2 "Audio_Active" 1 "Audio_Standby" 0 "Invalid" ;
VAL_ 890 ActvNse_B_Actv 1 "Active" 0 "Inactive" ;
VAL_ 884 UltraFreshCabn_D_Stat 7 "NotUsed_2" 6 "NotUsed_1" 5 "NotSupported" 4 "Interrupted" 3 "Complete" 2 "Active" 1 "Inactive" 0 "Null" ;
VAL_ 884 PmSnsCabn_D_Stat 7 "NotUsed_1" 6 "IntermittentInhibit" 5 "NoIssue" 4 "BlankField" 3 "ReplaceSensor" 2 "CleanSensor" 1 "Unsupported" 0 "Initializing" ;
VAL_ 884 PmCabn_Conc_Actl 511 "Faulty" 510 "NoDataExists" ;
VAL_ 884 PmCabn20Mnte_Conc_Actl 511 "Faulty" 510 "NoDataExists" ;
VAL_ 884 PmCabn18Mnte_Conc_Actl 511 "Faulty" 510 "NoDataExists" ;
VAL_ 884 PmCabn16Mnte_Conc_Actl 511 "Faulty" 510 "NoDataExists" ;
VAL_ 884 PmCabn14Mnte_Conc_Actl 511 "Faulty" 510 "NoDataExists" ;
VAL_ 884 PmCabn12Mnte_Conc_Actl 511 "Faulty" 510 "NoDataExists" ;
VAL_ 883 PmCabn10Mnte_Conc_Actl 511 "Faulty" 510 "NoDataExists" ;
VAL_ 883 PmCabn08Mnte_Conc_Actl 511 "Faulty" 510 "NoDataExists" ;
VAL_ 883 PmCabn06Mnte_Conc_Actl 511 "Faulty" 510 "NoDataExists" ;
VAL_ 883 PmCabn04Mnte_Conc_Actl 511 "Faulty" 510 "NoDataExists" ;
VAL_ 883 PmCabn02Mnte_Conc_Actl 511 "Faulty" 510 "NoDataExists" ;
VAL_ 1090 VehElRnge_L_Dsply 4094 "NoDataExists" 4095 "Fault" ;
VAL_ 1090 Mtr2State_D_ActlMntr 7 "Faulty" 6 "NoDataExists" 5 "NotUsed_1" 4 "ReadinessState" 3 "DeactivationState" 2 "PowerGeneration" 1 "PowerConsumption" 0 "Null" ;
VAL_ 1090 Inv1Ain_I_ActlMntr 32767 "Faulty" 32766 "NoDataExists" ;
VAL_ 1090 HybVehMde_D_ActlMntr 7 "Faulty" 6 "NoDataExists" 5 "NotUsed_2" 4 "NotUsed_1" 3 "Fuel" 2 "HybridElectric" 1 "AllElectric" 0 "Null" ;
VAL_ 1090 ChrgStat_D_ActlMntr 7 "Faulty" 6 "NoDataExists" 5 "NotUsed" 4 "ChargingCompleted" 3 "NotCharging" 2 "ChargingInDrivingState" 1 "ChargingInParkingState" 0 "Null" ;
VAL_ 473 NAV_StorePreset2_Rq 31 "Reserved" 30 "Preset30" 29 "Preset29" 28 "Preset28" 27 "Preset27" 26 "Preset26" 25 "Preset25" 24 "Preset24" 23 "Preset23" 22 "Preset22" 21 "Preset21" 20 "Preset20" 19 "Preset19" 18 "Preset18" 17 "Preset17" 16 "Preset16" 15 "Preset15" 14 "Preset14" 13 "Preset13" 12 "Preset12" 11 "Preset11" 10 "Preset10" 9 "Preset9" 8 "Preset8" 7 "Preset7" 6 "Preset6" 5 "Preset5" 4 "Preset4" 3 "Preset3" 2 "Preset2" 1 "Preset1" 0 "Inactive" ;
VAL_ 473 NAV_SetAFMode_Rq 0 "Inactive" 1 "AfOn" 2 "AfOff" 3 "Auto" ;
VAL_ 473 NAV_StorePreset_Rq 10 "Preset10" 9 "Preset9" 8 "Preset8" 7 "Preset7" 0 "Inactive" 1 "Preset1" 2 "Preset2" 3 "Preset3" 4 "Preset4" 5 "Preset5" 6 "Preset6" ;
VAL_ 473 HMI_StorePreset2_Rq 31 "Reserved" 30 "Preset30" 29 "Preset29" 28 "Preset28" 27 "Preset27" 26 "Preset26" 25 "Preset25" 24 "Preset24" 23 "Preset23" 22 "Preset22" 21 "Preset21" 20 "Preset20" 19 "Preset19" 18 "Preset18" 17 "Preset17" 16 "Preset16" 15 "Preset15" 14 "Preset14" 13 "Preset13" 12 "Preset12" 11 "Preset11" 10 "Preset10" 9 "Preset9" 8 "Preset8" 7 "Preset7" 6 "Preset6" 5 "Preset5" 4 "Preset4" 3 "Preset3" 2 "Preset2" 1 "Preset1" 0 "Inactive" ;
VAL_ 473 NAV_SetTUServiceLink_Rq 3 "reserved" 2 "Inactive" 1 "Active" 0 "Invalid" ;
VAL_ 473 NAV_SetTAMode_Rq 0 "Inactive" 1 "TaLocalOn" 2 "TaDistantOn" 3 "TaOff" ;
VAL_ 473 NAV_SetReg_Rq 2 "On" 1 "Off" 0 "Inactive" ;
VAL_ 473 NAV_SelectPTYCodeSet_Rq 0 "Inactive" 1 "SetCode" ;
VAL_ 473 NAV_CDSetShuffle_Rq 0 "Inactive" 1 "On" 2 "Off" 3 "OnFolder" ;
VAL_ 473 NAV_CDSetRepeat_Rq 0 "Inactive" 1 "RepeatOnTrack" 2 "Off" 3 "OnFolder" ;
VAL_ 473 NAV_CDSetIntroScan_Rq 0 "Inactive" 1 "On" 2 "Off" 3 "OnFolder" ;
VAL_ 90 TrnGsmNtmState_D_Actl 3 "Faulty" 2 "Neutral_Tow_Mode" 1 "Car_Wash_Mode" 0 "None" ;
VAL_ 90 DrQltyDrv_D_StatGsm 7 "Faulty" 6 "NoDataExists" 5 "NotUsed2" 4 "NotUsed1" 3 "ClosedDegraded" 2 "OpenDegraded" 1 "ClosedOkay" 0 "OpenOkay" ;
VAL_ 90 TrnBtsiOvrrd_B_Stat 1 "Override" 0 "Null" ;
VAL_ 90 GsmGearMsgTxt_D_Rq 3 "Message3" 2 "Message2" 1 "Message1" 0 "NoMessage" ;
VAL_ 90 TrnRng_D_RqGsm 15 "Fault" 14 "UnknownPosition" 13 "Undefined_2" 12 "Undefined_1" 11 "_6" 10 "_5" 9 "_4" 8 "_3" 7 "_2" 6 "_1" 5 "Low" 4 "Sport_DriveSport" 3 "Drive" 2 "Neutral" 1 "Reverse" 0 "Park" ;
VAL_ 90 PrkBrkActv_D_RqGsmGear 3 "NotUsed" 2 "RequestParkBrakeEngage" 1 "NoRequest" 0 "Null" ;
VAL_ 90 TrnValidGearRq_D_Stat 3 "Valid_Request" 2 "Valid_Degraded_Request" 1 "Invalid_Request" 0 "No_Request" ;
VAL_ 90 TrnGearButtn_U_Actl 255 "Fault" ;
VAL_ 90 TrnGearButtn_B_ActlR2 1 "Yes" 0 "No" ;
VAL_ 90 TrnGearButtn_B_ActlR1 1 "Yes" 0 "No" ;
VAL_ 90 TrnGearButtn_B_ActlR0 1 "Yes" 0 "No" ;
VAL_ 90 TrnGearButtn_B_ActlP2 1 "Yes" 0 "No" ;
VAL_ 90 TrnGearButtn_B_ActlP1 1 "Yes" 0 "No" ;
VAL_ 90 TrnGearButtn_B_ActlP0 1 "Yes" 0 "No" ;
VAL_ 90 TrnGearButtn_B_ActlN2 1 "Yes" 0 "No" ;
VAL_ 90 TrnGearButtn_B_ActlN1 1 "Yes" 0 "No" ;
VAL_ 90 TrnGearButtn_B_ActlN0 1 "Yes" 0 "No" ;
VAL_ 90 TrnGearButtn_B_ActlM2 1 "Yes" 0 "No" ;
VAL_ 90 TrnGearButtn_B_ActlM1 1 "Yes" 0 "No" ;
VAL_ 90 TrnGearButtn_B_ActlM0 1 "Yes" 0 "No" ;
VAL_ 90 TrnGearButtn_B_ActlD2 1 "Yes" 0 "No" ;
VAL_ 90 TrnGearButtn_B_ActlD1 1 "Yes" 0 "No" ;
VAL_ 90 TrnGearButtn_B_ActlD0 1 "Yes" 0 "No" ;
VAL_ 90 TrnGear_D_RqDrv 31 "Fault" 30 "NotUsed_25" 29 "NotUsed_24" 28 "NotUsed_23" 27 "NotUsed_22" 26 "NotUsed_21" 25 "NotUsed_20" 24 "NotUsed_19" 23 "NotUsed_18" 22 "NotUsed_17" 21 "Return_To_Park" 20 "NotUsed_15" 19 "NotUsed_14" 18 "NotUsed_13" 17 "NotUsed_12" 16 "Manual" 15 "Not_Used11" 14 "Not_Used10" 13 "NotUsed_9" 12 "NotUsed_8" 11 "NotUsed_7" 10 "NotUsed_6" 9 "NotUsed_5" 8 "Drive" 7 "NotUsed_4" 6 "NotUsed_3" 5 "NotUsed_2" 4 "Neutral" 3 "NotUsed_1" 2 "Reverse" 1 "Park" 0 "No_Gear" ;
VAL_ 90 BrkSwtchPos_B_ActlGsm 1 "Yes" 0 "No" ;
VAL_ 1021 TrlrTireSensIRR_D_Stat 15 "NotSupported" 14 "NotUsed10" 13 "NotUsed9" 12 "NotUsed8" 11 "NotUsed7" 10 "NotUsed6" 9 "NotUsed5" 8 "NotUsed4" 7 "NotUsed3" 6 "NotUsed2" 5 "NotUsed1" 4 "Alert" 3 "Fault" 2 "Low" 1 "Normal" 0 "Unknown" ;
VAL_ 1021 TrlrTireSensIRM_D_Stat 15 "NotSupported" 14 "NotUsed10" 13 "NotUsed9" 12 "NotUsed8" 11 "NotUsed7" 10 "NotUsed6" 9 "NotUsed5" 8 "NotUsed4" 7 "NotUsed3" 6 "NotUsed2" 5 "NotUsed1" 4 "Alert" 3 "Fault" 2 "Low" 1 "Normal" 0 "Unknown" ;
VAL_ 1021 TrlrTireSensIRF_D_Stat 15 "NotSupported" 14 "NotUsed10" 13 "NotUsed9" 12 "NotUsed8" 11 "NotUsed7" 10 "NotUsed6" 9 "NotUsed5" 8 "NotUsed4" 7 "NotUsed3" 6 "NotUsed2" 5 "NotUsed1" 4 "Alert" 3 "Fault" 2 "Low" 1 "Normal" 0 "Unknown" ;
VAL_ 1021 TrlrTireIRR_P_Actl 65534 "Invalid" 65535 "NotSupported" ;
VAL_ 1021 TrlrTireIRM_P_Actl 65534 "Invalid" 65535 "NotSupported" ;
VAL_ 1021 TrlrTireIRF_P_Actl 65534 "Invalid" 65535 "NotSupported" ;
VAL_ 482 SDARS_Firm_Update2_St 0 "Invalid" 2 "Active" 1 "Inactive" ;
VAL_ 482 SDARS_UnSubscrb_Chan2_St 0 "Invalid" 2 "Active" 1 "Inactive" ;
VAL_ 482 SDARS_UnSubscrb2_St 0 "Invalid" 2 "Active" 1 "Inactive" ;
VAL_ 482 SDARS_Subscription2_St 0 "Invalid" 2 "Active" 1 "Inactive" ;
VAL_ 482 SDARS_Seek_Scan2_St 1 "NoChannelsAvailable" 0 "Invalid" ;
VAL_ 482 SDARS_Receive_Err2_St 0 "Invalid" 2 "Active" 1 "Inactive" ;
VAL_ 482 SDARS_Loss_Ant2_St 0 "Invalid" 2 "Active" 1 "Inactive" ;
VAL_ 482 SDARS_Invalid_Chan2_St 0 "Invalid" 2 "Active" 1 "Inactive" ;
VAL_ 482 SDARS_GCI_Update2_St 0 "Invalid" 2 "Active" 1 "Inactive" ;
VAL_ 482 SDARS_Error_Conf2_St 0 "Invalid" 2 "SDARS_OFF" 1 "SDARS_ON" ;
VAL_ 482 SDARS_Antenna_Err2_St 0 "Invalid" 2 "Active" 1 "Inactive" ;
VAL_ 764 SdarsSampleRate_D_Stat 3 "NotUsed_1" 2 "SampleRate_48000Hz" 1 "SampleRate_44100Hz" 0 "Null" ;
VAL_ 764 SdarsBaudRate_D_Stat 7 "NotUsed_3" 6 "NotUsed_2" 5 "NotUsed_1" 4 "BaudRate_460800bps" 3 "BaudRate_230400bps" 2 "BaudRate_115200bps" 1 "BaudRate_57600bps" 0 "Null" ;
VAL_ 764 SDARS_ChannelUpdate_St 3 "NotUsed_1" 2 "NewUpdatesAvailable" 1 "NoUpdates" 0 "Inactive" ;
VAL_ 764 SDARS_Channel_Lock2 0 "Invalid" 2 "Unlocked" 1 "Locked" ;
VAL_ 139 AccButtnGpTogglePress2 1 "Pressed" 0 "Not_Pressed" ;
VAL_ 139 TjaButtnOnOffPress2 1 "Pressed" 0 "Not_Pressed" ;
VAL_ 139 ActvFrontSteMsgTxt_D_Rq 7 "Message7" 6 "Message6" 5 "Message5" 4 "Message4" 3 "Message3" 2 "Message2" 1 "Message1" 0 "NoMessage" ;
VAL_ 139 ActvFrontSteLck_D_Stat 3 "Test_passed" 2 "Test_failed" 1 "Test_cannot_run" 0 "Test_incomplete" ;
VAL_ 139 SelDrvMdeAdptSte_D_Stat 3 "Faulty" 2 "TemporarilyNotAvailable" 1 "Available" 0 "NotAvailable" ;
VAL_ 139 AslButtnOnOffPress2 1 "Button_Pressed" 0 "Button_Not_Pressed" ;
VAL_ 139 AslButtnOnOffCnclPres2 1 "Button_Pressed" 0 "Button_Not_Pressed" ;
VAL_ 139 CcButtnOnPress2 1 "Button_Pressed" 0 "Button_Not_Pressed" ;
VAL_ 139 CcButtnOnOffPress2 1 "Button_Pressed" 0 "Button_Not_Pressed" ;
VAL_ 139 CcButtnOnOffCnclPress2 1 "Button_Pressed" 0 "Button_Not_Pressed" ;
VAL_ 139 CcButtnOffPress2 1 "Button_Pressed" 0 "Button_Not_Pressed" ;
VAL_ 139 CcAsllButtnResPress2 1 "Button_Pressed" 0 "Button_Not_Pressed" ;
VAL_ 139 CcAslButtnSetPress2 1 "Button_Pressed" 0 "Button_Not_Pressed" ;
VAL_ 139 CcAslButtnSetIncPress2 1 "Button_Pressed" 0 "Button_Not_Pressed" ;
VAL_ 139 CcAslButtnSetDecPress2 1 "Button_Pressed" 0 "Button_Not_Pressed" ;
VAL_ 139 CcAslButtnResIncPress2 1 "Button_Pressed" 0 "Button_Not_Pressed" ;
VAL_ 139 CcAslButtnResDecPress2 1 "Button_Pressed" 0 "Button_Not_Pressed" ;
VAL_ 139 CcAslButtnOnPress2 1 "Button_Pressed" 0 "Button_Not_Pressed" ;
VAL_ 139 CcAslButtnOnOffCncl2 1 "Button_Pressed" 0 "Button_Not_Pressed" ;
VAL_ 139 CcAslButtnOffCnclPres2 1 "Button_Pressed" 0 "Button_Not_Pressed" ;
VAL_ 139 CcAslButtnIndxIncPres2 1 "Button_Pressed" 0 "Button_Not_Pressed" ;
VAL_ 139 CcAslButtnIndxDecPres2 1 "Button_Pressed" 0 "Button_Not_Pressed" ;
VAL_ 139 CcAslButtnDeny_B_Actl2 1 "Yes" 0 "No" ;
VAL_ 139 CcAslButtnCnclResPres2 1 "Button_Pressed" 0 "Button_Not_Pressed" ;
VAL_ 139 CcAslButtnCnclPress2 1 "Button_Pressed" 0 "Button_Not_Pressed" ;
VAL_ 139 AccButtnGapIncPress2 1 "Button_Pressed" 0 "Button_Not_Pressed" ;
VAL_ 139 AccButtnGapDecPress2 1 "Button_Pressed" 0 "Button_Not_Pressed" ;
VAL_ 139 AfsPw_B_Rq 1 "Yes" 0 "No" ;
VAL_ 837 VehCurb_M_Actl 1023 "Faulty" 1022 "NoDataExists" ;
VAL_ 837 VehGvwr_M_Actl 1023 "Faulty" 1022 "NoDataExists" ;
VAL_ 837 VdmSustnActv_B_Rq 1 "Active" 0 "Inactive" ;
VAL_ 837 Ccd_B_Falt 1 "Yes" 0 "No" ;
VAL_ 837 SuspVLim_B_Rq 1 "True" 0 "False" ;
VAL_ 837 SelDrvMdeSusp_D_Stat 3 "Faulty" 2 "TemporarilyNotAvailable" 1 "Available" 0 "NotAvailable" ;
VAL_ 837 AdptDrvMdePt_D_Rq 7 "Faulty" 6 "NotUsed3" 5 "NotUsed2" 4 "NotUsed1" 3 "Powertrain2Sport" 2 "Powertrain2Normal" 1 "Powertrain2Comfort" 0 "AdaptiveNotActive" ;
VAL_ 837 AdptDrvMdeChassis_D_Rq 7 "Faulty" 6 "NotUsed3" 5 "NotUsed2" 4 "NotUsed1" 3 "Chassis2Sport" 2 "Chassis2Normal" 1 "Chassis2Comfort" 0 "AdaptiveNotActive" ;
VAL_ 837 AirSprngRateRr_D_Rq 3 "NoRequest" 2 "Firm" 1 "Medium" 0 "Soft" ;
VAL_ 837 AirSprngRateRl_D_Rq 3 "NoRequest" 2 "Firm" 1 "Medium" 0 "Soft" ;
VAL_ 837 SuspType_B_Stat 1 "Magnetic" 0 "NonMagnetic" ;
VAL_ 837 AirSprngRateFr_D_Rq 3 "NoRequest" 2 "Firm" 1 "Medium" 0 "Soft" ;
VAL_ 837 AirSprngRateFl_D_Rq 3 "NoRequest" 2 "Firm" 1 "Medium" 0 "Soft" ;
VAL_ 837 AirSusp_D_Stat 3 "NotUsed" 2 "On" 1 "Off" 0 "Null" ;
VAL_ 837 AirSuspMsgTxt_D_Rq 3 "NotUsed" 2 "Faulty" 1 "Override" 0 "NoMessage" ;
VAL_ 837 SuspDrvMde_D_Stat 7 "Faulty" 6 "NotUsed2" 5 "NotUsed1" 4 "Drag" 3 "Track" 2 "Snow_Wet" 1 "Sport" 0 "Normal" ;
VAL_ 837 CcdMsgTxt_D_RqDsply 15 "Unused8" 14 "Unused7" 13 "Unused6" 12 "Unused5" 11 "Unused4" 10 "Unused3" 9 "Unused2" 8 "StationaryMode" 7 "Mode_Change_Unavailable" 6 "CCD_Temporarily_Off" 5 "CCD_Service_Required" 4 "Faulty" 3 "Sport" 2 "Normal" 1 "Comfort" 0 "No_Mode_Selected" ;
VAL_ 146 VehVert2_A_Actl 8191 "Faulty" 8190 "NoDataExists" ;
VAL_ 146 VehLong2_A_Actl 8191 "Faulty" 8190 "NoDataExists" ;
VAL_ 146 VehLat2_A_Actl 8191 "Faulty" 8190 "NoDataExists" ;
VAL_ 146 VehVertAActl_D_Qf 3 "OK" 2 "Not_Within_Specifications" 1 "No_Data_Exists" 0 "Faulty" ;
VAL_ 146 VehLongAActl_D_Qf 3 "OK" 2 "Not_Within_Specifications" 1 "No_Data_Exists" 0 "Faulty" ;
VAL_ 146 VehLatAActl_D_Qf 3 "OK" 2 "Not_Within_Specifications" 1 "No_Data_Exists" 0 "Faulty" ;
VAL_ 925 VehElEffTrip_No_Dsply 127 "Faulty" 126 "NoDataExists" ;
VAL_ 925 TripSumDrvE_Pc_Dsply 1023 "Faulty" 1022 "NoDataExists" ;
VAL_ 925 TripExtFctrE_Pc_Dsply 1023 "Faulty" 1022 "NoDataExists" ;
VAL_ 925 TripClimE_Pc_Dsply 1023 "Faulty" 1022 "NoDataExists" ;
VAL_ 925 TripBattULoE_Pc_Dsply 1023 "Faulty" 1022 "NoDataExists" ;
VAL_ 501 Dsp_PresetArea_Rq 0 "Inactive" 1 "GetFm1PresetData" 2 "GetFm2PresetData" 3 "GetFm3PresetData" 4 "GetFmAstPresetData" 5 "GetAmAstPresetData" 6 "GetAmPresetData" 7 "GetFmStationListPresetData" ;
VAL_ 501 Dsp_SetRadSeekMode_Rq 15 "Reseved" 14 "ContAutoDown" 0 "Inactive" 1 "SeekOff" 2 "AutoUp" 3 "AutoDown" 4 "ManSingleStepUp" 5 "ManSingleStepDown" 6 "ContManualUp" 7 "ContManualDown" 8 "ScanUp" 9 "ScanDown" 10 "PtySeekUp" 11 "PtySeekDown" 12 "Autostore" 13 "ContAutoUp" ;
VAL_ 501 Dsp_SetCRadioBand_Rq 0 "Inactive" 1 "Fm1" 2 "Fm2" 3 "Fm3" 4 "FmAst" 5 "Am" 6 "AmAst" ;
VAL_ 501 Dsp_FreezeFMSL_Rq 3 "NotUsed" 2 "True" 1 "False" 0 "Inactive" ;
VAL_ 651 TelematicsSrvc_D_St 7 "NotUsed" 6 "NotifyNotActivatedYet" 5 "NotActivatedYet" 4 "NotifyExpired" 3 "Expired" 2 "ExpiringSoon" 1 "Active" 0 "Null" ;
VAL_ 651 EmgcyCallMute_D_Stat 7 "NotUsed4" 6 "NotUsed3" 5 "NotUsed2" 4 "NotUsed1" 3 "ManualEmergencyCallMute" 2 "AutomaticEmergencyCallMute" 1 "EmergencyCallUnmute" 0 "Null" ;
VAL_ 1098 EdmSailMdeOn_B_Stat 1 "On" 0 "Off" ;
VAL_ 1098 EdmMsgTxt_D_Rq 15 "NotUsed_4" 14 "NotUsed_3" 13 "NotUsed_2" 12 "NotUsed_1" 11 "OverallGoodScore" 10 "WorkOnCompliance" 9 "GoodCompliance" 8 "WorkOnGearShifting" 7 "GoodGearShifting" 6 "WorkOnEfficientSpeed" 5 "GoodEfficientSpeed" 4 "WorkOnDeceleration" 3 "GoodDeceleration" 2 "WorkOnAcceleration" 1 "GoodAcceleration" 0 "NoMessage" ;
VAL_ 1098 EdmLamp_D_Dsply 15 "NotUsed_7" 14 "NotUsed_6" 13 "NotUsed_5" 12 "NotUsed_4" 11 "NotUsed_3" 10 "NotUsed_2" 9 "NotUsed_1" 8 "CoastingEngineBrake" 7 "CoastingShiftToNeutral" 6 "FreewayJunction" 5 "Curve2" 4 "Curve1" 3 "SpeedLimit" 2 "Crossing" 1 "FreewayExit" 0 "NoRecommendation" ;
VAL_ 1098 EdmCmplnc_B_Dsply 1 "Yes" 0 "No" ;
VAL_ 1239 CstmDrvMdeChassis_D_Rq 31 "Faulty" 30 "NotUsed17" 29 "NotUsed16" 28 "NotUsed15" 27 "NotUsed14" 26 "NotUsed13" 25 "NotUsed12" 24 "NotUsed11" 23 "NotUsed10" 22 "NotUsed9" 21 "NotUsed8" 20 "NotUsed7" 19 "NotUsed6" 18 "NotUsed5" 17 "NotUsed4" 16 "OnePedalDrive" 15 "DragMode" 14 "RoughRoadMode" 13 "TrackMode" 12 "HighSpeedDesertMode" 11 "TowHaulMode" 10 "RockCrawlMode" 9 "SandMode" 8 "MudAndRutsMode" 7 "LowMuMode" 6 "ComfortAdaptiveMode" 5 "ComfortMode" 4 "SportAdaptiveMode" 3 "SportMode" 2 "EconomyMode" 1 "NormalAdaptiveMode" 0 "NormalMode" ;
VAL_ 1239 CstmDrvMdeHmi2_D_Rq 31 "Faulty" 30 "SelDrvMde31" 29 "SelDrvMde30" 28 "SelDrvMde29" 27 "SelDrvMde28" 26 "SelDrvMde27" 25 "SelDrvMde26" 24 "SelDrvMde25" 23 "SelDrvMde24" 22 "SelDrvMde23" 21 "SelDrvMde22" 20 "SelDrvMde21" 19 "SelDrvMde20" 18 "SelDrvMde19" 17 "SelDrvMde18" 16 "SelDrvMde17" 15 "SelDrvMde16" 14 "SelDrvMde15" 13 "SelDrvMde14" 12 "SelDrvMde13" 11 "SelDrvMde12" 10 "SelDrvMde11" 9 "SelDrvMde10" 8 "SelDrvMde09" 7 "SelDrvMde08" 6 "SelDrvMde07" 5 "SelDrvMde06" 4 "SelDrvMde05" 3 "SelDrvMde04" 2 "SelDrvMde03" 1 "SelDrvMde02" 0 "SelDrvMde01" ;
VAL_ 1239 CstmDrvMdeTracCtl_D_Rq 3 "App_Specific_Off_Mode_3" 2 "App_Specific_Off_Mode_2" 1 "App_Specific_Off_Mode_1" 0 "Default_Mode" ;
VAL_ 1239 SeatOccRearChime_B_Rq 1 "On" 0 "Off" ;
VAL_ 1239 StabBarCnnctLamp_D_Cstm 3 "Fast_Flash" 2 "Slow_Flash" 1 "On" 0 "Off" ;
VAL_ 1239 SelDrvMdeCstmLamp_D_Rq 3 "NotUsed2" 2 "NotUsed1" 1 "On" 0 "Off" ;
VAL_ 1239 SelDrvMdeCstm_D_RqDrv 7 "Faulty" 6 "NotUsed_3" 5 "NotUsed_2" 4 "NotUsed_1" 3 "Recall" 2 "Save" 1 "Activate" 0 "Null" ;
VAL_ 1239 CstmDrvMdeMsgTxt_D_Rq 15 "Message15" 14 "Message14" 13 "Message13" 12 "Message12" 11 "Message11" 10 "Message10" 9 "Message9" 8 "Message8" 7 "Message7" 6 "Message6" 5 "Message5" 4 "Message4" 3 "Message3" 2 "Message2" 1 "Message1" 0 "NoMessage" ;
VAL_ 1239 ActvDrvMdeCstm_D2_Rq 31 "Faulty" 30 "SelDrvMde31" 29 "SelDrvMde30" 28 "SelDrvMde29" 27 "SelDrvMde28" 26 "SelDrvMde27" 25 "SelDrvMde26" 24 "SelDrvMde25" 23 "SelDrvMde24" 22 "SelDrvMde23" 21 "SelDrvMde22" 20 "SelDrvMde21" 19 "SelDrvMde20" 18 "SelDrvMde19" 17 "SelDrvMde18" 16 "SelDrvMde17" 15 "SelDrvMde16" 14 "SelDrvMde15" 13 "SelDrvMde14" 12 "SelDrvMde13" 11 "SelDrvMde12" 10 "SelDrvMde11" 9 "SelDrvMde10" 8 "SelDrvMde09" 7 "SelDrvMde08" 6 "SelDrvMde07" 5 "SelDrvMde06" 4 "SelDrvMde05" 3 "SelDrvMde04" 2 "SelDrvMde03" 1 "SelDrvMde02" 0 "SelDrvMde01" ;
VAL_ 785 BattElecPerf_D2_Actl 7 "NotUsed" 6 "SeverelyLimitedPerformance" 5 "LimitedPerformance" 4 "SeverelyLimPerf_MotorTe" 3 "LimitedPerf_MotorTe" 2 "SeverelyLimPerf_BatteryTe" 1 "LimitedPerf_BatteryTe" 0 "NoMessage" ;
VAL_ 785 RgenAnimation_B_Dsply 1 "Active" 0 "Inactive" ;
VAL_ 785 VehVLimMsgTxt_B_Rq 1 "Yes" 0 "No" ;
VAL_ 785 EcoIdl_D_Stat 3 "NotUsed" 2 "Enabled" 1 "Disabled" 0 "Null" ;
VAL_ 785 DteVehOffst_L_Dsply 8191 "Faulty" 8190 "NoDataExists" ;
VAL_ 785 DteVehOffstMsgTxt_D_Rq 15 "NotUsed_7" 14 "NotUsed_6" 13 "NotUsed_5" 12 "NotUsed_4" 11 "NotUsed_3" 10 "NotUsed_2" 9 "NotUsed_1" 8 "PowerToTheBox" 7 "Payload" 6 "TrailerTowing_Off" 5 "TrailerTowing_On" 4 "TrafficAlongRoute" 3 "ExternalTemperature" 2 "HillyTerrain" 1 "DestinationRoute" 0 "NoMessage" ;
VAL_ 785 PwPckTqRdyChime_B_Rq 3 "NotUsed" 2 "Shutdown" 1 "Startup" 0 "Null" ;
VAL_ 785 BattTracLoThres_D_Stat 7 "NotUsed" 6 "Thres80km_50mi" 5 "Thres50km_31mi" 4 "Thres30km_18mi" 3 "Thres50mi_80km" 2 "Thres30mi_48km" 1 "Thres20mi_32km" 0 "Null" ;
VAL_ 785 BattTracLoMsgTxt_D_Rq 7 "NotUsed_2" 6 "NotUsed_1" 5 "ZeroDteBatteryDepleted" 4 "ClimateLowDteSecondAlert" 3 "ClimateLowDteFirstAlert" 2 "LowDteSecondAlert" 1 "LowDteFirstAlert" 0 "Null" ;
VAL_ 785 BattTracLoSoc_D_Dsply 3 "NotUsed" 2 "ZeroDteDepletedBattery" 1 "LoDte" 0 "Null" ;
VAL_ 785 BattTracLimPerf_D_Dsply 3 "NotUsed" 2 "SeverelyLimitedPerformance" 1 "LimitedPerformance" 0 "NoDisplay" ;
VAL_ 415 LBC3_Opcode 3 "NotUsed" 2 "SetItemIfno_Rq" 1 "GetItemInfo_Rq" 0 "Inactive" ;
VAL_ 332 UreaLvlQlty_D_RqDsply 7 "NotUsed_5" 6 "NotUsed_4" 5 "NotUsed_3" 4 "NotUsed_2" 3 "NotUsed_1" 2 "FlashChime" 1 "On" 0 "Off" ;
VAL_ 332 UreaLvlTxtWarn_D_Rq 15 "NotUsed_4" 14 "NotUsed_3" 13 "NotUsed_2" 12 "NotUsed_1" 11 "System_Error" 10 "Engine_Idled_See_Manual" 9 "Engine_Idled_Upon_Refuel" 8 "Speed_Limited_To_XX_mph" 7 "XXmph_Max_Upon_Restart" 6 "Speed_Limited_To_YY_mph" 5 "YYmph_Max_Upon_Restart" 4 "SpdLimtd_YYmph_In_XXmiles" 3 "ExFlRange_XXMiles_ScndWarn" 2 "Exh_Fluid_Range_XX_Miles" 1 "Exh_Fluid_Under_Half_Full" 0 "Exh_Fluid_Over_Half_Full" ;
VAL_ 332 UreaQltySysWarn_D_Rq 7 "Undefined" 6 "ZZ_Overrides" 5 "EngineIdled" 4 "Engine_Idle_Upon_Refuel" 3 "SPEED_LIMITED_to_YY_mph" 2 "YY_MPH_MAX_UPON_Restart" 1 "CONTAMINATED_ExhFluid" 0 "NoQualityProblem" ;
VAL_ 332 DieslPrtcWarn_D_Rq 15 "NotUsed_4" 14 "NotUsed_3" 13 "NotUsed_2" 12 "NotUsed_1" 11 "OCR_ExhFilterClean_Stopped" 10 "OCR_ExhFilterCleaned" 9 "RgnOff_AtLimit" 8 "RgnOff_OverLoaded" 7 "RgnOff_Loaded" 6 "Exhaust_Filter_Full" 5 "DPF_OverLimit" 4 "DPF_AtLimit" 3 "ExhFilter_Drive_Completed" 2 "Cleaning_Exhaust_Filter" 1 "DPF_OverLoaded" 0 "DPF_Normal_Operation" ;
VAL_ 332 UreaQltyFlg_B_RqDsply 1 "True" 0 "False" ;
VAL_ 332 UreaQltySys_D_RqDsply 7 "Undefined" 6 "ZZ_Overrides" 5 "EngineIdled" 4 "Engine_Idle_Upon_Refuel" 3 "SPEED_LIMITED_to_YY_mph" 2 "YY_MPH_MAX_UPON_Restart" 1 "CONTAMINATED_ExhFluid" 0 "NoQualityProblem" ;
VAL_ 332 UreaLvlTxt_D_RqDsply 15 "NotUsed_4" 14 "NotUsed_3" 13 "NotUsed_2" 12 "NotUsed_1" 11 "System_Error" 10 "Engine_Idled_See_Manual" 9 "Engine_Idled_Upon_Refuel" 8 "Speed_Limited_To_XX_mph" 7 "XXmph_Max_Upon_Restart" 6 "Speed_Limited_To_YY_mph" 5 "YYmph_Max_Upon_Restart" 4 "SpdLimtd_YYmph_In_XXmiles" 3 "ExFlRange_XXMiles_ScndWarn" 2 "Exh_Fluid_Range_XX_Miles" 1 "Exh_Fluid_Under_Half_Full" 0 "Exh_Fluid_Over_Half_Full" ;
VAL_ 636 WifiHtsptFqBand_D_Stat 3 "NotUsed_1" 2 "Band_2" 1 "Band_1" 0 "Null" ;
VAL_ 636 WifiHtspt_D_Falt 15 "Error15" 14 "Error14" 13 "Error13" 12 "Error12" 11 "Error11" 10 "Error10" 9 "Error9" 8 "Error8" 7 "Error7" 6 "Error6" 5 "Error5" 4 "Error4" 3 "Error3" 2 "Error2" 1 "Error1" 0 "Null" ;
VAL_ 636 WifiHtsptCnnct_D_Stat 3 "NotUsed" 2 "Connected" 1 "NotConnected" 0 "Null" ;
VAL_ 636 Telematics_D_Falt 7 "NotUsed_5" 6 "NotUsed_4" 5 "NotUsed_3" 4 "NotUsed_2" 3 "NotUsed_1" 2 "RunTimeError" 1 "ChipsetInitializationFailu" 0 "Null" ;
VAL_ 636 WifiEnbl_D_Stat 3 "NotUsed" 2 "Enable" 1 "Disable" 0 "Null" ;
VAL_ 636 WifiHtsptVisbl_D_Stat 3 "Not  used" 2 "On" 1 "Off" 0 "Null" ;
VAL_ 636 WifiHtsptScrty_D_Stat 3 "NotUsed_1" 2 "Wapi" 1 "Wpa2_Wpa" 0 "Null" ;
VAL_ 636 WifiHtsptEnbl_D_Stat 3 "OnDisabled" 2 "On" 1 "Off" 0 "Null" ;
VAL_ 636 WifiDevcListNew_B_Stat 1 "Available" 0 "NotAvailable" ;
VAL_ 636 WifiDataUsage_D_Stat 3 "PercentDataUsed" 2 "DataPlanExpired" 1 "FreeTrialPeriodWaiting" 0 "Null" ;
VAL_ 636 ModemSigStren_D_Stat 7 "NotUsed_1" 6 "NotDetermined" 5 "FiveBars" 4 "FourBars" 3 "ThreeBars" 2 "TwoBars" 1 "OneBar" 0 "ZeroBars" ;
VAL_ 636 ModemTechnology_D2_Stat 7 "Lte" 6 "HspaPlus" 5 "Umts" 4 "Edge" 3 "Gprs" 2 "Gsm" 1 "NoNetwork" 0 "Null" ;
VAL_ 636 WifiHtsptCrdntl_B_Stat 1 "Available" 0 "NotAvailable" ;
VAL_ 636 WifiHtsptFq_D_Avail 7 "NotUsed_3" 6 "NotUsed_2" 5 "NotUsed_1" 4 "AllAvailable" 3 "Band_2_Only" 2 "Band_1_Only" 1 "AllRestricted" 0 "Null" ;
VAL_ 636 WifiDataUsageOn_D_Stat 3 "NotUsed" 2 "On" 1 "Off" 0 "Null" ;
VAL_ 805 InstFeTripUnit_D_Stat 15 "NotUsed_12" 14 "NotUsed_11" 13 "NotUsed_10" 12 "NotUsed_9" 11 "NotUsed_8" 10 "NotUsed_7" 9 "NotUsed_6" 8 "NotUsed_5" 7 "NotUsed_4" 6 "NotUsed_3" 5 "NotUsed_2" 4 "NotUsed_1" 3 "LiterPer100kilometer" 2 "KilometerPerLiter" 1 "MilePerGallon" 0 "Inactive" ;
VAL_ 804 ConsInstActv_B_Dsply 1 "Active" 0 "Inactive" ;
VAL_ 804 ConsInstUnit_D_Stat 3 "NotUsed" 2 "LiterPerHour" 1 "GallonPerHour" 0 "Inactive" ;
VAL_ 803 DistTripUnit_D_Stat 3 "NotUsed" 2 "Miles" 1 "Kilometers" 0 "Inactive" ;
VAL_ 802 AvgFeTripUnit_D_Stat 15 "NotUsed_12" 14 "NotUsed_11" 13 "NotUsed_10" 12 "NotUsed_9" 11 "NotUsed_8" 10 "NotUsed_7" 9 "NotUsed_6" 8 "NotUsed_5" 7 "NotUsed_4" 6 "NotUsed_3" 5 "NotUsed_2" 4 "NotUsed_1" 3 "LiterPer100kilometer" 2 "KilometerPerLiter" 1 "MilePerGallon" 0 "Inactive" ;
VAL_ 802 AvgFeTrip2Actv_B_Dsply 1 "Active" 0 "Inactive" ;
VAL_ 802 AvgFeTrip1Actv_B_Dsply 1 "Active" 0 "Inactive" ;
VAL_ 802 AvgFeActv_B_Dsply 1 "Active" 0 "Inactive" ;
VAL_ 812 TimerTrip2_T_Dsply 0 "0 second" ;
VAL_ 812 TimerTrip1_T_Dsply 0 "0 second" ;
VAL_ 885 VehStrtInhbt_D_Dsply 15 "NotUsed_12" 14 "NotUsed_11" 13 "NotUsed_10" 12 "NotUsed_9" 11 "NotUsed_8" 10 "NotUsed_7" 9 "NotUsed_6" 8 "NotUsed_5" 7 "NotUsed_4" 6 "FleetPhoneNumber" 5 "FleetGeneral" 4 "OtaSuccess" 3 "PostOtaActivatePermFail" 2 "PostOtaActivateWarning" 1 "DuringOtaActivate" 0 "NoMessage" ;
VAL_ 885 OtaActv_D_Stat 15 "NotUsed_10" 14 "NotUsed_9" 13 "NotUsed_8" 12 "NotUsed_7" 11 "NotUsed_6" 10 "NotUsed_5" 9 "NotUsed_4" 8 "NotUsed_3" 7 "NotUsed_2" 6 "NotUsed_1" 5 "NonInterruptible_Pending" 4 "NonInterruptible_Config" 3 "NonInterruptible_ER" 2 "NonInterruptible_AB" 1 "Interruptible_AB" 0 "NoInVehicleOta" ;
VAL_ 784 TrlrTireTSensRr_D_Stat 3 "Faulty" 2 "HighTempWarning" 1 "Normal" 0 "NotAvailable" ;
VAL_ 784 TrlrTireTSensRm_D_Stat 3 "Faulty" 2 "HighTempWarning" 1 "Normal" 0 "NotAvailable" ;
VAL_ 784 TrlrTireTSensRf_D_Stat 3 "Faulty" 2 "HighTempWarning" 1 "Normal" 0 "NotAvailable" ;
VAL_ 784 TrlrTireTSensLr_D_Stat 3 "Faulty" 2 "HighTempWarning" 1 "Normal" 0 "NotAvailable" ;
VAL_ 784 TrlrTireTSensLm_D_Stat 3 "Faulty" 2 "HighTempWarning" 1 "Normal" 0 "NotAvailable" ;
VAL_ 784 TrlrTireTSensLf_D_Stat 3 "Faulty" 2 "HighTempWarning" 1 "Normal" 0 "NotAvailable" ;
VAL_ 784 TrlrTireTempSys_D_Stat 3 "Faulty" 2 "HighTempWarning" 1 "Normal" 0 "NotSupported" ;
VAL_ 784 TrlrTireRr_T_Actl 255 "NotSupported" 254 "Invalid" ;
VAL_ 784 TrlrTireRm_T_Actl 255 "NotSupported" 254 "Invalid" ;
VAL_ 784 TrlrTireRf_T_Actl 255 "NotSupported" 254 "Invalid" ;
VAL_ 784 TrlrTireLr_T_Actl 255 "NotSupported" 254 "Invalid" ;
VAL_ 784 TrlrTireLm_T_Actl 255 "NotSupported" 254 "Invalid" ;
VAL_ 784 TrlrTireLf_T_Actl 255 "NotSupported" 254 "Invalid" ;
VAL_ 290 WifiHtsptFqBand_D_Rq 3 "NotUsed_1" 2 "Band_2" 1 "Band_1" 0 "Null" ;
VAL_ 290 WifiHtsptTrial_D_RqDrv 3 "NotUsed_1" 2 "StopReminders" 1 "RemindMeLater" 0 "Null" ;
VAL_ 290 WifiHtsptEnbl_D_Rq 3 "Not used" 2 "On" 1 "Off" 0 "Null" ;
VAL_ 290 WifiRemoveDevc_D_Rq 3 "NotUsed_1" 2 "FromBlockedList" 1 "FromConnectedList" 0 "Null" ;
VAL_ 290 WifiHtsptVisbl_D_Rq 3 "Not used" 2 "On" 1 "Off" 0 "Null" ;
VAL_ 290 WifiHtsptMacAddr_B_Rq 1 "Request" 0 "No request" ;
VAL_ 290 WifiDevcList_D_Rq 3 "NoEntry" 2 "BlockedList" 1 "ConnectedList" 0 "Null" ;
VAL_ 290 WifiDataUsage_D_Rq 3 "RetriveDataFromBackend" 2 "RefreshData" 1 "CurrentData" 0 "Null" ;
VAL_ 290 WifiCarrierInfo_B_Rq 1 "Request" 0 "No  request" ;
VAL_ 290 WifiHtsptScrty_D_Rq 3 "NotUsed_1" 2 "Wapi" 1 "Wpa2_Wpa" 0 "Null" ;
VAL_ 554 SeatOccRearMsgTxt_B_Rq 1 "Active" 0 "Null" ;
VAL_ 554 Frt_Btn_Status_1st_2 63 "NotUsed_5" 62 "NotUsed_4" 61 "NotUsed_3" 60 "NotUsed_2" 59 "NotUsed_1" 58 "AUTO_Dec_Pressed" 57 "AUTO_Inc_Pressed" 56 "AUTO_Hi_Pressed" 55 "AUTO_Med_Pressed" 54 "AUTO_Lo_Pressed" 53 "RHS_Cld_Seat3_Pressed" 52 "RHS_Cld_Seat2_Pressed" 51 "RHS_Cld_Seat1_Pressed" 50 "LHS_Cld_Seat3_Pressed" 49 "LHS_Cld_Seat2_Pressed" 48 "LHS_Cld_Seat1_Pressed" 47 "RHS_Auto_Seat_Pressed" 46 "RHS_Htd_Seat3_Pressed" 45 "RHS_Htd_Seat2_Pressed" 44 "RHS_Htd_Seat1_Pressed" 43 "RHS_Seat_Off_Pressed" 42 "LHS_Auto_Seat_Pressed" 41 "LHS_Htd_Seat3_Pressed" 40 "LHS_Htd_Seat2_Pressed" 39 "LHS_Htd_Seat1_Pressed" 38 "LHS_Seat_Off_Pressed" 37 "DrvrFcsdMde_Pressed" 36 "MdeMnu_Pressed" 35 "AAR_Pressed" 34 "Heat_Pressed" 33 "RearMnu_Pressed" 32 "FrontMnu_Pressed" 31 "Defrost_Pressed" 30 "Htd_Strg_Whl_Pressed" 29 "RHS_Cld_Seat_Pressed" 28 "LHS_Cld_Seat_Pressed" 27 "RHS_Htd_Seat_Pressed" 26 "LHS_Htd_Seat_Pressed" 25 "Max_Defrost_Pressed" 24 "My_Temp_Pressed" 23 "Front_Defrost_Pressed" 22 "Rear_Defrost_Pressed" 21 "Pnl_Flr_Ws_Pressed" 20 "Pnl_Ws_Pressed" 19 "Windscreen_Pressed" 18 "Htd_Frt_Wsh_Pressed" 17 "Auto_Recirc_Pressed" 16 "Outside_Pressed" 15 "Recirc_Pressed" 14 "Max_AC_Pressed" 13 "AUTO_Pressed" 12 "Blwr_Dec_Pressed" 11 "Blwr_Inc_Pressed" 10 "RHS_Temp_Dec_Pressed" 9 "RHS_Temp_Inc_Pressed" 8 "LHS_Temp_Dec_Pressed" 7 "LHS_Temp_Inc_Pressed" 6 "Dual_Pressed" 5 "AC_Pressed" 4 "Floor_Ws_Pressed" 3 "Floor_Pressed" 2 "Panel_Floor_Pressed" 1 "Panel_Pressed" 0 "None_Pressed" ;
VAL_ 554 Drv_Set_Tmp2 31 "HI" 30 "29_5" 29 "29_0" 28 "28_5" 27 "28_0" 26 "27_5" 25 "27_0" 24 "26_5" 23 "26_0" 22 "25_5" 21 "25_0" 20 "24_5" 19 "24_0" 18 "23_5" 17 "23_0" 16 "22_5" 15 "22_0" 14 "21_5" 13 "21_0" 12 "20_5" 11 "20_0" 10 "19_5" 9 "19_0" 8 "18_5" 7 "18_0" 6 "17_5" 5 "17_0" 4 "16_5" 3 "16_0" 2 "15_5" 1 "LO" 0 "No_Request" ;
VAL_ 554 DrvHazrdModel_D_St 15 "NotUsed_13" 14 "NotUsed_12" 13 "NotUsed_11" 12 "NotUsed_10" 11 "NotUsed_9" 10 "NotUsed_8" 9 "NotUsed_7" 8 "NotUsed_6" 7 "NotUsed_5" 6 "NotUsed_4" 5 "NotUsed_3" 4 "NotUsed_2" 3 "NotUsed_1" 2 "TpegTec" 1 "DenmEm" 0 "None" ;
VAL_ 554 DrvHazrd_D_St 7 "NotUsed_1" 6 "Suspended" 5 "Available" 4 "NoService" 3 "NoSession" 2 "bAllowOff" 1 "bSAllowOff" 0 "NoStatus" ;
VAL_ 554 PtWakeupActv1_B_Rq 1 "Wake_up_Powertrain_via_HW" 0 "Don_t_Wake_Up_Powertrain" ;
VAL_ 419 MK_SpeedValue_Rq 31 "mph90" 30 "mph85" 29 "mph80" 28 "mph75" 27 "mph70" 26 "mph65" 25 "mph60" 24 "mph55" 23 "mph50" 22 "mph45" 21 "mph40" 20 "Kmh165" 19 "Kmh160" 18 "Kmh155" 17 "Kmh150" 16 "Kmh145" 15 "Kmh140" 14 "Kmh135" 13 "Kmh130" 12 "Kmh125" 11 "Kmh120" 10 "Kmh115" 9 "Kmh110" 8 "Kmh105" 7 "Kmh100" 6 "kmh95" 5 "kmh90" 4 "kmh85" 3 "kmh80" 2 "kmh75" 1 "kmh70" 0 "Off" ;
VAL_ 419 MK_SpeedSetting_Rq 15 "Reserved_last" 3 "Reserved" 2 "SpeedMinder" 1 "SpeedLimit" 0 "Inactive" ;
VAL_ 419 MK_ResetAllUserKeys_Rq 1 "ResetAllKeys" 0 "Inactive" ;
VAL_ 419 MK_MyKeySystemInfo_Rq 1 "GetData" 0 "Inactive" ;
VAL_ 419 MK_ESCRestrictConf_Rq 2 "On" 1 "Off" 0 "Inactive" ;
VAL_ 419 MK_ECalRestrictConf_Rq 2 "On" 1 "Off" 0 "Inactive" ;
VAL_ 419 MK_DNDRestrictConf_Rq 2 "On" 1 "Off" 0 "Inactive" ;
VAL_ 419 MK_CreateMyKey_Rq 1 "Create" 0 "Inactive" ;
VAL_ 419 MK_AudioLimitConfig_Rq 2 "On" 1 "Off" 0 "Inactive" ;
VAL_ 419 MK_ACSRestrictConf_Rq 2 "On" 1 "Off" 0 "Inactive" ;
SIG_GROUP_ 885 Profile1A_SigGroup_HS3_375 1 : VehStrtInhbt_T_Dsply VehStrtInhbt_D_Dsply OtaActv_D_Stat;
